VERSION ""

NS_ :

BS_:

BU_: Sound_A Ladegeraet_PAG_PF Motor_EDC17_Pirol PSM_Ant_Derivate GW_Routing_Derivate GW_Applikation_Derivate BMS_Hybrid Getriebe_Derivate LEH_Hybrid Motor_MED17_Hybrid Sound_I Tool Airbag Waehlhebel

BO_ 1446 OBC_Komponentenfehler: 8 Ladegeraet_PAG_PF
 SG_ OBC_KomponentenFehler_01 : 0|2@1+ (1,0) [0|3] ""  BMS_Hybrid
 SG_ OBC_KomponentenFehler_02 : 2|2@1+ (1,0) [0|3] ""  BMS_Hybrid
 SG_ OBC_KomponentenFehler_03 : 4|2@1+ (1,0) [0|3] ""  BMS_Hybrid
 SG_ OBC_KomponentenFehler_04 : 6|2@1+ (1,0) [0|3] ""  BMS_Hybrid
 SG_ OBC_KomponentenFehler_05 : 8|2@1+ (1,0) [0|3] ""  BMS_Hybrid
 SG_ OBC_KomponentenFehler_06 : 10|2@1+ (1,0) [0|3] ""  BMS_Hybrid
 SG_ OBC_KomponentenFehler_07 : 12|2@1+ (1,0) [0|3] ""  BMS_Hybrid
 SG_ OBC_KomponentenFehler_08 : 14|2@1+ (1,0) [0|3] ""  BMS_Hybrid
 SG_ OBC_KomponentenFehler_09 : 16|2@1+ (1,0) [0|3] ""  BMS_Hybrid
 SG_ OBC_KomponentenFehler_10 : 18|2@1+ (1,0) [0|3] ""  BMS_Hybrid
 SG_ OBC_KomponentenFehler_11 : 20|2@1+ (1,0) [0|3] ""  BMS_Hybrid
 SG_ OBC_KomponentenFehler_12 : 22|2@1+ (1,0) [0|3] ""  BMS_Hybrid
 SG_ OBC_KomponentenFehler_13 : 24|2@1+ (1,0) [0|3] ""  BMS_Hybrid
 SG_ OBC_KomponentenFehler_14 : 26|2@1+ (1,0) [0|3] ""  BMS_Hybrid
 SG_ OBC_KomponentenFehler_15 : 28|2@1+ (1,0) [0|3] ""  BMS_Hybrid
 SG_ OBC_KomponentenFehler_16 : 30|2@1+ (1,0) [0|3] ""  BMS_Hybrid
 SG_ OBC_KomponentenFehler_17 : 32|2@1+ (1,0) [0|3] ""  BMS_Hybrid
 SG_ OBC_KomponentenFehler_18 : 34|2@1+ (1,0) [0|3] ""  BMS_Hybrid
 SG_ OBC_KomponentenFehler_19 : 36|2@1+ (1,0) [0|3] ""  BMS_Hybrid
 SG_ OBC_KomponentenFehler_20 : 38|2@1+ (1,0) [0|3] ""  BMS_Hybrid
 SG_ OBC_KomponentenFehler_21 : 40|2@1+ (1,0) [0|3] ""  BMS_Hybrid
 SG_ OBC_KomponentenFehler_22 : 42|2@1+ (1,0) [0|3] ""  BMS_Hybrid
 SG_ OBC_KomponentenFehler_23 : 44|2@1+ (1,0) [0|3] ""  BMS_Hybrid
 SG_ OBC_KomponentenFehler_24 : 46|2@1+ (1,0) [0|3] ""  BMS_Hybrid
 SG_ OBC_KomponentenFehler_25 : 48|2@1+ (1,0) [0|3] ""  BMS_Hybrid
 SG_ OBC_KomponentenFehler_26 : 50|2@1+ (1,0) [0|3] ""  BMS_Hybrid
 SG_ OBC_KomponentenFehler_27 : 52|2@1+ (1,0) [0|3] ""  BMS_Hybrid
 SG_ OBC_KomponentenFehler_28 : 54|2@1+ (1,0) [0|3] ""  BMS_Hybrid
 SG_ OBC_KomponentenFehler_29 : 56|2@1+ (1,0) [0|3] ""  BMS_Hybrid
 SG_ OBC_KomponentenFehler_30 : 58|2@1+ (1,0) [0|3] ""  BMS_Hybrid
 SG_ OBC_KomponentenFehler_31 : 60|2@1+ (1,0) [0|3] ""  BMS_Hybrid
 SG_ OBC_KomponentenFehler_32 : 62|2@1+ (1,0) [0|3] ""  BMS_Hybrid

BO_ 1445 OBC_CALID_CVN: 8 Ladegeraet_PAG_PF
 SG_ OBC_CVN_VLD : 7|1@1+ (1,0) [0|1] ""  BMS_Hybrid
 SG_ OBC_CALID_Index_01 m0 : 8|8@1+ (1,0) [0|255] ""  BMS_Hybrid
 SG_ OBC_CALID_Index_05 m1 : 8|8@1+ (1,0) [0|255] ""  BMS_Hybrid
 SG_ OBC_CALID_Index_09 m2 : 8|8@1+ (1,0) [0|255] ""  BMS_Hybrid
 SG_ OBC_CALID_Index_13 m3 : 8|8@1+ (1,0) [0|255] ""  BMS_Hybrid
 SG_ OBC_CALID_Index_02 m0 : 16|8@1+ (1,0) [0|255] ""  BMS_Hybrid
 SG_ OBC_CALID_Index_06 m1 : 16|8@1+ (1,0) [0|255] ""  BMS_Hybrid
 SG_ OBC_CALID_Index_10 m2 : 16|8@1+ (1,0) [0|255] ""  BMS_Hybrid
 SG_ OBC_CALID_Index_14 m3 : 16|8@1+ (1,0) [0|255] ""  BMS_Hybrid
 SG_ OBC_CALID_Index_03 m0 : 24|8@1+ (1,0) [0|255] ""  BMS_Hybrid
 SG_ OBC_CALID_Index_07 m1 : 24|8@1+ (1,0) [0|255] ""  BMS_Hybrid
 SG_ OBC_CALID_Index_11 m2 : 24|8@1+ (1,0) [0|255] ""  BMS_Hybrid
 SG_ OBC_CALID_Index_15 m3 : 24|8@1+ (1,0) [0|255] ""  BMS_Hybrid
 SG_ OBC_CALID_Index_04 m0 : 32|8@1+ (1,0) [0|255] ""  BMS_Hybrid
 SG_ OBC_CALID_Index_08 m1 : 32|8@1+ (1,0) [0|255] ""  BMS_Hybrid
 SG_ OBC_CALID_Index_12 m2 : 32|8@1+ (1,0) [0|255] ""  BMS_Hybrid
 SG_ OBC_CALID_Index_16 m3 : 32|8@1+ (1,0) [0|255] ""  BMS_Hybrid
 SG_ OBC_CVN_Byte_1 m0 : 40|8@1+ (1,0) [0|255] ""  BMS_Hybrid
 SG_ OBC_CVN_Byte_2 m1 : 40|8@1+ (1,0) [0|255] ""  BMS_Hybrid
 SG_ OBC_CVN_Byte_3 m2 : 40|8@1+ (1,0) [0|255] ""  BMS_Hybrid
 SG_ OBC_CALID_CVN_MUX M : 0|2@1+ (1,0) [0|3] ""  BMS_Hybrid
 SG_ OBC_CVN_Byte_4 m3 : 40|8@1+ (1,0) [0|255] ""  BMS_Hybrid

BO_ 1666 CCP_LE_CRO_01: 8 Tool
 SG_ CCP_LE_CRO_01_Data : 0|64@1+ (1,0) [0|1] ""  LEH_Hybrid

BO_ 2617239041 CCP_EMotor_01_DTO_01: 8 LEH_Hybrid
 SG_ CCP_LE_DTO_01_Data : 0|64@1+ (1,0) [0|1] ""  Tool

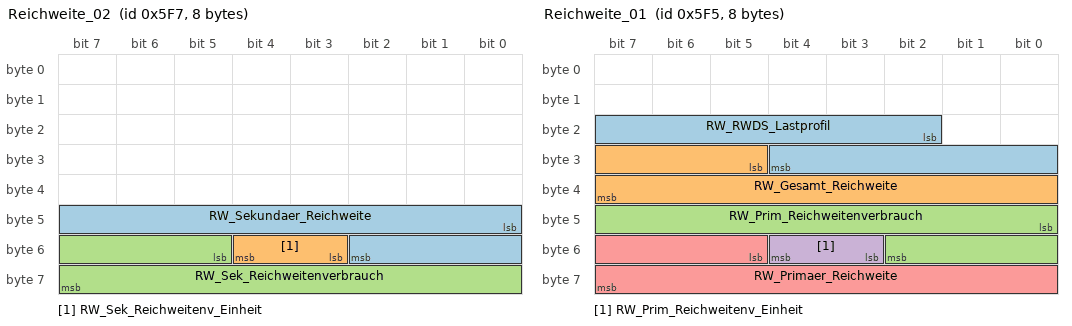
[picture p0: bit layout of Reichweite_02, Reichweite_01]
BO_ 1527 Reichweite_02: 8 BMS_Hybrid
 SG_ RW_Sekundaer_Reichweite : 40|11@1+ (1,0) [0|2044] "Unit_KiloMeter"  GW_Routing_Derivate
 SG_ RW_Sek_Reichweitenv_Einheit : 51|2@1+ (1,0) [0|3] ""  GW_Routing_Derivate
 SG_ RW_Sek_Reichweitenverbrauch : 53|11@1+ (0.1,0) [0|204.4] ""  GW_Routing_Derivate

BO_ 1525 Reichweite_01: 8 BMS_Hybrid
 SG_ RW_RWDS_Lastprofil : 18|11@1+ (1,0) [0|2045] "Unit_Amper"  GW_Routing_Derivate
 SG_ RW_Gesamt_Reichweite : 29|11@1+ (1,0) [0|2044] "Unit_KiloMeter"  GW_Routing_Derivate
 SG_ RW_Prim_Reichweitenverbrauch : 40|11@1+ (0.1,0) [0|204.4] ""  GW_Routing_Derivate
 SG_ RW_Prim_Reichweitenv_Einheit : 51|2@1+ (1,0) [0|3] ""  GW_Routing_Derivate
 SG_ RW_Primaer_Reichweite : 53|11@1+ (1,0) [0|2044] "Unit_KiloMeter"  GW_Routing_Derivate

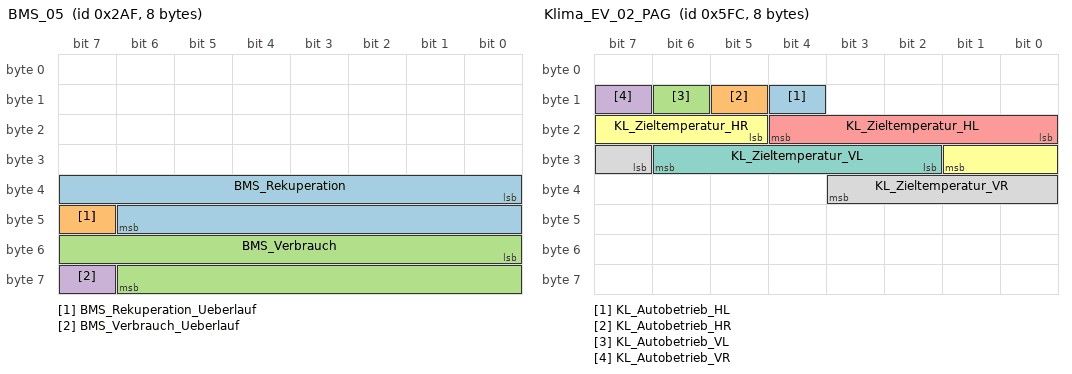
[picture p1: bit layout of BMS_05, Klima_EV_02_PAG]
BO_ 687 BMS_05: 8 BMS_Hybrid
 SG_ BMS_Rekuperation : 32|15@1+ (10,0) [0|327670] "Unit_WattSecond"  GW_Routing_Derivate
 SG_ BMS_Rekuperation_Ueberlauf : 47|1@1+ (1,0) [0|1] ""  GW_Routing_Derivate
 SG_ BMS_Verbrauch : 48|15@1+ (10,0) [0|327670] "Unit_WattSecond"  GW_Routing_Derivate
 SG_ BMS_Verbrauch_Ueberlauf : 63|1@1+ (1,0) [0|1] ""  GW_Routing_Derivate

BO_ 1532 Klima_EV_02_PAG: 8 GW_Routing_Derivate
 SG_ KL_Autobetrieb_HL : 12|1@1+ (1,0) [0|1] ""  BMS_Hybrid
 SG_ KL_Autobetrieb_HR : 13|1@1+ (1,0) [0|1] ""  BMS_Hybrid
 SG_ KL_Autobetrieb_VL : 14|1@1+ (1,0) [0|1] ""  BMS_Hybrid
 SG_ KL_Autobetrieb_VR : 15|1@1+ (1,0) [0|1] ""  BMS_Hybrid
 SG_ KL_Zieltemperatur_HL : 16|5@1+ (0.5,15.5) [16|29.5] "Unit_DegreCelsi"  BMS_Hybrid
 SG_ KL_Zieltemperatur_HR : 21|5@1+ (0.5,15.5) [16|29.5] "Unit_DegreCelsi"  BMS_Hybrid
 SG_ KL_Zieltemperatur_VL : 26|5@1+ (0.5,15.5) [16|29.5] "Unit_DegreCelsi"  BMS_Hybrid
 SG_ KL_Zieltemperatur_VR : 31|5@1+ (0.5,15.5) [16|29.5] "Unit_DegreCelsi"  BMS_Hybrid

BO_ 1788 NMH_Ladegeraet: 7 Ladegeraet_PAG_PF
 SG_ NMH_Ladegeraet_Start_1 : 0|1@1+ (1,0) [0|1] ""  Motor_MED17_Hybrid,GW_Applikation_Derivate,Getriebe_Derivate,LEH_Hybrid,BMS_Hybrid
 SG_ NMH_Ladegeraet_Start_2 : 1|1@1+ (1,0) [0|1] "" Vector__XXX
 SG_ NMH_Ladegeraet_Normal_Mode_1 : 2|1@1+ (1,0) [0|1] "" Vector__XXX
 SG_ NMH_Ladegeraet_Normal_Mode_2 : 3|1@1+ (1,0) [0|1] "" Vector__XXX
 SG_ NMH_Ladegeraet_Car_WakeUp : 6|1@1+ (1,0) [0|1] "" Vector__XXX
 SG_ NMH_Ladegeraet_Per_WakeUp : 8|5@1+ (1,0) [0|31] "" Vector__XXX
 SG_ NMH_Ladegeraet_Fkt_WakeUp : 13|3@1+ (1,0) [0|7] "" Vector__XXX
 SG_ NMH_Ladegeraet_Klemme_15 : 16|1@1+ (1,0) [0|1] "" Vector__XXX
 SG_ NMH_Ladegeraet_Diagnose : 17|1@1+ (1,0) [0|1] "" Vector__XXX
 SG_ NMH_Ladegeraet_MindestAktivZeit : 18|1@1+ (1,0) [0|1] "" Vector__XXX
 SG_ NMH_Ladegeraet_Signalfehler : 32|1@1+ (1,0) [0|1] "" Vector__XXX
 SG_ NMH_Ladegeraet_TimeOut_Fehler : 33|1@1+ (1,0) [0|1] "" Vector__XXX
 SG_ NMH_Ladegeraet_CAN_Diag_deaktiv : 34|1@1+ (1,0) [0|1] "" Vector__XXX
 SG_ NMH_Ladegeraet_KompSchutz : 35|1@1+ (1,0) [0|1] "" Vector__XXX
 SG_ NMH_Ladegeraet_Mute_Mode : 36|1@1+ (1,0) [0|1] "" Vector__XXX
 SG_ NMH_Ladegeraet_Transport_Mode : 37|1@1+ (1,0) [0|1] "" Vector__XXX
 SG_ NMH_Ladegeraet_Abschaltstufe_000 : 38|1@1+ (1,0) [0|1] "" Vector__XXX
 SG_ NMH_Ladegeraet_Eindraht_Fehler : 39|1@1+ (1,0) [0|1] "" Vector__XXX
 SG_ NMH_Ladegeraet_Lokalaktiv : 48|1@1+ (1,0) [0|1] "" Vector__XXX
 SG_ NMH_Ladegeraet_Subsystemaktiv : 49|1@1+ (1,0) [0|1] "" Vector__XXX

BO_ 1966 ISO_Ladegeraet_Resp: 8 Ladegeraet_PAG_PF
 SG_ ISO_Ladegeraet_Resp_Data : 0|64@1+ (1,0) [0|4294967295] ""  GW_Routing_Derivate

BO_ 1860 ISO_Ladegeraet_Req: 8 GW_Routing_Derivate
 SG_ ISO_Ladegeraet_Req_Data : 0|64@1+ (1,0) [0|4294967295] ""  Ladegeraet_PAG_PF

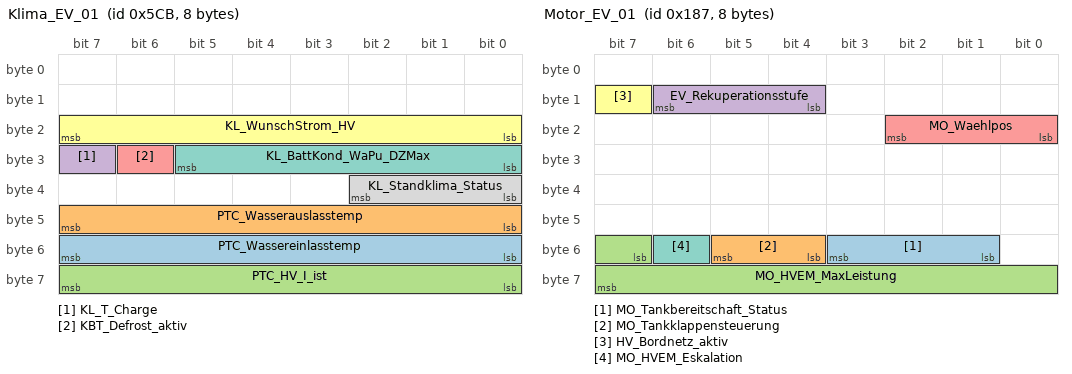
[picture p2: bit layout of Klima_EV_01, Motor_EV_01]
BO_ 1483 Klima_EV_01: 8 GW_Routing_Derivate
 SG_ PTC_Wassereinlasstemp : 48|8@1+ (1,-50) [-50|203] "Unit_DegreCelsi"  BMS_Hybrid
 SG_ PTC_Wasserauslasstemp : 40|8@1+ (1,-50) [-50|203] "Unit_DegreCelsi"  BMS_Hybrid
 SG_ PTC_HV_I_ist : 56|8@1+ (0.25,0) [0|63.25] "Unit_Amper"  Motor_MED17_Hybrid,BMS_Hybrid,Ladegeraet_PAG_PF
 SG_ KL_T_Charge : 31|1@1+ (1,0) [0|1] "" Vector__XXX
 SG_ KBT_Defrost_aktiv : 30|1@1+ (1,0) [0|1] ""  BMS_Hybrid
 SG_ KL_WunschStrom_HV : 16|8@1+ (0.25,0) [0|63.25] "Unit_Amper" Vector__XXX
 SG_ KL_BattKond_WaPu_DZMax : 24|6@1+ (2,0) [0|100] "Unit_PerCent"  BMS_Hybrid
 SG_ KL_Standklima_Status : 32|3@1+ (1,0) [0|7] ""  Ladegeraet_PAG_PF

BO_ 899 Charisma_05: 8 GW_Routing_Derivate
 SG_ CHA_Ziel_FahrPr_BMS : 12|3@1+ (1,0) [0|7] ""  BMS_Hybrid

BO_ 1518 Gateway_31_PAG: 8 GW_Routing_Derivate
 SG_ KL_T_STH : 28|1@1+ (1,0) [0|1] ""  Ladegeraet_PAG_PF
 SG_ Klima_08_PAG_alt : 3|1@1+ (1,0) [0|1] ""  Ladegeraet_PAG_PF

BO_ 391 Motor_EV_01: 8 Motor_MED17_Hybrid
 SG_ MO_Tankbereitschaft_Status : 49|3@1+ (1,0) [0|7] "" Vector__XXX
 SG_ MO_Tankklappensteuerung : 52|2@1+ (1,0) [0|3] "" Vector__XXX
 SG_ MO_HVEM_MaxLeistung : 55|9@1+ (50,0) [0|25450] "Unit_Watt"  GW_Applikation_Derivate
 SG_ EV_Rekuperationsstufe : 12|3@1+ (1,0) [0|7] "" Vector__XXX
 SG_ MO_Waehlpos : 16|3@1+ (1,0) [0|7] "" Vector__XXX
 SG_ HV_Bordnetz_aktiv : 15|1@1+ (1,0) [0|1] ""  Ladegeraet_PAG_PF,GW_Applikation_Derivate
 SG_ MO_HVEM_Eskalation : 54|1@1+ (1,0) [0|1] ""  GW_Applikation_Derivate

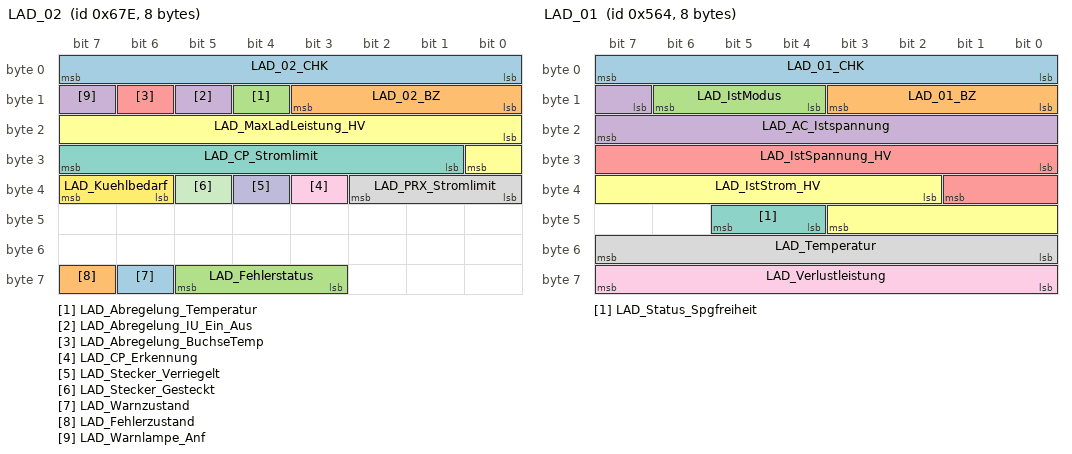
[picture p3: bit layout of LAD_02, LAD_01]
BO_ 1662 LAD_02: 8 Ladegeraet_PAG_PF
 SG_ LAD_02_CHK : 0|8@1+ (1,0) [0|255] ""  GW_Routing_Derivate
 SG_ LAD_02_BZ : 8|4@1+ (1,0) [0|15] ""  GW_Routing_Derivate
 SG_ LAD_Abregelung_Temperatur : 12|1@1+ (1,0) [0|1] ""  GW_Routing_Derivate
 SG_ LAD_Abregelung_IU_Ein_Aus : 13|1@1+ (1,0) [0|1] ""  GW_Routing_Derivate
 SG_ LAD_Abregelung_BuchseTemp : 14|1@1+ (1,0) [0|1] ""  GW_Routing_Derivate
 SG_ LAD_MaxLadLeistung_HV : 16|9@1+ (100,0) [0|50900] "Unit_Watt"  GW_Routing_Derivate,GW_Applikation_Derivate
 SG_ LAD_CP_Stromlimit : 25|7@1+ (0.5,0) [0|62.5] "Unit_Amper"  GW_Routing_Derivate
 SG_ LAD_PRX_Stromlimit : 32|3@1+ (1,0) [0|7] ""  GW_Routing_Derivate
 SG_ LAD_CP_Erkennung : 35|1@1+ (1,0) [0|1] ""  GW_Routing_Derivate
 SG_ LAD_Stecker_Verriegelt : 36|1@1+ (1,0) [0|1] ""  GW_Routing_Derivate
 SG_ LAD_Stecker_Gesteckt : 37|1@1+ (1,0) [0|1] ""  GW_Routing_Derivate
 SG_ LAD_Kuehlbedarf : 38|2@1+ (1,0) [0|3] ""  GW_Routing_Derivate
 SG_ LAD_Warnzustand : 62|1@1+ (1,0) [0|1] ""  GW_Routing_Derivate
 SG_ LAD_Fehlerzustand : 63|1@1+ (1,0) [0|1] ""  GW_Routing_Derivate
 SG_ LAD_Fehlerstatus : 59|3@1+ (1,0) [0|7] ""  GW_Routing_Derivate
 SG_ LAD_Warnlampe_Anf : 15|1@1+ (1,0) [0|1] ""  GW_Routing_Derivate

BO_ 1380 LAD_01: 8 Ladegeraet_PAG_PF
 SG_ LAD_01_CHK : 0|8@1+ (1,0) [0|255] ""  GW_Routing_Derivate
 SG_ LAD_01_BZ : 8|4@1+ (1,0) [0|15] ""  GW_Routing_Derivate
 SG_ LAD_IstModus : 12|3@1+ (1,0) [0|7] ""  GW_Applikation_Derivate,GW_Routing_Derivate
 SG_ LAD_AC_Istspannung : 15|9@1+ (1,0) [0|509] "Unit_Volt"  GW_Routing_Derivate,GW_Applikation_Derivate
 SG_ LAD_IstSpannung_HV : 24|10@1+ (1,0) [0|1021] "Unit_Volt"  GW_Routing_Derivate
 SG_ LAD_IstStrom_HV : 34|10@1+ (0.2,-102) [-102|102.2] "Unit_Amper"  GW_Applikation_Derivate,GW_Routing_Derivate
 SG_ LAD_Status_Spgfreiheit : 44|2@1+ (1,0) [0|3] ""  GW_Routing_Derivate
 SG_ LAD_Temperatur : 48|8@1+ (1,-40) [-40|213] "Unit_DegreCelsi"  GW_Routing_Derivate
 SG_ LAD_Verlustleistung : 56|8@1+ (20,0) [0|5060] "Unit_Watt"  GW_Routing_Derivate

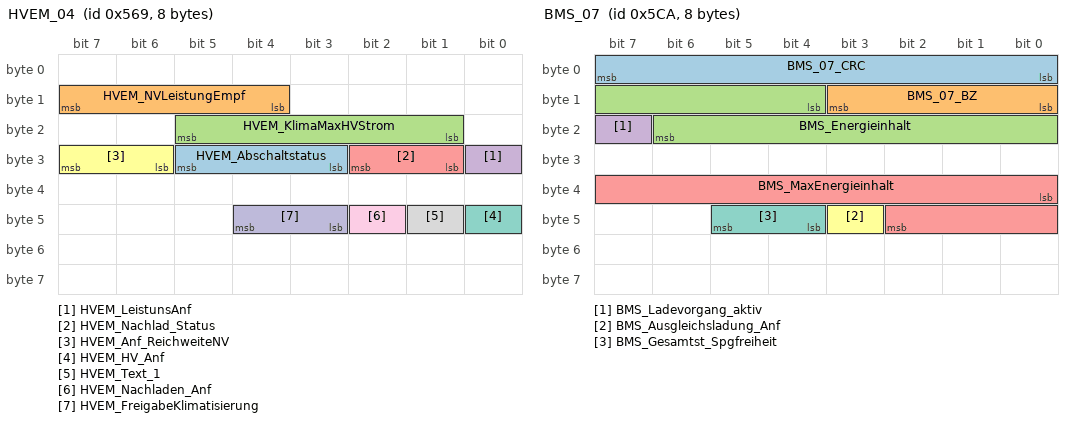
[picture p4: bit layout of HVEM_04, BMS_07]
BO_ 1385 HVEM_04: 8 GW_Applikation_Derivate
 SG_ HVEM_Abschaltstatus : 27|3@1+ (1,0) [0|7] ""  Ladegeraet_PAG_PF
 SG_ HVEM_NVLeistungEmpf : 12|4@1+ (100,0) [0|1500] "Unit_Watt" Vector__XXX
 SG_ HVEM_KlimaMaxHVStrom : 17|5@1+ (1,0) [0|31] "Unit_Amper" Vector__XXX
 SG_ HVEM_LeistunsAnf : 24|1@1+ (1,0) [0|1] "" Vector__XXX
 SG_ HVEM_Nachlad_Status : 25|2@1+ (1,0) [0|3] "" Vector__XXX
 SG_ HVEM_Anf_ReichweiteNV : 30|2@1+ (1,0) [0|3] "" Vector__XXX
 SG_ HVEM_HV_Anf : 40|1@1+ (1,0) [0|1] ""  Motor_MED17_Hybrid
 SG_ HVEM_Text_1 : 41|1@1+ (1,0) [0|1] "" Vector__XXX
 SG_ HVEM_Nachladen_Anf : 42|1@1+ (1,0) [0|1] ""  Ladegeraet_PAG_PF
 SG_ HVEM_FreigabeKlimatisierung : 43|2@1+ (1,0) [0|3] ""  BMS_Hybrid

BO_ 1482 BMS_07: 8 BMS_Hybrid
 SG_ BMS_07_CRC : 0|8@1+ (1,0) [0|255] ""  GW_Routing_Derivate
 SG_ BMS_07_BZ : 8|4@1+ (1,0) [0|15] ""  GW_Routing_Derivate
 SG_ BMS_Energieinhalt : 12|11@1+ (50,0) [0|102250] "Unit_WattHour"  GW_Routing_Derivate
 SG_ BMS_Ladevorgang_aktiv : 23|1@1+ (1,0) [0|1] ""  GW_Routing_Derivate
 SG_ BMS_MaxEnergieinhalt : 32|11@1+ (50,0) [0|102250] ""  GW_Routing_Derivate
 SG_ BMS_Ausgleichsladung_Anf : 43|1@1+ (1,0) [0|1] ""  GW_Routing_Derivate
 SG_ BMS_Gesamtst_Spgfreiheit : 44|2@1+ (1,0) [0|3] ""  GW_Routing_Derivate

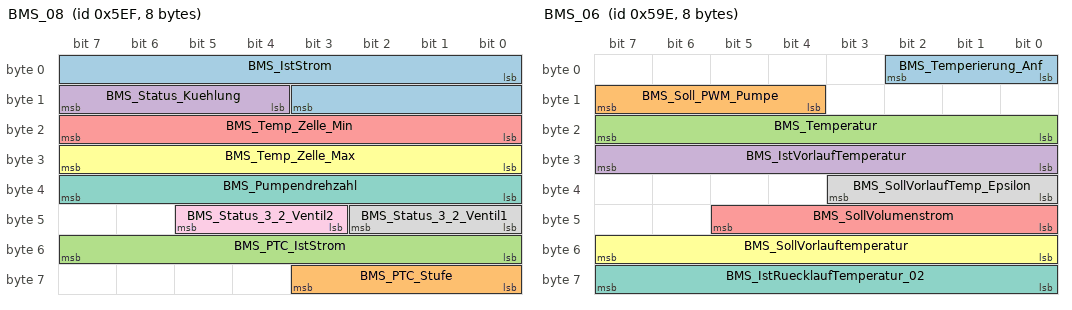
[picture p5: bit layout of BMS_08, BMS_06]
BO_ 1519 BMS_08: 8 BMS_Hybrid
 SG_ BMS_IstStrom : 0|12@1+ (0.25,-511) [-511|512.25] "Unit_Amper"  GW_Applikation_Derivate,GW_Routing_Derivate
 SG_ BMS_PTC_Stufe : 56|4@1+ (10,0) [0|100] "Unit_PerCent"  GW_Routing_Derivate
 SG_ BMS_PTC_IstStrom : 48|8@1+ (0.1,0) [0|25.2] "Unit_Amper"  Motor_MED17_Hybrid,GW_Applikation_Derivate,GW_Routing_Derivate
 SG_ BMS_Status_Kuehlung : 12|4@1+ (1,0) [0|15] ""  GW_Routing_Derivate,GW_Applikation_Derivate
 SG_ BMS_Temp_Zelle_Min : 16|8@1+ (0.5,-40) [-40|86.5] "Unit_DegreCelsi"  GW_Routing_Derivate
 SG_ BMS_Temp_Zelle_Max : 24|8@1+ (0.5,-40) [-40|86.5] "Unit_DegreCelsi"  GW_Routing_Derivate
 SG_ BMS_Pumpendrehzahl : 32|8@1+ (0.5,0) [0|100] "Unit_PerCent"  GW_Routing_Derivate
 SG_ BMS_Status_3_2_Ventil1 : 40|3@1+ (1,0) [0|7] ""  GW_Routing_Derivate
 SG_ BMS_Status_3_2_Ventil2 : 43|3@1+ (1,0) [0|7] ""  GW_Routing_Derivate

BO_ 1438 BMS_06: 8 BMS_Hybrid
 SG_ BMS_Temperierung_Anf : 0|3@1+ (1,0) [0|7] ""  GW_Routing_Derivate
 SG_ BMS_Soll_PWM_Pumpe : 12|4@1+ (10,0) [0|100] "Unit_PerCent"  GW_Routing_Derivate
 SG_ BMS_Temperatur : 16|8@1+ (0.5,-40) [-40|86.5] "Unit_DegreCelsi"  GW_Routing_Derivate
 SG_ BMS_IstVorlaufTemperatur : 24|8@1+ (0.5,-40) [-40|86.5] "Unit_DegreCelsi"  GW_Routing_Derivate
 SG_ BMS_SollVolumenstrom : 40|6@1+ (1,0) [0|61] ""  GW_Routing_Derivate
 SG_ BMS_SollVorlauftemperatur : 48|8@1+ (0.5,-40) [-40|86.5] "Unit_DegreCelsi"  GW_Routing_Derivate
 SG_ BMS_IstRuecklaufTemperatur_02 : 56|8@1+ (0.5,-40) [-40|86.5] "Unit_DegreCelsi"  GW_Routing_Derivate
 SG_ BMS_SollVorlaufTemp_Epsilon : 32|4@1+ (2,0) [0|30] "Unit_DegreCelsi"  GW_Routing_Derivate

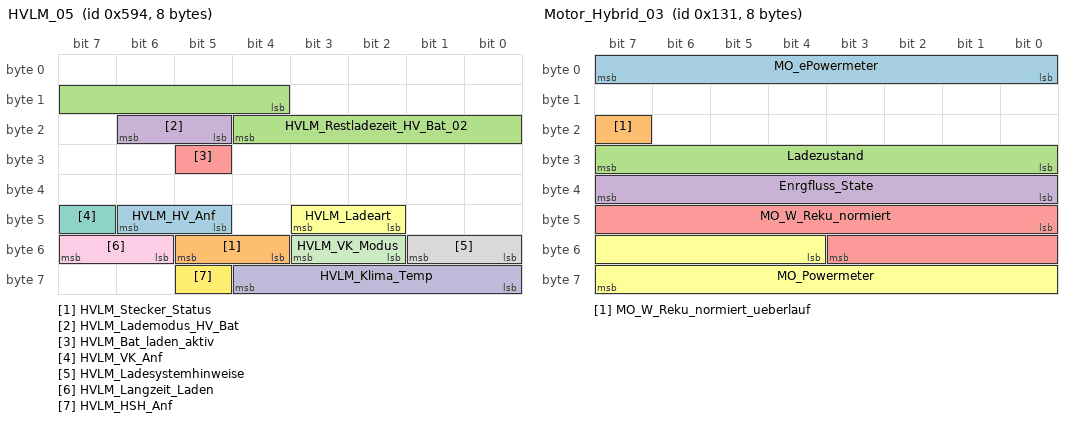
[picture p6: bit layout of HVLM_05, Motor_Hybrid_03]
BO_ 1428 HVLM_05: 8 Ladegeraet_PAG_PF
 SG_ HVLM_HV_Anf : 45|2@1+ (1,0) [0|3] ""  GW_Applikation_Derivate,GW_Routing_Derivate
 SG_ HVLM_Stecker_Status : 52|2@1+ (1,0) [0|3] ""  GW_Applikation_Derivate,BMS_Hybrid,GW_Routing_Derivate
 SG_ HVLM_Restladezeit_HV_Bat_02 : 12|9@1+ (5,0) [0|2545] "Unit_Minut"  GW_Routing_Derivate
 SG_ HVLM_Lademodus_HV_Bat : 21|2@1+ (1,0) [0|3] ""  GW_Routing_Derivate
 SG_ HVLM_Bat_laden_aktiv : 29|1@1+ (1,0) [0|1] ""  GW_Applikation_Derivate,GW_Routing_Derivate
 SG_ HVLM_Ladeart : 42|2@1+ (1,0) [0|3] ""  GW_Routing_Derivate
 SG_ HVLM_VK_Anf : 47|1@1+ (1,0) [0|1] ""  GW_Applikation_Derivate,GW_Routing_Derivate
 SG_ HVLM_Ladesystemhinweise : 48|2@1+ (1,0) [0|3] ""  GW_Routing_Derivate
 SG_ HVLM_Langzeit_Laden : 54|2@1+ (1,0) [0|3] ""  GW_Routing_Derivate,BMS_Hybrid
 SG_ HVLM_Klima_Temp : 56|5@1+ (0.5,15.5) [15.5|29.5] "Unit_DegreCelsi"  GW_Routing_Derivate
 SG_ HVLM_VK_Modus : 50|2@1+ (1,0) [0|3] ""  GW_Routing_Derivate
 SG_ HVLM_HSH_Anf : 61|1@1+ (1,0) [0|1] ""  GW_Routing_Derivate

BO_ 305 Motor_Hybrid_03: 8 Motor_MED17_Hybrid
 SG_ MO_ePowermeter : 0|8@1+ (0.4,-0.4) [0|100.8] "Unit_PerCent"  GW_Routing_Derivate
 SG_ MO_W_Reku_normiert_ueberlauf : 23|1@1+ (1,0) [0|1] ""  GW_Routing_Derivate
 SG_ Ladezustand : 24|8@1+ (1,0) [0|100] "Unit_PerCent"  Ladegeraet_PAG_PF,GW_Routing_Derivate,GW_Applikation_Derivate
 SG_ Enrgfluss_State : 32|8@1+ (1,0) [0|255] ""  GW_Routing_Derivate
 SG_ MO_W_Reku_normiert : 40|12@1+ (10,0) [0|40950] "Unit_WattSecond"  GW_Routing_Derivate
 SG_ MO_Powermeter : 52|12@1+ (1,0) [0|4092] ""  GW_Routing_Derivate

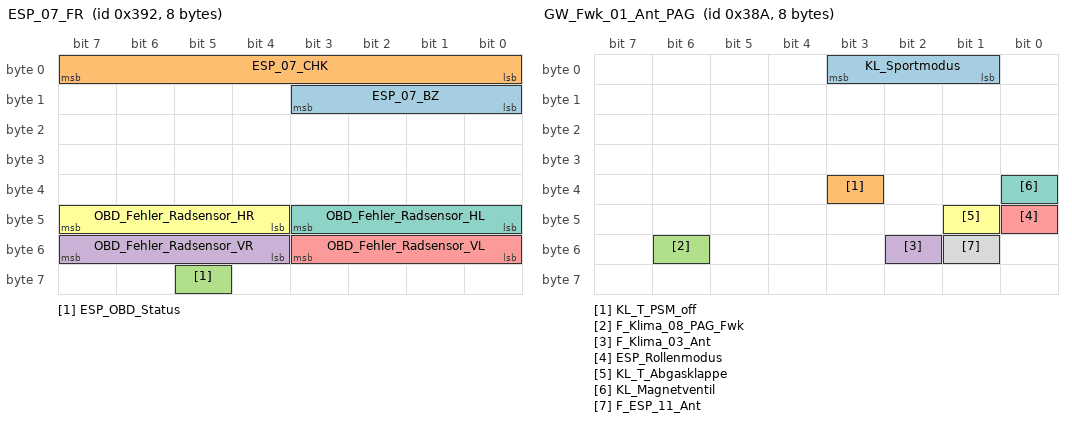
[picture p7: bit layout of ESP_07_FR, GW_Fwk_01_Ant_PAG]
BO_ 914 ESP_07_FR: 8 PSM_Ant_Derivate
 SG_ ESP_07_BZ : 8|4@1+ (1,0) [0|15] ""  Motor_MED17_Hybrid
 SG_ ESP_07_CHK : 0|8@1+ (1,0) [0|255] ""  Motor_MED17_Hybrid
 SG_ ESP_OBD_Status : 61|1@1+ (1,0) [0|1] ""  Motor_MED17_Hybrid
 SG_ OBD_Fehler_Radsensor_VR : 52|4@1+ (1,0) [0|15] ""  Motor_MED17_Hybrid
 SG_ OBD_Fehler_Radsensor_VL : 48|4@1+ (1,0) [0|15] ""  Motor_MED17_Hybrid
 SG_ OBD_Fehler_Radsensor_HR : 44|4@1+ (1,0) [0|15] ""  Motor_MED17_Hybrid
 SG_ OBD_Fehler_Radsensor_HL : 40|4@1+ (1,0) [0|15] ""  Motor_MED17_Hybrid

BO_ 906 GW_Fwk_01_Ant_PAG: 8 GW_Routing_Derivate
 SG_ KL_Sportmodus : 1|3@1+ (1,0) [0|7] "" Vector__XXX
 SG_ KL_T_PSM_off : 35|1@1+ (1,0) [0|1] ""  Getriebe_Derivate
 SG_ F_Klima_08_PAG_Fwk : 54|1@1+ (1,0) [0|1] ""  Motor_EDC17_Pirol,Getriebe_Derivate
 SG_ F_Klima_03_Ant : 50|1@1+ (1,0) [0|1] "" Vector__XXX
 SG_ ESP_Rollenmodus : 40|1@1+ (1,0) [0|1] "" Vector__XXX
 SG_ KL_T_Abgasklappe : 41|1@1+ (1,0) [0|1] ""  Motor_EDC17_Pirol
 SG_ KL_Magnetventil : 32|1@1+ (1,0) [0|1] "" Vector__XXX
 SG_ F_ESP_11_Ant : 49|1@1+ (1,0) [0|1] "" Vector__XXX

BO_ 1731 NMH_ESP: 7 PSM_Ant_Derivate
 SG_ NMH_ESP_Start_1 : 0|1@1+ (1,0) [0|1] ""  GW_Applikation_Derivate,Getriebe_Derivate,Motor_MED17_Hybrid,Motor_EDC17_Pirol,LEH_Hybrid,Ladegeraet_PAG_PF,BMS_Hybrid
 SG_ NMH_ESP_Start_2 : 1|1@1+ (1,0) [0|1] "" Vector__XXX
 SG_ NMH_ESP_Normal_Mode_1 : 2|1@1+ (1,0) [0|1] "" Vector__XXX
 SG_ NMH_ESP_Normal_Mode_2 : 3|1@1+ (1,0) [0|1] "" Vector__XXX
 SG_ NMH_ESP_Car_WakeUp : 6|1@1+ (1,0) [0|1] "" Vector__XXX
 SG_ NMH_ESP_Per_WakeUp : 8|5@1+ (1,0) [0|31] "" Vector__XXX
 SG_ NMH_ESP_Fkt_WakeUp : 13|3@1+ (1,0) [0|7] "" Vector__XXX
 SG_ NMH_ESP_NM_aktiv_Klemme_15 : 16|1@1+ (1,0) [0|1] "" Vector__XXX
 SG_ NMH_ESP_NM_aktiv_Diagnose : 17|1@1+ (1,0) [0|1] "" Vector__XXX
 SG_ NMH_ESP_NM_aktiv_Start : 18|1@1+ (1,0) [0|1] "" Vector__XXX
 SG_ NMH_ESP_NM_aktiv_v_groesser_Null : 19|1@1+ (1,0) [0|1] "" Vector__XXX
 SG_ NMH_ESP_Mindestaktivzeit : 21|1@1+ (1,0) [0|1] "" Vector__XXX
 SG_ NMH_ESP_kein_NL : 24|1@1+ (1,0) [0|1] "" Vector__XXX
 SG_ NMH_ESP_NL_Daten_EEPROM : 25|1@1+ (1,0) [0|1] "" Vector__XXX
 SG_ NMH_ESP_TimeOut_Fehler : 33|1@1+ (1,0) [0|1] "" Vector__XXX
 SG_ NMH_ESP_CAN_Diag_deaktiv : 34|1@1+ (1,0) [0|1] "" Vector__XXX
 SG_ NMH_ESP_KompSchutz : 35|1@1+ (1,0) [0|1] "" Vector__XXX
 SG_ NMH_ESP_Mute_Mode : 36|1@1+ (1,0) [0|1] "" Vector__XXX
 SG_ NMH_ESP_Transport_Mode : 37|1@1+ (1,0) [0|1] "" Vector__XXX
 SG_ NMH_ESP_Abschaltstufe_aktiv : 38|1@1+ (1,0) [0|1] "" Vector__XXX
 SG_ NMH_ESP_Eindraht_Fehler : 39|1@1+ (1,0) [0|1] "" Vector__XXX
 SG_ NMH_ESP_interne_Zust : 40|8@1+ (1,0) [0|255] "" Vector__XXX
 SG_ NMH_ESP_Lokalaktiv : 48|1@1+ (1,0) [0|1] "" Vector__XXX
 SG_ NMH_ESP_Subsystemaktiv : 49|1@1+ (1,0) [0|1] "" Vector__XXX

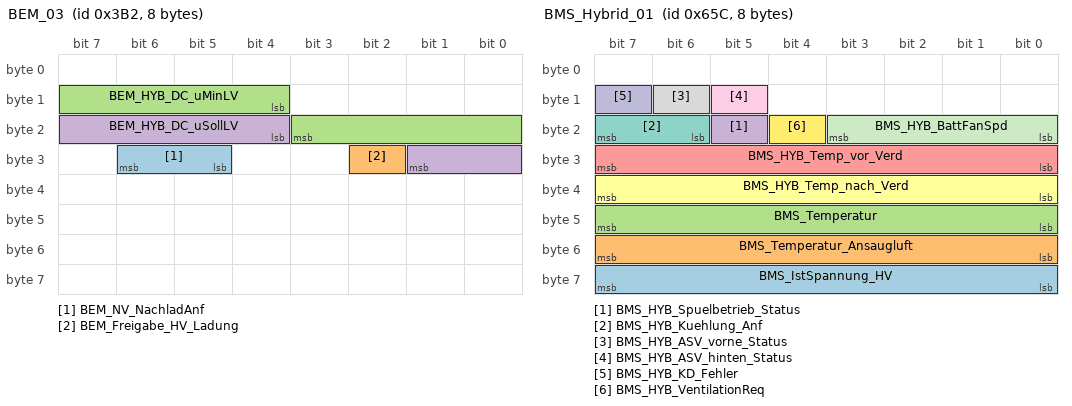
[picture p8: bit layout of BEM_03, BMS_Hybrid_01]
BO_ 946 BEM_03: 8 GW_Applikation_Derivate
 SG_ BEM_NV_NachladAnf : 29|2@1+ (1,0) [0|3] ""  Ladegeraet_PAG_PF
 SG_ BEM_Freigabe_HV_Ladung : 26|1@1+ (1,0) [0|1] "" Vector__XXX
 SG_ BEM_HYB_DC_uMinLV : 12|8@1+ (0.1,0) [0|25.3] "Unit_Volt"  LEH_Hybrid
 SG_ BEM_HYB_DC_uSollLV : 20|6@1+ (0.1,10.6) [10.6|16] "Unit_Volt"  LEH_Hybrid

BO_ 1628 BMS_Hybrid_01: 8 BMS_Hybrid
 SG_ BMS_IstSpannung_HV : 56|8@1+ (1,100) [100|350] "Unit_Volt"  GW_Routing_Derivate
 SG_ BMS_Temperatur_Ansaugluft : 48|8@1+ (0.5,-40) [-40|86.5] "Unit_DegreCelsi"  GW_Routing_Derivate
 SG_ BMS_Temperatur : 40|8@1+ (0.5,-40) [-40|86.5] "Unit_DegreCelsi"  GW_Routing_Derivate
 SG_ BMS_HYB_Spuelbetrieb_Status : 21|1@1+ (1,0) [0|1] ""  GW_Routing_Derivate
 SG_ BMS_HYB_Temp_vor_Verd : 24|8@1+ (0.5,-40) [-40|86.5] "Unit_DegreCelsi"  GW_Routing_Derivate
 SG_ BMS_HYB_Temp_nach_Verd : 32|8@1+ (0.5,-40) [-40|86.5] "Unit_DegreCelsi"  GW_Routing_Derivate
 SG_ BMS_HYB_Kuehlung_Anf : 22|2@1+ (1,0) [0|3] ""  GW_Applikation_Derivate,GW_Routing_Derivate
 SG_ BMS_HYB_ASV_vorne_Status : 14|1@1+ (1,0) [0|1] ""  GW_Routing_Derivate
 SG_ BMS_HYB_ASV_hinten_Status : 13|1@1+ (1,0) [0|1] ""  GW_Routing_Derivate
 SG_ BMS_HYB_KD_Fehler : 15|1@1+ (1,0) [0|1] ""  GW_Applikation_Derivate,GW_Routing_Derivate
 SG_ BMS_HYB_BattFanSpd : 16|4@1+ (10,0) [0|100] "Unit_PerCent"  GW_Routing_Derivate
 SG_ BMS_HYB_VentilationReq : 20|1@1+ (1,0) [0|1] ""  GW_Routing_Derivate

BO_ 490 CCP_GE_DTO_01: 8 Getriebe_Derivate
 SG_ CCP_GE_DTO_01_Data : 0|64@1+ (1,0) [0|1] ""  Tool

BO_ 488 CCP_MO_DTO_01: 8 Motor_MED17_Hybrid
 SG_ CCP_MO_DTO_01_Data : 0|64@1+ (1,0) [0|1] ""  Tool

BO_ 2616986625 CCP_MO_DTO_02: 8 Motor_MED17_Hybrid
 SG_ CCP_MO_DTO_02_Data : 0|64@1+ (1,0) [0|1] ""  Tool

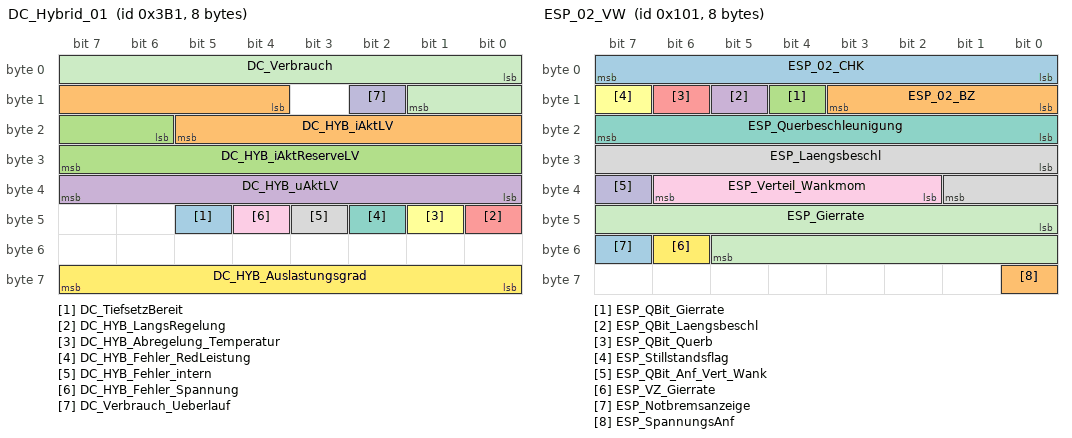
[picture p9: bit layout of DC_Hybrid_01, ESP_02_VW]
BO_ 945 DC_Hybrid_01: 8 LEH_Hybrid
 SG_ DC_TiefsetzBereit : 45|1@1+ (1,0) [0|1] ""  GW_Applikation_Derivate
 SG_ DC_HYB_iAktLV : 12|10@1+ (1,-511) [-511|512] "Unit_Amper"  GW_Applikation_Derivate
 SG_ DC_HYB_iAktReserveLV : 22|10@1+ (1,-511) [-511|512] "Unit_Amper"  GW_Applikation_Derivate
 SG_ DC_HYB_uAktLV : 32|8@1+ (0.1,0) [0|25.3] "Unit_Volt"  GW_Applikation_Derivate
 SG_ DC_HYB_LangsRegelung : 40|1@1+ (1,0) [0|1] "" Vector__XXX
 SG_ DC_HYB_Abregelung_Temperatur : 41|1@1+ (1,0) [0|1] ""  GW_Applikation_Derivate
 SG_ DC_HYB_Fehler_RedLeistung : 42|1@1+ (1,0) [0|1] ""  GW_Applikation_Derivate
 SG_ DC_HYB_Fehler_intern : 43|1@1+ (1,0) [0|1] ""  GW_Applikation_Derivate
 SG_ DC_HYB_Fehler_Spannung : 44|1@1+ (1,0) [0|1] ""  GW_Applikation_Derivate
 SG_ DC_Verbrauch_Ueberlauf : 10|1@1+ (1,0) [0|1] "" Vector__XXX
 SG_ DC_Verbrauch : 0|10@1+ (1,0) [0|1023] "Unit_WattSecond" Vector__XXX
 SG_ DC_HYB_Auslastungsgrad : 56|8@1+ (0.4,0) [0|100] "Unit_PerCent"  GW_Applikation_Derivate

BO_ 1627 EM_Hybrid_01: 8 LEH_Hybrid
 SG_ EM_HYB_KD_Fehler : 15|1@1+ (1,0) [0|1] "" Vector__XXX

BO_ 256 ESP_01_VW: 8 PSM_Ant_Derivate
 SG_ ESP_v_Signal : 32|16@1+ (0.01,0) [0|655.32] "km/h"  Motor_EDC17_Pirol,GW_Routing_Derivate,Getriebe_Derivate,Motor_MED17_Hybrid,LEH_Hybrid,BMS_Hybrid,GW_Applikation_Derivate
 SG_ ESP_01_CHK : 0|8@1+ (1,0) [0|255] ""  Motor_EDC17_Pirol,GW_Routing_Derivate,BMS_Hybrid,LEH_Hybrid,Getriebe_Derivate,Motor_MED17_Hybrid
 SG_ ESP_01_BZ : 8|4@1+ (1,0) [0|15] ""  Motor_EDC17_Pirol,GW_Routing_Derivate,LEH_Hybrid,Getriebe_Derivate,Motor_MED17_Hybrid,BMS_Hybrid
 SG_ ASR_Moment_langsam : 12|10@1+ (1,0) [0|1021] ""  Motor_EDC17_Pirol,GW_Routing_Derivate,Motor_MED17_Hybrid
 SG_ ASR_MSR_Moment_schnell : 22|10@1+ (1,0) [0|1021] ""  Motor_EDC17_Pirol,GW_Routing_Derivate,Motor_MED17_Hybrid
 SG_ ASR_Tastung_passiv : 48|1@1+ (1,0) [0|1] ""  Motor_EDC17_Pirol,GW_Routing_Derivate,Getriebe_Derivate,Motor_MED17_Hybrid
 SG_ ESP_Tastung_passiv : 49|1@1+ (1,0) [0|1] ""  Motor_EDC17_Pirol,GW_Routing_Derivate,Getriebe_Derivate,Motor_MED17_Hybrid
 SG_ ESP_Systemstatus : 50|1@1+ (1,0) [0|1] ""  Motor_EDC17_Pirol,GW_Routing_Derivate,Motor_MED17_Hybrid,Getriebe_Derivate
 SG_ ASR_Schalteingriff : 51|2@1+ (1,0) [0|3] ""  GW_Routing_Derivate,Getriebe_Derivate
 SG_ OBD_Schlechtweg : 53|1@1+ (1,0) [0|1] ""  GW_Routing_Derivate
 SG_ OBD_QBit_Schlechtweg : 54|1@1+ (1,0) [0|1] ""  GW_Routing_Derivate
 SG_ ESP_QBit_v_Signal : 55|1@1+ (1,0) [0|1] ""  BMS_Hybrid,Motor_EDC17_Pirol,GW_Routing_Derivate,LEH_Hybrid,Motor_MED17_Hybrid
 SG_ ABS_Bremsung : 56|1@1+ (1,0) [0|1] ""  Motor_EDC17_Pirol,GW_Routing_Derivate,Getriebe_Derivate,Motor_MED17_Hybrid
 SG_ ASR_Anf : 57|1@1+ (1,0) [0|1] ""  Motor_EDC17_Pirol,GW_Routing_Derivate,Getriebe_Derivate,Motor_MED17_Hybrid
 SG_ MSR_Anf : 58|1@1+ (1,0) [0|1] ""  Motor_EDC17_Pirol,GW_Routing_Derivate,Getriebe_Derivate,Motor_MED17_Hybrid
 SG_ EBV_Eingriff : 59|1@1+ (1,0) [0|1] ""  Motor_EDC17_Pirol,GW_Routing_Derivate,Motor_MED17_Hybrid
 SG_ EDS_Eingriff : 60|1@1+ (1,0) [0|1] ""  Motor_EDC17_Pirol,GW_Routing_Derivate,Getriebe_Derivate,Motor_MED17_Hybrid
 SG_ ESP_Eingriff : 61|1@1+ (1,0) [0|1] ""  Motor_EDC17_Pirol,GW_Routing_Derivate,Getriebe_Derivate,Motor_MED17_Hybrid
 SG_ ESP_ASP : 62|1@1+ (1,0) [0|1] ""  Motor_EDC17_Pirol,GW_Routing_Derivate,Motor_MED17_Hybrid
 SG_ ESP_KD_Fehler : 63|1@1+ (1,0) [0|1] ""  GW_Applikation_Derivate,GW_Routing_Derivate

BO_ 257 ESP_02_VW: 8 PSM_Ant_Derivate
 SG_ ESP_02_CHK : 0|8@1+ (1,0) [0|255] ""  Motor_EDC17_Pirol,GW_Routing_Derivate,Getriebe_Derivate,Motor_MED17_Hybrid
 SG_ ESP_02_BZ : 8|4@1+ (1,0) [0|15] ""  Motor_EDC17_Pirol,GW_Routing_Derivate,Getriebe_Derivate,Motor_MED17_Hybrid
 SG_ ESP_QBit_Gierrate : 12|1@1+ (1,0) [0|1] ""  GW_Routing_Derivate
 SG_ ESP_QBit_Laengsbeschl : 13|1@1+ (1,0) [0|1] ""  Motor_EDC17_Pirol,GW_Routing_Derivate,Motor_MED17_Hybrid
 SG_ ESP_QBit_Querb : 14|1@1+ (1,0) [0|1] ""  Motor_EDC17_Pirol,GW_Routing_Derivate,Motor_MED17_Hybrid
 SG_ ESP_Stillstandsflag : 15|1@1+ (1,0) [0|1] ""  Motor_EDC17_Pirol,GW_Routing_Derivate,Motor_MED17_Hybrid
 SG_ ESP_Querbeschleunigung : 16|8@1+ (0.01,-1.27) [-1.27|1.27] "Unit_ForceOfGravi"  Motor_EDC17_Pirol,GW_Routing_Derivate,Getriebe_Derivate,Motor_MED17_Hybrid
 SG_ ESP_Laengsbeschl : 24|10@1+ (0.03125,-16) [-16|15.90625] ""  Motor_EDC17_Pirol,GW_Routing_Derivate,Getriebe_Derivate,Motor_MED17_Hybrid
 SG_ ESP_Verteil_Wankmom : 34|5@1+ (0.1,-1) [-1|1] ""  GW_Routing_Derivate
 SG_ ESP_QBit_Anf_Vert_Wank : 39|1@1+ (1,0) [0|1] ""  GW_Routing_Derivate
 SG_ ESP_Gierrate : 40|14@1+ (0.01,0) [0|163.82] "Unit_DegreOfArcPerSecon"  GW_Routing_Derivate
 SG_ ESP_VZ_Gierrate : 54|1@1+ (1,0) [0|1] ""  GW_Routing_Derivate
 SG_ ESP_Notbremsanzeige : 55|1@1+ (1,0) [0|1] ""  GW_Routing_Derivate
 SG_ ESP_SpannungsAnf : 56|1@1+ (1,0) [0|1] ""  GW_Routing_Derivate

BO_ 1795 ISO_Funktionaler_Req_Abgas: 8 GW_Routing_Derivate
 SG_ ISO_Functionaler_Req_Abgas : 0|64@1+ (1,0) [0|1] ""  Ladegeraet_PAG_PF,BMS_Hybrid,Motor_EDC17_Pirol,Motor_MED17_Hybrid,Getriebe_Derivate,LEH_Hybrid

BO_ 482 CCP_GE_CR0_01: 8 GW_Routing_Derivate
 SG_ CCP_GE_CRO_01_Data : 0|64@1+ (1,0) [0|1] ""  Getriebe_Derivate

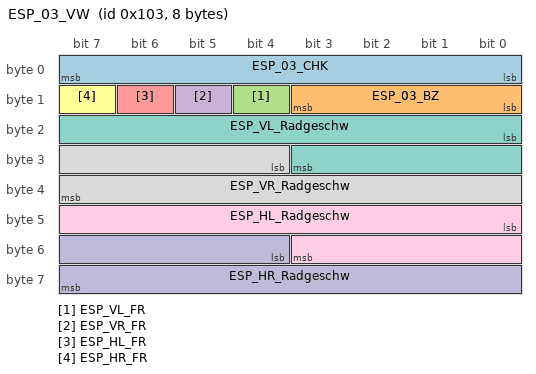
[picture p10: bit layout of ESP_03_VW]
BO_ 259 ESP_03_VW: 8 PSM_Ant_Derivate
 SG_ ESP_03_CHK : 0|8@1+ (1,0) [0|255] ""  Motor_EDC17_Pirol,GW_Routing_Derivate,Getriebe_Derivate,Motor_MED17_Hybrid
 SG_ ESP_03_BZ : 8|4@1+ (1,0) [0|15] ""  Motor_EDC17_Pirol,GW_Routing_Derivate,Getriebe_Derivate,Motor_MED17_Hybrid
 SG_ ESP_VL_FR : 12|1@1+ (1,0) [0|1] ""  Motor_EDC17_Pirol,GW_Routing_Derivate,Getriebe_Derivate,Motor_MED17_Hybrid
 SG_ ESP_VR_FR : 13|1@1+ (1,0) [0|1] ""  Motor_EDC17_Pirol,GW_Routing_Derivate,Getriebe_Derivate,Motor_MED17_Hybrid
 SG_ ESP_HL_FR : 14|1@1+ (1,0) [0|1] ""  Motor_EDC17_Pirol,GW_Routing_Derivate,Getriebe_Derivate,Motor_MED17_Hybrid
 SG_ ESP_HR_FR : 15|1@1+ (1,0) [0|1] ""  Motor_EDC17_Pirol,GW_Routing_Derivate,Getriebe_Derivate,Motor_MED17_Hybrid
 SG_ ESP_VL_Radgeschw : 16|12@1+ (0.1,0) [0|409.2] "Unit_KiloMeterPerHour"  Motor_MED17_Hybrid,GW_Routing_Derivate,Motor_EDC17_Pirol,Getriebe_Derivate
 SG_ ESP_VR_Radgeschw : 28|12@1+ (0.1,0) [0|409.2] "Unit_KiloMeterPerHour"  Motor_MED17_Hybrid,GW_Routing_Derivate,Motor_EDC17_Pirol,Getriebe_Derivate
 SG_ ESP_HL_Radgeschw : 40|12@1+ (0.1,0) [0|409.2] "Unit_KiloMeterPerHour"  Motor_MED17_Hybrid,GW_Routing_Derivate,Motor_EDC17_Pirol,Getriebe_Derivate
 SG_ ESP_HR_Radgeschw : 52|12@1+ (0.1,0) [0|409.2] "Unit_KiloMeterPerHour"  Motor_MED17_Hybrid,Motor_EDC17_Pirol,GW_Routing_Derivate,Getriebe_Derivate

BO_ 776 ESP_04_VW: 8 PSM_Ant_Derivate
 SG_ ESP_HDC_FktLampe : 3|1@1+ (1,0) [0|1] "" Vector__XXX
 SG_ ESP_ASR_Lampe : 31|1@1+ (1,0) [0|1] "" Vector__XXX
 SG_ ESP_Meldungen : 0|3@1+ (1,0) [0|7] "" Vector__XXX
 SG_ ESP_Lampe : 4|1@1+ (1,0) [0|1] "" Vector__XXX
 SG_ ABS_Lampe : 5|1@1+ (1,0) [0|1] "" Vector__XXX
 SG_ BK_Lampe : 6|1@1+ (1,0) [0|1] "" Vector__XXX
 SG_ ESP_Akustik : 7|2@1+ (1,0) [0|3] "" Vector__XXX
 SG_ ESP_Diagnose : 9|1@1+ (1,0) [0|1] ""  GW_Routing_Derivate,GW_Applikation_Derivate
 SG_ ESP_Textanzeigen_02 : 10|5@1+ (1,0) [0|31] "" Vector__XXX
 SG_ ESP_Off_Lampe : 15|1@1+ (1,0) [0|1] "" Vector__XXX
 SG_ ESP_m_Raddrehz : 16|15@1+ (0.002,0) [0|65.278] "Unit_Hertz" Vector__XXX
 SG_ ESP_Wegimp_VA : 32|11@1+ (1,0) [0|2047] ""  Getriebe_Derivate
 SG_ ESP_Fehlerstatus_Wegimp : 43|1@1+ (1,0) [0|1] "" Vector__XXX
 SG_ ESP_Wegimp_Ueberlauf : 44|1@1+ (1,0) [0|1] "" Vector__XXX
 SG_ ESP_QBit_Wegimp_VA : 45|1@1+ (1,0) [0|1] "" Vector__XXX
 SG_ ESP_Displaywarnungen : 46|2@1+ (1,0) [0|3] "" Vector__XXX
 SG_ ESP_HDC_Regelgeschw : 48|7@1+ (0.32,0) [0.32|39.68] "Unit_KiloMeterPerHour" Vector__XXX
 SG_ ESP_BKV_Warnung : 55|1@1+ (1,0) [0|1] "" Vector__XXX
 SG_ ESP_Zaehnezahl : 56|8@1+ (1,0) [0|255] ""  Getriebe_Derivate

BO_TX_BU_ 488 : Motor_EDC17_Pirol,Motor_MED17_Hybrid;
BO_TX_BU_ 2616986625 : Motor_EDC17_Pirol,Motor_MED17_Hybrid;
CM_ SG_ 1446 OBC_KomponentenFehler_01 "Übertragung OBD relevanter Fehlerpfade vom Secondary zum Primary Steuergerät. 
Zuordnung der generischen Komponentenfehler muss zwischen Sender und Empfänger abgestimmt werden.";
CM_ SG_ 1446 OBC_KomponentenFehler_02 "Übertragung OBD relevanter Fehlerpfade vom Secondary zum Primary Steuergerät. 
Zuordnung der generischen Komponentenfehler muss zwischen Sender und Empfänger abgestimmt werden.";
CM_ SG_ 1446 OBC_KomponentenFehler_03 "Übertragung OBD relevanter Fehlerpfade vom Secondary zum Primary Steuergerät. 
Zuordnung der generischen Komponentenfehler muss zwischen Sender und Empfänger abgestimmt werden.";
CM_ SG_ 1446 OBC_KomponentenFehler_04 "Übertragung OBD relevanter Fehlerpfade vom Secondary zum Primary Steuergerät. 
Zuordnung der generischen Komponentenfehler muss zwischen Sender und Empfänger abgestimmt werden.";
CM_ SG_ 1446 OBC_KomponentenFehler_05 "Übertragung OBD relevanter Fehlerpfade vom Secondary zum Primary Steuergerät. 
Zuordnung der generischen Komponentenfehler muss zwischen Sender und Empfänger abgestimmt werden.";
CM_ SG_ 1446 OBC_KomponentenFehler_06 "Übertragung OBD relevanter Fehlerpfade vom Secondary zum Primary Steuergerät. 
Zuordnung der generischen Komponentenfehler muss zwischen Sender und Empfänger abgestimmt werden.";
CM_ SG_ 1446 OBC_KomponentenFehler_07 "Übertragung OBD relevanter Fehlerpfade vom Secondary zum Primary Steuergerät. 
Zuordnung der generischen Komponentenfehler muss zwischen Sender und Empfänger abgestimmt werden.";
CM_ SG_ 1446 OBC_KomponentenFehler_08 "Übertragung OBD relevanter Fehlerpfade vom Secondary zum Primary Steuergerät. 
Zuordnung der generischen Komponentenfehler muss zwischen Sender und Empfänger abgestimmt werden.";
CM_ SG_ 1446 OBC_KomponentenFehler_09 "Übertragung OBD relevanter Fehlerpfade vom Secondary zum Primary Steuergerät. 
Zuordnung der generischen Komponentenfehler muss zwischen Sender und Empfänger abgestimmt werden.";
CM_ SG_ 1446 OBC_KomponentenFehler_10 "Übertragung OBD relevanter Fehlerpfade vom Secondary zum Primary Steuergerät. 
Zuordnung der generischen Komponentenfehler muss zwischen Sender und Empfänger abgestimmt werden.";
CM_ SG_ 1446 OBC_KomponentenFehler_11 "Übertragung OBD relevanter Fehlerpfade vom Secondary zum Primary Steuergerät. 
Zuordnung der generischen Komponentenfehler muss zwischen Sender und Empfänger abgestimmt werden.";
CM_ SG_ 1446 OBC_KomponentenFehler_12 "Übertragung OBD relevanter Fehlerpfade vom Secondary zum Primary Steuergerät. 
Zuordnung der generischen Komponentenfehler muss zwischen Sender und Empfänger abgestimmt werden.";
CM_ SG_ 1446 OBC_KomponentenFehler_13 "Übertragung OBD relevanter Fehlerpfade vom Secondary zum Primary Steuergerät. 
Zuordnung der generischen Komponentenfehler muss zwischen Sender und Empfänger abgestimmt werden.";
CM_ SG_ 1446 OBC_KomponentenFehler_14 "Übertragung OBD relevanter Fehlerpfade vom Secondary zum Primary Steuergerät. 
Zuordnung der generischen Komponentenfehler muss zwischen Sender und Empfänger abgestimmt werden.";
CM_ SG_ 1446 OBC_KomponentenFehler_15 "Übertragung OBD relevanter Fehlerpfade vom Secondary zum Primary Steuergerät. 
Zuordnung der generischen Komponentenfehler muss zwischen Sender und Empfänger abgestimmt werden.";
CM_ SG_ 1446 OBC_KomponentenFehler_16 "Übertragung OBD relevanter Fehlerpfade vom Secondary zum Primary Steuergerät. 
Zuordnung der generischen Komponentenfehler muss zwischen Sender und Empfänger abgestimmt werden.";
CM_ SG_ 1446 OBC_KomponentenFehler_17 "Übertragung OBD relevanter Fehlerpfade vom Secondary zum Primary Steuergerät. 
Zuordnung der generischen Komponentenfehler muss zwischen Sender und Empfänger abgestimmt werden.";
CM_ SG_ 1446 OBC_KomponentenFehler_18 "Übertragung OBD relevanter Fehlerpfade vom Secondary zum Primary Steuergerät. 
Zuordnung der generischen Komponentenfehler muss zwischen Sender und Empfänger abgestimmt werden.";
CM_ SG_ 1446 OBC_KomponentenFehler_19 "Übertragung OBD relevanter Fehlerpfade vom Secondary zum Primary Steuergerät. 
Zuordnung der generischen Komponentenfehler muss zwischen Sender und Empfänger abgestimmt werden.";
CM_ SG_ 1446 OBC_KomponentenFehler_20 "Übertragung OBD relevanter Fehlerpfade vom Secondary zum Primary Steuergerät. 
Zuordnung der generischen Komponentenfehler muss zwischen Sender und Empfänger abgestimmt werden.";
CM_ SG_ 1446 OBC_KomponentenFehler_21 "Übertragung OBD relevanter Fehlerpfade vom Secondary zum Primary Steuergerät. 
Zuordnung der generischen Komponentenfehler muss zwischen Sender und Empfänger abgestimmt werden.";
CM_ SG_ 1446 OBC_KomponentenFehler_22 "Übertragung OBD relevanter Fehlerpfade vom Secondary zum Primary Steuergerät. 
Zuordnung der generischen Komponentenfehler muss zwischen Sender und Empfänger abgestimmt werden.";
CM_ SG_ 1446 OBC_KomponentenFehler_23 "Übertragung OBD relevanter Fehlerpfade vom Secondary zum Primary Steuergerät. 
Zuordnung der generischen Komponentenfehler muss zwischen Sender und Empfänger abgestimmt werden.";
CM_ SG_ 1446 OBC_KomponentenFehler_24 "Übertragung OBD relevanter Fehlerpfade vom Secondary zum Primary Steuergerät. 
Zuordnung der generischen Komponentenfehler muss zwischen Sender und Empfänger abgestimmt werden.";
CM_ SG_ 1446 OBC_KomponentenFehler_25 "Übertragung OBD relevanter Fehlerpfade vom Secondary zum Primary Steuergerät. 
Zuordnung der generischen Komponentenfehler muss zwischen Sender und Empfänger abgestimmt werden.";
CM_ SG_ 1446 OBC_KomponentenFehler_26 "Übertragung OBD relevanter Fehlerpfade vom Secondary zum Primary Steuergerät. 
Zuordnung der generischen Komponentenfehler muss zwischen Sender und Empfänger abgestimmt werden.";
CM_ SG_ 1446 OBC_KomponentenFehler_27 "Übertragung OBD relevanter Fehlerpfade vom Secondary zum Primary Steuergerät. 
Zuordnung der generischen Komponentenfehler muss zwischen Sender und Empfänger abgestimmt werden.";
CM_ SG_ 1446 OBC_KomponentenFehler_28 "Übertragung OBD relevanter Fehlerpfade vom Secondary zum Primary Steuergerät. 
Zuordnung der generischen Komponentenfehler muss zwischen Sender und Empfänger abgestimmt werden.";
CM_ SG_ 1446 OBC_KomponentenFehler_29 "Übertragung OBD relevanter Fehlerpfade vom Secondary zum Primary Steuergerät. 
Zuordnung der generischen Komponentenfehler muss zwischen Sender und Empfänger abgestimmt werden.";
CM_ SG_ 1446 OBC_KomponentenFehler_30 "Übertragung OBD relevanter Fehlerpfade vom Secondary zum Primary Steuergerät. 
Zuordnung der generischen Komponentenfehler muss zwischen Sender und Empfänger abgestimmt werden.";
CM_ SG_ 1446 OBC_KomponentenFehler_31 "Übertragung OBD relevanter Fehlerpfade vom Secondary zum Primary Steuergerät. 
Zuordnung der generischen Komponentenfehler muss zwischen Sender und Empfänger abgestimmt werden.";
CM_ SG_ 1446 OBC_KomponentenFehler_32 "Übertragung OBD relevanter Fehlerpfade vom Secondary zum Primary Steuergerät. 
Zuordnung der generischen Komponentenfehler muss zwischen Sender und Empfänger abgestimmt werden.";
CM_ SG_ 1445 OBC_CVN_VLD "Valid-Bit der Calibration-Verification-Number (CVN bzw. Checksumme)";
CM_ SG_ 1445 OBC_CALID_Index_01 "Software-Calibration-Identification (CALID) im ASCII-Zeichenformat; 
für Ausgabe an das Generic Scan-Tool für OBD in NAR

0x30 entspricht ASCII '0'";
CM_ SG_ 1445 OBC_CALID_Index_05 "Software-Calibration-Identification (CALID) im ASCII-Zeichenformat; 
für Ausgabe an das Generic Scan-Tool für OBD in NAR

0x30 entspricht ASCII '0'";
CM_ SG_ 1445 OBC_CALID_Index_09 "Software-Calibration-Identification (CALID) im ASCII-Zeichenformat; 
für Ausgabe an das Generic Scan-Tool für OBD in NAR

0x30 entspricht ASCII '0'";
CM_ SG_ 1445 OBC_CALID_Index_13 "Software-Calibration-Identification (CALID) im ASCII-Zeichenformat; 
für Ausgabe an das Generic Scan-Tool für OBD in NAR

0x30 entspricht ASCII '0'";
CM_ SG_ 1445 OBC_CALID_Index_02 "Software-Calibration-Identification (CALID) im ASCII-Zeichenformat; 
für Ausgabe an das Generic Scan-Tool für OBD in NAR

0x30 entspricht ASCII '0'";
CM_ SG_ 1445 OBC_CALID_Index_06 "Software-Calibration-Identification (CALID) im ASCII-Zeichenformat; 
für Ausgabe an das Generic Scan-Tool für OBD in NAR

0x30 entspricht ASCII '0'";
CM_ SG_ 1445 OBC_CALID_Index_10 "Software-Calibration-Identification (CALID) im ASCII-Zeichenformat; 
für Ausgabe an das Generic Scan-Tool für OBD in NAR

0x30 entspricht ASCII '0'";
CM_ SG_ 1445 OBC_CALID_Index_14 "Software-Calibration-Identification (CALID) im ASCII-Zeichenformat; 
für Ausgabe an das Generic Scan-Tool für OBD in NAR

0x30 entspricht ASCII '0'";
CM_ SG_ 1445 OBC_CALID_Index_03 "Software-Calibration-Identification (CALID) im ASCII-Zeichenformat; 
für Ausgabe an das Generic Scan-Tool für OBD in NAR

0x30 entspricht ASCII '0'";
CM_ SG_ 1445 OBC_CALID_Index_07 "Software-Calibration-Identification (CALID) im ASCII-Zeichenformat; 
für Ausgabe an das Generic Scan-Tool für OBD in NAR

0x30 entspricht ASCII '0'";
CM_ SG_ 1445 OBC_CALID_Index_11 "Software-Calibration-Identification (CALID) im ASCII-Zeichenformat; 
für Ausgabe an das Generic Scan-Tool für OBD in NAR

0x30 entspricht ASCII '0'";
CM_ SG_ 1445 OBC_CALID_Index_15 "Software-Calibration-Identification (CALID) im ASCII-Zeichenformat; 
für Ausgabe an das Generic Scan-Tool für OBD in NAR

0x30 entspricht ASCII '0'";
CM_ SG_ 1445 OBC_CALID_Index_04 "Software-Calibration-Identification (CALID) im ASCII-Zeichenformat; 
für Ausgabe an das Generic Scan-Tool für OBD in NAR

0x30 entspricht ASCII '0'";
CM_ SG_ 1445 OBC_CALID_Index_08 "Software-Calibration-Identification (CALID) im ASCII-Zeichenformat; 
für Ausgabe an das Generic Scan-Tool für OBD in NAR

0x30 entspricht ASCII '0'";
CM_ SG_ 1445 OBC_CALID_Index_12 "Software-Calibration-Identification (CALID) im ASCII-Zeichenformat; 
für Ausgabe an das Generic Scan-Tool für OBD in NAR

0x30 entspricht ASCII '0'";
CM_ SG_ 1445 OBC_CALID_Index_16 "Software-Calibration-Identification (CALID) im ASCII-Zeichenformat; 
für Ausgabe an das Generic Scan-Tool für OBD in NAR

0x30 entspricht ASCII '0'";
CM_ SG_ 1445 OBC_CVN_Byte_1 "Calibration Verification Number (CVN bzw. Checksumme) des SW- und Datenstandes; 
für Ausgabe an das Generic Scan-Tool für OBD in NAR";
CM_ SG_ 1445 OBC_CVN_Byte_2 "Calibration Verification Number (CVN bzw. Checksumme) des SW- und Datenstandes; 
für Ausgabe an das Generic Scan-Tool für OBD in NAR";
CM_ SG_ 1445 OBC_CVN_Byte_3 "Calibration Verification Number (CVN bzw. Checksumme) des SW- und Datenstandes; 
für Ausgabe an das Generic Scan-Tool für OBD in NAR";
CM_ SG_ 1445 OBC_CALID_CVN_MUX "Node1_CAL_ID_CVN_MUX
Alle CALID-Indizes bilden zusammen die CALID";
CM_ SG_ 1445 OBC_CVN_Byte_4 "Calibration Verification Number (CVN bzw. Checksumme) des SW- und Datenstandes; 
für Ausgabe an das Generic Scan-Tool für OBD in NAR";
CM_ BO_ 1666 "CCP in Serie mit 11Bit - Empfangskanal";
CM_ SG_ 1527 RW_Sekundaer_Reichweite "Reichweite der sekundaeren Antriebsart";
CM_ SG_ 1527 RW_Sek_Reichweitenv_Einheit "Für sekundäre Reichweitenberechnung (KBI_Sek_Reichweitenverbrauch) zugrunde gelegte Einheit";
CM_ SG_ 1527 RW_Sek_Reichweitenverbrauch "Für sekundäre Reichweitenberechnung zugrunde gelegter Verbrauch";
CM_ SG_ 1525 RW_RWDS_Lastprofil "Lastprofil zur Bestimmung der notwendigen Nachladeenergie (Reichweitendurchschnittstrom)";
CM_ SG_ 1525 RW_Gesamt_Reichweite "Reichweite für primär und sekundär Reichweite (eventuell Gewichtet)";
CM_ SG_ 1525 RW_Prim_Reichweitenverbrauch "Für primäre Reichweitenberechnung zugrunde gelegter Verbrauch";
CM_ SG_ 1525 RW_Prim_Reichweitenv_Einheit "Für primäre  Reichweitenberechnung (KBI_Prim_Reichweitenverbrauch) zugrunde gelegte Einheit";
CM_ SG_ 1525 RW_Primaer_Reichweite "Reichweite der primären Antriebsart";
CM_ SG_ 687 BMS_Rekuperation "Zähler: Anzeigesignal: Energiezufuhr in die HV-Batterie (Reku). Darf nicht durch Laden der Batterie bedatet werden";
CM_ SG_ 687 BMS_Rekuperation_Ueberlauf "Rekuperationleistungssignal BMS_Rekuperation mindest 1x übergelaufen";
CM_ SG_ 687 BMS_Verbrauch "Zähler: Energieentnahme aus der HV-Batterie";
CM_ SG_ 687 BMS_Verbrauch_Ueberlauf "Verbrauchssignal mindest 1x übergelaufen";
CM_ SG_ 1532 KL_Autobetrieb_HL "Status, ob Klimatisierung in Autobetrieb in Klimazone hinten links";
CM_ SG_ 1532 KL_Autobetrieb_HR "Status, ob Klimatisierung in Autobetrieb in Klimazone hinten rechts";
CM_ SG_ 1532 KL_Autobetrieb_VL "Status, ob Klimatisierung in Autobetrieb in Klimazone vorne links";
CM_ SG_ 1532 KL_Autobetrieb_VR "Status, ob Klimatisierung in Autobetrieb in Klimazone vorne rechts";
CM_ SG_ 1532 KL_Zieltemperatur_HL "einzuregelnde (d.h. die interne berechnete, nicht die an der BKE eingestellte) Zieltemperatur für die Klimazone hinten links";
CM_ SG_ 1532 KL_Zieltemperatur_HR "einzuregelnde (d.h. die interne berechnete, nicht die an der BKE eingestellte) Zieltemperatur für die Klimazone hinten rechts";
CM_ SG_ 1532 KL_Zieltemperatur_VL "einzuregelnde (d.h. die interne berechnete, nicht die an der BKE eingestellte) Zieltemperatur für die Klimazone vorne links";
CM_ SG_ 1532 KL_Zieltemperatur_VR "einzuregelnde (d.h. die interne berechnete, nicht die an der BKE eingestellte) Zieltemperatur für die Klimazone vorne rechts";
CM_ BO_ 1788 "200ms";
CM_ SG_ 1788 NMH_Ladegeraet_Start_1 "Zustand Start (<--Sleep)";
CM_ SG_ 1788 NMH_Ladegeraet_Start_2 "Zustand Start (<--Prepare to Sleep)";
CM_ SG_ 1788 NMH_Ladegeraet_Normal_Mode_1 "Zustand Normal Mode (<-- Start)";
CM_ SG_ 1788 NMH_Ladegeraet_Normal_Mode_2 "Zustand Normal Mode (<-- Ready to Sleep)";
CM_ SG_ 1788 NMH_Ladegeraet_Car_WakeUp "Car WakeUp optional, wird vom AAG nicht bedient
";
CM_ SG_ 1788 NMH_Ladegeraet_Per_WakeUp "Weckursache Peripherie
";
CM_ SG_ 1788 NMH_Ladegeraet_Fkt_WakeUp "Weckursache Funktion
";
CM_ SG_ 1788 NMH_Ladegeraet_Klemme_15 "Kl.15 EIN (Nachlaufursache, SG nicht im NM-Zustand 'Ready to Sleep')
";
CM_ SG_ 1788 NMH_Ladegeraet_Diagnose "Diagnose bei Kl 15 aus (Nachlaufursache, SG nicht im NM-Zustand 'Ready to Sleep')
";
CM_ SG_ 1788 NMH_Ladegeraet_MindestAktivZeit "Mindestaktivzeit Taktiv_min (Nachlaufursache, SG nicht im NM-Zustand 'Ready to Sleep') / nSTART
";
CM_ SG_ 1788 NMH_Ladegeraet_Signalfehler "Bei der Speicherung eines CAN-Signalfehlers muss dieser mindestens einmal in der NM-Botschaft angezeigt werden.";
CM_ SG_ 1788 NMH_Ladegeraet_TimeOut_Fehler "Aktiver Timeout Fehlerspeichereintrag";
CM_ SG_ 1788 NMH_Ladegeraet_CAN_Diag_deaktiv "CAN-Diagnose deaktiv (Überspannung, Unterspannung, Hochlaufphase, ...) ";
CM_ SG_ 1788 NMH_Ladegeraet_KompSchutz "Funktionseinschränung aufgrund Komponentenschutz aktiv";
CM_ SG_ 1788 NMH_Ladegeraet_Mute_Mode "Funktionseinschränung aufgrund Mute Mode aktiv, nur VW";
CM_ SG_ 1788 NMH_Ladegeraet_Transport_Mode "Funktionseinschränung aufgrund Transport Mode aktiv";
CM_ SG_ 1788 NMH_Ladegeraet_Abschaltstufe_000 "Funktionsabschaltung wegen Abschaltschaltstufe";
CM_ SG_ 1788 NMH_Ladegeraet_Eindraht_Fehler "Erkennung Eindrahtfehler";
CM_ SG_ 1788 NMH_Ladegeraet_Lokalaktiv "Zeigt an ob Steuergerät lokal aktiv war";
CM_ SG_ 1788 NMH_Ladegeraet_Subsystemaktiv "Zeigt an ob ein Subsystem des SGs nach Klemme15 AUS und nach entsprechender MAX Aktivzeit noch aktiv war";
CM_ SG_ 1483 PTC_Wassereinlasstemp "Gemessene Wassereinlasstemperatur";
CM_ SG_ 1483 PTC_Wasserauslasstemp "Gemessene Wasserauslasstemperatur";
CM_ SG_ 1483 PTC_HV_I_ist "PTC Stromverbrauch (max. 120A)";
CM_ SG_ 1483 KL_T_Charge "Signal für Tastenbetätigung Charge-Taste (SOC Increasing)";
CM_ SG_ 1483 KBT_Defrost_aktiv "Defrostmodus im KBT aktiv";
CM_ SG_ 1483 KL_WunschStrom_HV "Von Klima gewünschter HV-Strom, der dann nach Freigabe des HV-eEM auf HV-EKK und HV-PTC aufgeteilt wird";
CM_ SG_ 1483 KL_BattKond_WaPu_DZMax "Maximal-Drehzahl der Wasserpumpe im Batteriekühlkreislauf als Vorgabe für BMS";
CM_ SG_ 1483 KL_Standklima_Status "Info, dass Standklimatisierung nicht gestartet werden konnte oder abgebrochen wurde.";
CM_ SG_ 899 CHA_Ziel_FahrPr_BMS "Anforderung Ziel-Fahrprogramm BMS (nähere Spezifikation siehe Charisma-LH PAG)";
CM_ SG_ 1518 KL_T_STH "Taster Standheizung (Wasserzusatzheizung)";
CM_ SG_ 1518 Klima_08_PAG_alt "Veraltet Bit für die Signale:
KL_Segel_Anf_deaktivieren";
CM_ SG_ 391 MO_Tankbereitschaft_Status "Meldung der Tankbereitschaft";
CM_ SG_ 391 MO_Tankklappensteuerung "Ansteuerungsanforderung der Tankklappe";
CM_ SG_ 391 MO_HVEM_MaxLeistung "Maximal zulässige Leistung, die das HVEM einzustellen hat. 
Ohne Eskalationsbit ist diese Anforderung >= der Minimal benötigten Leistung des HVEM";
CM_ SG_ 391 EV_Rekuperationsstufe "Im Kombi anzuzeigende Rekuperationsstufe";
CM_ SG_ 391 MO_Waehlpos "Wählhebelposition (im VW120/7 und MQB Omega ist der Wählhebel am HCAN mit Master Motor-SG angeschlossen)

(wenn Signal in MSG_HYB_03: Signal nur in der CAN-Welt PQ35/25 zu verwenden, da dort am ACAN die Wählhebelposition nicht abgesichert übertragen wir";
CM_ SG_ 391 HV_Bordnetz_aktiv "Signalisiert ein aktives Hochvoltbordnetz. HV-Schütze geschlossen. Im Fehlerfall wird das Bit nicht gesetzt.(Klemmende Schütze)";
CM_ SG_ 391 MO_HVEM_Eskalation "Eskalationsbit, mit diesem zusammen darf MO_HVEM_MaxLeistung < der minimal angeforderten Leistung sein und ist durch das HVEM durch Ergreifung aller Eskalationsmaßnahmen umzusetzen (Bei neg. Ladebilanz z.B. im Leerlauf nötig, um die HVBatt vor Entladung e";
CM_ SG_ 1662 LAD_02_CHK "Berechnung siehe Konzern-Lastenheft A-CAN V4.2a
Checksummenendwert = 0x00";
CM_ SG_ 1662 LAD_02_BZ "freilaufender Botschaftszähler";
CM_ SG_ 1662 LAD_Abregelung_Temperatur "Abregelung aufgrund interner Übertemperatur im Ladegerät";
CM_ SG_ 1662 LAD_Abregelung_IU_Ein_Aus "Abregelung aufgrund Strom oder Spannung am Eingang oder Ausgang";
CM_ SG_ 1662 LAD_Abregelung_BuchseTemp "Reduzierung aufgrund zu hoher Temperatur der Ladebuchse";
CM_ SG_ 1662 LAD_MaxLadLeistung_HV "Maximale Leistung Ladegerät bezogen auf die maximale Leistung Infrastruktur (Kabel, Ladestation) und Berücksichtigung des Ladegerät-Wirkungsgrades";
CM_ SG_ 1662 LAD_CP_Stromlimit "AC-Stromlimit aufgrund des CP Duty Cycles";
CM_ SG_ 1662 LAD_PRX_Stromlimit "AC-Stromlimit aufgrund der PRX Kabelkodierung";
CM_ SG_ 1662 LAD_CP_Erkennung "Status Control Pilot Überwachung (Erkennung des Control Pilot Duty-Cycles)";
CM_ SG_ 1662 LAD_Stecker_Verriegelt "Status Steckerverriegelung (Rücklesekontakt des Verrieglungsaktors)";
CM_ SG_ 1662 LAD_Stecker_Gesteckt "Status Steckererkennung";
CM_ SG_ 1662 LAD_Kuehlbedarf "Kühlbedarf des Ladegerätes";
CM_ SG_ 1662 LAD_Warnzustand "Sammelwarnung Ladegerät
0 keine Warnbedingung aktiv
1 Warnbedingung aktiv, evtl. eingeschränkte Leistungsfähigkeit";
CM_ SG_ 1662 LAD_Fehlerzustand "Sammelfehler Ladegerät - kein Laden möglich";
CM_ SG_ 1662 LAD_Fehlerstatus "aktueller Fehlerstatus des Ladegerätes
0: Komponente IO (keine HVK relevanter Fehler)
1: Eingeschränkte_Komponentenfunktion AC Laden nicht möglich
2: Eingeschränkte_Komponentenfunktion DC Laden nicht möglich
3: Eingeschr_Komponentenfunktion aufgrund H";
CM_ SG_ 1662 LAD_Warnlampe_Anf "Anforderung der gelben Hybrid-Warnlampe im Kombi (Motorsteuergerät reicht diese Info an Kombi weiter).";
CM_ SG_ 1380 LAD_01_CHK "Berechnung siehe Konzern-Lastenheft A-CAN V4.2a
Checksummenendwert = 0x00";
CM_ SG_ 1380 LAD_01_BZ "freilaufender Botschaftszähler";
CM_ SG_ 1380 LAD_IstModus "Betriebsmodus:
0: Standby: Kommunikaton aktiv
1: NetzLade-Modus (gesteuert durch EV-Lademanagement)
2: externe Steuerung (gesteuert durch Netzbetreiber)
3: vorgehalten
4: vorgehalten
5: interner Fehler Lader, angeforderter Sollmodus kann nicht einge";
CM_ SG_ 1380 LAD_AC_Istspannung "Istwert AC-Netzspannung (RMS) ";
CM_ SG_ 1380 LAD_IstSpannung_HV "Ausgangsspannung Lader";
CM_ SG_ 1380 LAD_IstStrom_HV "Ausgangsstrom Lader";
CM_ SG_ 1380 LAD_Status_Spgfreiheit "0 = Init (ohne Funktion)
1 = Ladegerät HV-Komponenten spannungsfrei (U_Zwkr < 20V)
2 = Ladegerät HV_Komponenten nicht spannungsfrei (U_Zwkr >= 20V)
3 = Fehler (z. B. Fehler in der Sensorik)";
CM_ SG_ 1380 LAD_Temperatur "Momentanwert: Temperatur Ladegerät";
CM_ SG_ 1380 LAD_Verlustleistung "Momentanwert: Verlustleistung Ladegerät";
CM_ SG_ 1385 HVEM_Abschaltstatus "Status der Reduzierungsstufen der Klimakomponenten beim Laden

0 = 100% (keine Reduzierung)
1 = 75%
2 = 50%
3 = 25%
7 = Init";
CM_ SG_ 1385 HVEM_NVLeistungEmpf "Maximaler Sollwert der aktuellen Leistung der NV-Seite des DCDC-Wandlers.";
CM_ SG_ 1385 HVEM_KlimaMaxHVStrom "Kommuniziert dem Klimasteuergerät den max. Aufnahmestrom";
CM_ SG_ 1385 HVEM_LeistunsAnf "Anforderung an NV-EM zur Erhöhung der Performance den Energieverbrauch auf der NV-Seite zu reduzieren.";
CM_ SG_ 1385 HVEM_Nachlad_Status "Status der Umsetzung der Nachladeanforderung der NV-Seite.";
CM_ SG_ 1385 HVEM_Anf_ReichweiteNV "Anforderung an NV-EM zur Erhöhung der Reichweite den Energieverbrauch auf der NV-Seite zu reduzieren.";
CM_ SG_ 1385 HVEM_HV_Anf "HV Anforderung des HV Energiemanagements an das MSG";
CM_ SG_ 1385 HVEM_Text_1 "Meldung bei einem Anzeige SOC<10% ('Achtung Batterie laden. Funktionen eingeschränkt')";
CM_ SG_ 1385 HVEM_Nachladen_Anf "Anforderung für HV Laden bei gestecktem Stecker und deaktivierter Ladeanforderung";
CM_ SG_ 1385 HVEM_FreigabeKlimatisierung "Klimatisierung freigeben";
CM_ SG_ 1482 BMS_07_CRC "Für MLB:
'Berechnung siehe Lastenheft 'Kommunikationsabsicherung für FlexRay und CAN''

Ab MQB und MLBevo:
'Berechnung siehe Lastenheft 'End-to-End Kommunikationsabsicherung''

Endwerte siehe Begleitdokument 'S-PDU Kennungsfolgen'";
CM_ SG_ 1482 BMS_Energieinhalt "aktuell nutzbarer Energieinhalt der HV-Batterie
(bezogen auf ein definiertes mittleres Belastungsprofil)";
CM_ SG_ 1482 BMS_Ladevorgang_aktiv "Signalisiert aktiven Ladevorgang, Ladegerät und DC/DC aktiv.
Signal bleibt nach Kl.15 ein aktiv, bis ESP_Stillstandsflag gelöscht.

Abhängigkeit zu BMS_Energieinhalt";
CM_ SG_ 1482 BMS_MaxEnergieinhalt "maximaler nutzbarer Energieinhalt der HV-Batterie (bezogen auf Last KBI_RWDS_Lastprofil bei SOC=100%)
Abhängig von KBI_RWDS_Lastprofil";
CM_ SG_ 1482 BMS_Ausgleichsladung_Anf "BMS wünscht eine Ausgleichsladung
Flag derzeit ungenutzt, da BalancingModus im Detail noch nicht geklärt.";
CM_ SG_ 1482 BMS_Gesamtst_Spgfreiheit "0 = Funktion nicht aktiviert
1 = HV-System spannungsfrei (U_Zwkr von BMS, LE und Ladegerät < 20V, DCLadestecker nicht gesteckt und Service Disconnect entriegelt)
2 = HV-System nicht spannungsfrei (U_Zwkr von BMS, LE und Ladegerät >= 20V, Ladestecker ges";
CM_ SG_ 1519 BMS_IstStrom "actual current of the battery / Momentanwert: Batteriestrom
Stromrichtung: ein Ladestrom wird mit positiven, ein Entladestrom mit negativen Werten angegeben";
CM_ SG_ 1519 BMS_PTC_Stufe "aktulle Stufe des PTC Zuheizers für den Batteriekühlkreislauf";
CM_ SG_ 1519 BMS_PTC_IstStrom "Ist Strom des PTC Zuheizers für den Batteriekühlkreislauf";
CM_ SG_ 1519 BMS_Status_Kuehlung "Rueckmeldung BMS Kuehlstufe";
CM_ SG_ 1519 BMS_Temp_Zelle_Min "Minimale Temperatur einer Zelle in der HVB";
CM_ SG_ 1519 BMS_Temp_Zelle_Max "Maximale Temperatur einer Zelle in der HVB";
CM_ SG_ 1519 BMS_Pumpendrehzahl "Rueckmeldung der CWA50 ueber aktuelle Pumpendrehzahl in % im Kuehlkreislauf HV-Batterie";
CM_ SG_ 1519 BMS_Status_3_2_Ventil1 "Status 3/2 Wegeventil Kuehlkreislauf HV-Batterie";
CM_ SG_ 1519 BMS_Status_3_2_Ventil2 "Status 3/2 Wegeventil Kuehlkreislauf HV-Batterie";
CM_ SG_ 1438 BMS_Temperierung_Anf "Temperierungsbedarf der HV-Batterie";
CM_ SG_ 1438 BMS_Temperatur "battery temperature / Momentanwert: Temperatur der Traktionsbatterie";
CM_ SG_ 1438 BMS_IstVorlaufTemperatur "Aktuelle Vorlauftemperatur der Batterie";
CM_ SG_ 1438 BMS_SollVolumenstrom "Soll Volumenstrom für Kühlkreislauf Batterie";
CM_ SG_ 1438 BMS_SollVorlauftemperatur "Soll_Vorlauftemperatur_Kühlmedium in °C";
CM_ SG_ 1438 BMS_IstRuecklaufTemperatur_02 "Aktuelle Ruecklauftemperatur der Batterie";
CM_ SG_ 1438 BMS_SollVorlaufTemp_Epsilon "¿Dieses Signal beschreibt die zulässige Abweichung oberhalb und unterhalb von der Sollvorlauftemperatur in Kelvin, die von der HV-Batterie akzeptiert wird. Bei einer SollVorlaufTemperatur von 30°C und einem Wert von SollVorlaufTemperaturEpsilon von 5K wer";
CM_ SG_ 1428 HVLM_HV_Anf "HV-Aktivierung Anforderung und Grund der Anforderung";
CM_ SG_ 1428 HVLM_Stecker_Status "Status der Steckererkennung unabhängig vom Lademodus (AC oder DC)";
CM_ SG_ 1428 HVLM_Restladezeit_HV_Bat_02 "Zeit, bis HV-Batterie vollständig geladen ist. Angabe in 5 Minuten Schritten. Maximum 42h 25Min";
CM_ SG_ 1428 HVLM_Lademodus_HV_Bat "Gibt den aktuell eingestellten Lademodus an.";
CM_ SG_ 1428 HVLM_Ladeart "Anzeige des ausgewählten Lademodus";
CM_ SG_ 1428 HVLM_VK_Anf "Anforderung des Konditionierungsmanagers (im Lademanager) zur Aktivierung der Vorkonditionierung Innenraum";
CM_ SG_ 1428 HVLM_Ladesystemhinweise "Anzeigen von Hinweisen zum Ladesystem.
Anzeigen, dass das Ladesystem defekt ist.";
CM_ SG_ 1428 HVLM_Langzeit_Laden "Anforderung den Ladezustand der HV-Batterie bis langen Standzeiten zu reduzieren";
CM_ SG_ 1428 HVLM_Klima_Temp "MLBevo: Gewünschte Innenraumtemperatur, auf die bei der Standklimatisierung geregelt werden soll.
MQB: Temperatur die vom Nutzer vorgewählt wurde (VW: low=15,5 °C/ high=30,0°C)";
CM_ SG_ 1428 HVLM_VK_Modus "Übermittlung des aktuellen Konditionierungs-Status für HMI, Mobile Online Dienste";
CM_ SG_ 1428 HVLM_HSH_Anf "Heckscheibenheizung anfordern";
CM_ SG_ 305 MO_ePowermeter "Anzeige ePowermeter (Fahrreserve elektrisch bis Start Verbrennungsmotor (Verbrenner startet bei 100%))";
CM_ SG_ 305 MO_W_Reku_normiert_ueberlauf "Motorsteuergeräteinterner Rekuperationszähler, der vom Kombi ausgewertet wird, um die Rekuperierte Arbeit/Leistung zu erfassen.";
CM_ SG_ 305 Ladezustand "Ladezustand der Batterie
";
CM_ SG_ 305 Enrgfluss_State "Energiefluss zwischen den Achsen, Batterie, Elektromotor und Verbrennungsmotor";
CM_ SG_ 305 MO_W_Reku_normiert "Motorsteuergeräteinterner Rekuperationszähler, der vom Kombi ausgewertet wird, um die Rekuperierte Arbeit/Leistung zu erfassen.";
CM_ SG_ 305 MO_Powermeter "Anzeigewerte im Kombi
0       = Unteres Ende Bremsen/grau;
340   = Unteres Ende CHARGE;
1020 = READY;
1870 = Oberes Ende EFFICIENCY;
3400 = 100%;
4080 = MAX;";
CM_ SG_ 914 ESP_07_CHK "Berechnung siehe Lastenheft 'Kommunikationsabsicherung für FlexRay und CAN'
Endwerte siehe 'Kommunikationsabsicherung für FlexRay und CAN / Anhang C: Tabelle S-PDU Kennungen'";
CM_ SG_ 914 ESP_OBD_Status "Dieses Bit steuert die MIL-Lampe an (Motorsteuergerät reicht diese Info an Kombi weiter).";
CM_ SG_ 914 OBD_Fehler_Radsensor_VR "Für Motor-SG (gesetzliche Vorgabe)";
CM_ SG_ 914 OBD_Fehler_Radsensor_VL "Für Motor-SG (gesetzliche Vorgabe)";
CM_ SG_ 914 OBD_Fehler_Radsensor_HR "Für Motor-SG (gesetzliche Vorgabe)";
CM_ SG_ 914 OBD_Fehler_Radsensor_HL "Für Motor-SG (gesetzliche Vorgabe)";
CM_ SG_ 906 KL_Sportmodus "Sportmodus";
CM_ SG_ 906 KL_T_PSM_off "PSM-Off Taster (Anforderung ESP passiv schalten)";
CM_ SG_ 906 F_Klima_08_PAG_Fwk "Ungueltige Signale: KL_Sportmodus,KL_T_Lift,KL_T_PASM_1,KL_T_PASM_2, KL_T_PASM_3, KL_St_FSM, KL_Niv_up, KL_Niv_down, KL_T_Sport, KL_T_PSM_Off, KL_T_Range, KL_T_Sperre, KL_Atemp_ungef, KL_T_HDC,KL_T_Abgasklappe




";
CM_ SG_ 906 F_Klima_03_Ant "Ungueltige Signale: KL_Magnetventil,KL_STH_aktiv,KL_STH_Ansteuerung";
CM_ SG_ 906 ESP_Rollenmodus "Rollenmodus aktiv, Fzg auf Rollenpruefstand
";
CM_ SG_ 906 KL_T_Abgasklappe "Taster Sportabgasklappenanlage";
CM_ SG_ 906 KL_Magnetventil "Wasserventil zum Waermetauscher geoeffnet/geschlossen";
CM_ SG_ 906 F_ESP_11_Ant "Ungueltige Signale: ESP_Rollenmodus";
CM_ BO_ 1731 "200ms";
CM_ SG_ 1731 NMH_ESP_Start_1 "Zustand Start (<--Sleep)";
CM_ SG_ 1731 NMH_ESP_Start_2 "Zustand Start (<--Prepare to Sleep)";
CM_ SG_ 1731 NMH_ESP_Normal_Mode_1 "Zustand Normal Mode (<-- Start)";
CM_ SG_ 1731 NMH_ESP_Normal_Mode_2 "Zustand Normal Mode (<-- Ready to Sleep)";
CM_ SG_ 1731 NMH_ESP_Car_WakeUp "Car WakeUp (optional), wird vom ESP nicht gesendet";
CM_ SG_ 1731 NMH_ESP_Per_WakeUp "Weckurasche Peripherie
";
CM_ SG_ 1731 NMH_ESP_Fkt_WakeUp "Weckursache Funktion
";
CM_ SG_ 1731 NMH_ESP_NM_aktiv_Klemme_15 "Kl.15 EIN (Nachlaufursache, nicht 'Ready To Sleep')";
CM_ SG_ 1731 NMH_ESP_NM_aktiv_Diagnose "Diagnose bei Kl 15 aus (Nachlaufursache, nicht 'Ready To Sleep')";
CM_ SG_ 1731 NMH_ESP_NM_aktiv_Start "Mindestaktivzeit Zustand 'Start' (Nachlaufursache, nicht 'Ready To Sleep')";
CM_ SG_ 1731 NMH_ESP_NM_aktiv_v_groesser_Null "v>0 (wird im Initfall mit 1 gesendet, da die Drehzahlfuehler erst nach ca. 1,1s diagnostizierbar ist --> aus Sicherheitsgruenden wird von v>0 in diesem Fall ausgegangen)
(Nachlaufursache, nicht 'Ready To Sleep')";
CM_ SG_ 1731 NMH_ESP_Mindestaktivzeit "Mindestaktivzeit ESP (ca. 1,1s --> Diagnose Drehzahlfuehler)
(Nachlaufursache, nicht 'Ready To Sleep')";
CM_ SG_ 1731 NMH_ESP_kein_NL "kein lokaler / SG interner Nachlauf vor Wakeup";
CM_ SG_ 1731 NMH_ESP_NL_Daten_EEPROM "EEPROM Datenspeicherung (kein lokaler / SG interner Nachlauf vor Wakeup)";
CM_ SG_ 1731 NMH_ESP_TimeOut_Fehler "Aktiver Timeout Fehlerspeichereintrag";
CM_ SG_ 1731 NMH_ESP_CAN_Diag_deaktiv "CAN Bus bezogene Eigendiagnose deaktiviert (Überspannung, Unterspannung, Hochlaufphase, ...) ";
CM_ SG_ 1731 NMH_ESP_KompSchutz "Funktionseinschränung aufgrund Komponentenschutz aktiv";
CM_ SG_ 1731 NMH_ESP_Mute_Mode "Funktionseinschränung aufgrund Mute Mode aktiv, nur VW";
CM_ SG_ 1731 NMH_ESP_Transport_Mode "Funktionseinschränung aufgrund Transport Mode aktiv";
CM_ SG_ 1731 NMH_ESP_Abschaltstufe_aktiv "Funktionsabschaltung wegen Abschaltschaltstufe";
CM_ SG_ 1731 NMH_ESP_Eindraht_Fehler "Erkennung Eindrahtfehler";
CM_ SG_ 1731 NMH_ESP_interne_Zust "interne ESP-Systemzustände";
CM_ SG_ 1731 NMH_ESP_Lokalaktiv "Zeigt an ob das SG nach Klemme15 AUS und nach entsprechender MAX Aktivzeit noch aktiv war";
CM_ SG_ 1731 NMH_ESP_Subsystemaktiv "Zeigt an ob ein Subsystem des SGs nach Klemme15 AUS und nach entsprechender MAX Aktivzeit noch aktiv war";
CM_ SG_ 946 BEM_NV_NachladAnf "Bei Energiedefizit auf der Niedervoltseite wird der Lademanager aufgefordert, die Niedervoltseite nachzuladen.";
CM_ SG_ 946 BEM_Freigabe_HV_Ladung "Signalisierung, dass ein Aufladen der HV-Batterie aus der 12V-Seite heraus möglich ist.
Prämissen: 
Ladegerät an 12V-Seite oder
guter Ladezustand der 12V-Batterie";
CM_ SG_ 946 BEM_HYB_DC_uMinLV "Abregelgrenze: minimal erlaubte Bordnetzspannung im Hochsetzbetrieb";
CM_ SG_ 946 BEM_HYB_DC_uSollLV "Sollwert für die Bordnetzspannung im Tiefsetzbetrieb vom Traktionsnetz ins Bordnetz";
CM_ SG_ 1628 BMS_IstSpannung_HV "HV Spannungswert";
CM_ SG_ 1628 BMS_Temperatur_Ansaugluft "Temperature of inlet air / Momentanwert: Ansauglufttemperatur der Batteriekühlung";
CM_ SG_ 1628 BMS_Temperatur "battery temperature / Momentanwert: Temperatur der Traktionsbatterie";
CM_ SG_ 1628 BMS_HYB_Spuelbetrieb_Status "Status Betriebsart der Batterielüftung (Umluft-/Spülbetrieb)";
CM_ SG_ 1628 BMS_HYB_Temp_vor_Verd "Lufttemperatur im Klimagerät BMS vor Verdampfer";
CM_ SG_ 1628 BMS_HYB_Temp_nach_Verd "Lufttemperatur im Klimagerät BMS nach Verdampfer";
CM_ SG_ 1628 BMS_HYB_Kuehlung_Anf "Anforderung für aktive Batteriekühlung in vier Stufen:
Stufe 0: keine Kühlanforderung
Stufe 1: 10 °C Verdampfertemperatur Klima
Stufe 2: 3 °C Verdampfertemperatur Klima
Stufe 3: maximale Kühlleistung Klima";
CM_ SG_ 1628 BMS_HYB_ASV_vorne_Status "Status Absperrventil des Kältemittelkreislaufs zur Innenraumklimatisierung";
CM_ SG_ 1628 BMS_HYB_ASV_hinten_Status "Status Absperrventil des Kältemittelkreislaufs zur Batteriekühlung";
CM_ SG_ 1628 BMS_HYB_KD_Fehler "Bei gesetztem Bit ist mindestens ein Kundendienstfehler eingetragen";
CM_ SG_ 1628 BMS_HYB_BattFanSpd "Relativwert der Batterielüfter-Ansteuerung bezogen auf Maximalwert";
CM_ SG_ 1628 BMS_HYB_VentilationReq "BMS fordert bei Climatronic die Öffnung der Umluftklappe an";
CM_ BO_ 490 "CCP in Serie mit 11Bit - Sendekanal";
CM_ BO_ 488 "CCP in Serie mit 11Bit - Sendekanal";
CM_ SG_ 945 DC_TiefsetzBereit "Kennzeichnung, dass der DC/DC-Wandler im Sollmodus Tiefsetzbetrieb ist und auf Spannungsvorgabe wartet. Fehler werden über das Signal DC_HYB_Fehler_intern signalisiert.";
CM_ SG_ 945 DC_HYB_iAktLV "Momentanwert: Strom vom DC/DC-Wandler in das Bordnetz";
CM_ SG_ 945 DC_HYB_iAktReserveLV "Momentanwert: Stromreserve vom DC/DC-Wandler in Richtung 12V-Bordnetz";
CM_ SG_ 945 DC_HYB_uAktLV "Momentanwert: NV-Bordnetzspannung am DC/DC-Wandler";
CM_ SG_ 945 DC_HYB_LangsRegelung "aktueller Regelmode des DC/DC-Wandlers.
1: langsame Regelung
0: normale Regelung";
CM_ SG_ 945 DC_HYB_Abregelung_Temperatur "Abregelung aufgrund Übertemperatur im Leistungsteil (Hochtemperatur-Abregelung)";
CM_ SG_ 945 DC_HYB_Fehler_RedLeistung "Fehler: eingeschränkte Leistungsfähigkeit des DC/DC-Wandlers aufgrund eines internen Fehlers";
CM_ SG_ 945 DC_HYB_Fehler_intern "Fehler: DC/DC-Wandler ist aufgrund eines internen Hardware-Fehlers abgeschaltet";
CM_ SG_ 945 DC_HYB_Fehler_Spannung "Abschaltung aufgrund Unter-/Überspannung auf der Ein-/Ausgangsseite";
CM_ SG_ 945 DC_Verbrauch_Ueberlauf "Überlauf-Bit für das Signal DC_Verbrauch";
CM_ SG_ 945 DC_Verbrauch "Energieverbrauch vom DCDC für Versorgung 12V-Bordnetz inkl. seines eigenen Wirkungsgrads (bspw.: HV_Strom*HV_Spannung*t)";
CM_ SG_ 945 DC_HYB_Auslastungsgrad "Momentanwert: Auslastung DC/DC (DFM Signal), entspricht I_akt / I_max
(Vorhalt für MQB)";
CM_ SG_ 1627 EM_HYB_KD_Fehler "Bei gesetztem Bit ist mindestens ein Kundendienstfehler eingetragen";
CM_ SG_ 256 ESP_v_Signal "Geschwindigkeitssignal vom PSM. Mittelwert der angetriebenen Räder.
";
CM_ SG_ 256 ESP_01_CHK "Berechnung siehe Lastenheft 'Kommunikationsabsicherung für FlexRay und CAN'
Endwerte siehe 'Kommunikationsabsicherung für FlexRay und CAN / Anhang C: Tabelle S-PDU Kennungen'";
CM_ SG_ 256 ASR_Moment_langsam "Achtung:
Einheitenloser CAN-Wert.
Faktor in MO_Faktor_Momente in Motor_Code_01 beachten!

Langsame reduzierende (ASR) Momentenanforderung an der Motor";
CM_ SG_ 256 ASR_MSR_Moment_schnell "Achtung:
Einheitenloser CAN-Wert.
Faktor in MO_Faktor_Momente in Motor_Code_01 beachten!

Schnelle reduzierende (ASR) oder erhöhende (MSR) Momentanforderung an den Motor, Eingriffsart wird über das Signal 'ASR_MSR_Eingriffsart' qualifiziert";
CM_ SG_ 256 ASR_Tastung_passiv "ASR passiv getastet.
AUDI B8 front: Ab 70km/h wird das Bit automatisiert zurückgesetzt.
AUDI B8 quattro: Ab 70km/h wird das Bit automatisiert zurückgesetzt, ab 50km/h wieder zugeschalten.

Im B8 gilt die Funktionsspezifikation: LAH 8K0614D_V1.0.pdf - ";
CM_ SG_ 256 ESP_Tastung_passiv "ESP passiv getastet

Im B8 gilt die Funktionsspezifikation: LAH 8K0614D_V1.0.pdf - Passivtasterkonzept";
CM_ SG_ 256 ESP_Systemstatus "Fehler steht für Stillegung ESP mit Fehlereintrag.
AUDI B8: Flag wird bei Unterspannung im Stand bis einmalig 6km/h überschritten wurden nicht gesetzt (Ausblendung Startvorgang)";
CM_ SG_ 256 ASR_Schalteingriff "Wunsch an das Getriebe während einer ASR Regelung, bei Audi nur 0x0 und 0x1 genutzt

";
CM_ SG_ 256 OBD_Schlechtweg "Für Ausblendung der Zündaussetzererkennung im Motorsteuergerät (Otto). Bit wird gesetzt, wenn Rad-Drehbeschleunigung im ESP > Grenzwert ist. Vorteil gegenüber Radgeschwindigkeiten, dass ESP alle 2 ms dynamisch die Rad-Drehbeschleunigung errechnet und dem ";
CM_ SG_ 256 ESP_QBit_v_Signal "Geschwindigkeit wird vom ESP aus Ersatzwerten errechnet, wenn Bit gesetzt ist. Güte des Signals ist verändert.

Im B8 gilt die Signalspezifikation: LAH 8K0907AG_V1.3.pdf - Geschwindigkeitausgabe BOSCH ESP ";
CM_ SG_ 256 ABS_Bremsung "Antiblockiersystem, Bit zeigt auch Druckabbau an (z.B. ESP hat zuviel Druck aufgebaut oder ungebremste Regelung auf Bahnübergang)";
CM_ SG_ 256 ASR_Anf "Die Momentenanforderung 'ASR_MSR_Moment_schnell' und 'ASR_Moment_langsam' sind auszuführen";
CM_ SG_ 256 MSR_Anf "Die Momentenanforderung 'ASR_MSR_Moment_schnell' ist auszuführen.";
CM_ SG_ 256 EBV_Eingriff "Elektronische Bremskraftverteilung, aktueller Eingriff (Druckhalten, Druckabbau), kein ABS / ESP-Eingriff";
CM_ SG_ 256 EDS_Eingriff "Elektronische Differentialsperre";
CM_ SG_ 256 ESP_Eingriff "Eingriff des Fahrdynamikreglers";
CM_ SG_ 256 ESP_ASP "Gilt nicht für PAG G1 Hybrid.
ASP = Anhaenger-Stabilisierungs-Programm";
CM_ SG_ 257 ESP_02_CHK "Berechnung siehe Lastenheft 'Kommunikationsabsicherung für FlexRay und CAN'
Endwerte siehe 'Kommunikationsabsicherung für FlexRay und CAN / Anhang C: Tabelle S-PDU Kennungen'";
CM_ SG_ 257 ESP_QBit_Gierrate "QBit der Giergeschwindigkeit, keine Filterung; ungültiger Wert kann bspw. aufgrund einer Unterspannung oder in der Initialisierungsphase ausgegeben werden.

Im D4 gilt das Dokument: 'Signaldefinition zwischen SARA und ESP im D4'";
CM_ SG_ 257 ESP_QBit_Laengsbeschl "Vorhalt VW / nicht AUDI:
QBit der Längsbeschleunigung

Im D4 gilt das Dokument: 'Signaldefinition zwischen SARA und ESP im D4'";
CM_ SG_ 257 ESP_QBit_Querb "Querbeschleunigung wird vom ESP aus Ersatzwerten errechnet, wenn Bit gesetzt ist. Güte des Signals ist verändert.

AUDI B8: Es wird kein Ersatzwert berechnet

Im D4 gilt das Dokument: 'Signaldefinition zwischen SARA und ESP im D4'";
CM_ SG_ 257 ESP_Stillstandsflag "Bei RB-Projekten wird das Stillstandsflag gesetzt, wenn der absolute Stillstand der Raddrehzahlsensoren erkannt wurde, d.h. kein Zahn bewegt sich mehr. Dieses Bit wird bspw. im MOST für TV-Tuner-Abschaltung Australien verwendet, d.h. leichte Erschütterung";
CM_ SG_ 257 ESP_Querbeschleunigung "In ESP-Projekten bspw. ContiTEVES und RB wird ein Sensor-Cluster verwendet, welcher den gemessenen Sensorwert ausgibt. 0xFF bedeutet hier die Größe kann nicht errechnet werden.

Im D4 erfolgt die Bereitstellung der Sensorwerte durch SARA-SG!";
CM_ SG_ 257 ESP_Laengsbeschl "Sensorwert Längsbeschleunigung vom Sensorcluster
Im D4 erfolgt die Bereitstellung der Sensorwerte durch SARA-SG!";
CM_ SG_ 257 ESP_Verteil_Wankmom "Gilt nicht für PAG G1 Hybrid.
Anforderung einer Wankmomentenverteilung an CDC (Exklusivnutzung!)";
CM_ SG_ 257 ESP_QBit_Anf_Vert_Wank "Gilt nicht für PAG G1 Hybrid.
QBit der Wankmomentenverteilung";
CM_ SG_ 257 ESP_Gierrate "Winkelgeschwindigkeit um die z-Achse

MLB: gemessener Wert
tatsächliche Auflösung Bosch ESP: 0,27 Grad/s";
CM_ SG_ 257 ESP_VZ_Gierrate "Vorzeichen der Gierrate";
CM_ SG_ 257 ESP_Notbremsanzeige "Im B8 gilt das Lastenheft Adaptives Bremslicht V18.0.doc

Im D4 gilt das Konzern-Funktions-LAH 'Notbremsanzeige Spezifikation V3.0 070620.doc'. In Pata0 setzt das ESP das NBA-Bit generell bei Vorliegen der definierten Eintrittsbedingungen (in Pata1 wird";
CM_ SG_ 257 ESP_SpannungsAnf "Die Rekuperation kann mit der Anforderung einer höheren Spannung eingeschränkt werden.";
CM_ BO_ 482 "CCP in Serie mit 11Bit - Empfangskanal";
CM_ SG_ 259 ESP_03_CHK "Berechnung siehe Lastenheft 'Kommunikationsabsicherung für FlexRay und CAN'
Endwerte siehe 'Kommunikationsabsicherung für FlexRay und CAN / Anhang C: Tabelle S-PDU Kennungen'";
CM_ SG_ 259 ESP_VL_FR "Fahrtrichtungserkennung Rad Vorne Links

Im B8 gilt die Signalspezifikation: LAH 8K0907AG_V1.3.pdf - Geschwindigkeitausgabe BOSCH ESP

Im D4 gilt die Spezifikation v-Signal im D4 v1.1";
CM_ SG_ 259 ESP_VR_FR "Fahrtrichtungserkennung Rad Vorne Rechts

Im B8 gilt die Signalspezifikation: LAH 8K0907AG_V1.3.pdf - Geschwindigkeitausgabe BOSCH ESP

Im D4 gilt die Spezifikation v-Signal im D4 v1.1";
CM_ SG_ 259 ESP_HL_FR "Fahrtrichtungserkennung Rad Hinten Links

Im B8 gilt die Signalspezifikation: LAH 8K0907AG_V1.3.pdf - Geschwindigkeitausgabe BOSCH ESP

Im D4 gilt die Spezifikation v-Signal im D4 v1.1";
CM_ SG_ 259 ESP_HR_FR "Fahrtrichtungserkennung Rad Hinten Rechts

Im B8 gilt die Signalspezifikation: LAH 8K0907AG_V1.3.pdf - Geschwindigkeitausgabe BOSCH ESP

Im D4 gilt die Spezifikation v-Signal im D4 v1.1";
CM_ SG_ 259 ESP_VL_Radgeschw "Im B8 gilt die Signalspezifikation: LAH 8K0907AG_V1.3.pdf - Geschwindigkeitausgabe BOSCH ESP

Im D4 gilt die Spezifikation v-Signal im D4 v1.1";
CM_ SG_ 259 ESP_VR_Radgeschw "Im B8 gilt die Signalspezifikation: LAH 8K0907AG_V1.3.pdf - Geschwindigkeitausgabe BOSCH ESP

Im D4 gilt die Spezifikation v-Signal im D4 v1.1";
CM_ SG_ 259 ESP_HL_Radgeschw "Im B8 gilt die Signalspezifikation: LAH 8K0907AG_V1.3.pdf - Geschwindigkeitausgabe BOSCH ESP

Im D4 gilt die Spezifikation v-Signal im D4 v1.1";
CM_ SG_ 259 ESP_HR_Radgeschw "Im B8 gilt die Signalspezifikation: LAH 8K0907AG_V1.3.pdf - Geschwindigkeitausgabe BOSCH ESP

Im D4 gilt die Spezifikation v-Signal im D4 v1.1";
CM_ SG_ 776 ESP_HDC_FktLampe "Funktionslampe Bergabfahrassistent.
(Sender blinkt mit dem Bit 3,3Hz)";
CM_ SG_ 776 ESP_ASR_Lampe "Signal wir nur im B8/Q5 verwendet um den Fehlerzustand des ESPs darzustellen.
In allen nachfolge Projekten werden für diese Funktion die alten Signale verwendet und dieses Signal ist ungültig. 

ESP_ASR_Lampe == 0
kein Stabilisierungseingriff, kein Fe";
CM_ SG_ 776 ESP_Meldungen "Gilt nicht für PAG G1 Hybrid (Kombischittstelle über CAN Fwk wie G1 Basisfzg.)
ESP sendet im Hinweis- /Störungsfall an das Kombi Informationen zum Anzeigen (Text + Akustik)";
CM_ SG_ 776 ESP_Lampe "Zustand der Fahrdynamikregelungslampe (ASR und/oder ESP)

Im B8 gilt LAH 8T0.907.B.pdf - Warn-Anzeigekonzept Bremssysteme

Im D4 gilt die Spezifikation Warn-Anzeige-LH D4";
CM_ SG_ 776 ABS_Lampe "Sicherheitswarnlampe

Im B8 gilt LAH 8T0.907.B.pdf - Warn-Anzeigekonzept Bremssysteme

Im D4 gilt die Spezifikation Warn-Anzeige-LH D4";
CM_ SG_ 776 BK_Lampe "Rote Lampe wird angesteuert, bspw. bei EBV-Ausfall; Sicherheitswarnlampe im Audi C6/D3/AU716. (Blinktakt wird wie bisher vom Kombi generiert). Separate Bremskontroll-Lampe (Audi ab D3/C6) wird als Sicherheitswarnlampe aufgeprüft (Initwert 1); Kombinierte ";
CM_ SG_ 776 ESP_Akustik "Gilt nicht für PAG G1 Hybrid (Kombischittstelle über CAN Fwk wie G1 Basisfzg.)
Akustik der Fahrdynamikregelung im Kombiinstrument";
CM_ SG_ 776 ESP_Diagnose "Nach Diagnoseende wird ein SW-Reset ausgelöst welcher einen Kommunikatiosausfall für max. 150ms verursacht. Dies ist bei SG mit verschärfter Timeoutüberwachung (nicht nach Konzern-LH) zu beachten.";
CM_ SG_ 776 ESP_Textanzeigen_02 "Gilt nicht für PAG G1 Hybrid (Kombischittstelle über CAN Fwk wie G1 Basisfzg.)
Textanzeigen der Fahrdynamikregelung im Kombiinstrument";
CM_ SG_ 776 ESP_Off_Lampe "Bit zur Ansteuerung der separaten ESP-off-Lampe im Kombi (Gesetzesforderung USA)";
CM_ SG_ 776 ESP_m_Raddrehz "Exklusiver Empfänger ist das Kombiinstrument! Radumdrehungen pro Sekunde sind Eingangsgröße für die Geschwindigkeitsberechnung im Kombi. Aus dieser Raddrehzahl und dem Radumfang wird die Fahrzeuggeschwindigkeit errechnet.

Im B8 gilt die Signalspezifika";
CM_ SG_ 776 ESP_Wegimp_VA "Die Wegimpulse Vorderachse sind die gemittelten Werte (reine mathematische Operation: Addition und Division durch zwei, keine Filterung) der Wegimpulse der Ränder VL und VR.

Im B8 gilt die Signalspezifikation: LAH 8K0907AG_V1.3.pdf - Geschwindigkeitaus";
CM_ SG_ 776 ESP_Fehlerstatus_Wegimp "Fehler wird gesetzt, wenn beide ESP-Drehzahlfühler an der Vorderachse defekt sind.

Im B8 gilt die Signalspezifikation: LAH 8K0907AG_V1.3.pdf - Geschwindigkeitausgabe BOSCH ESP

Im D4 gilt die Spezifikation v-Signal im D4 v1.1";
CM_ SG_ 776 ESP_Wegimp_Ueberlauf "Der Wegimpulszähler ist mindestens einmal übergelaufen

Im B8 gilt die Signalspezifikation: LAH 8K0907AG_V1.3.pdf - Geschwindigkeitausgabe BOSCH ESP

Im D4 gilt die Spezifikation v-Signal im D4 v1.1";
CM_ SG_ 776 ESP_QBit_Wegimp_VA "Im B8 gilt die Signalspezifikation: LAH 8K0907AG_V1.3.pdf - Geschwindigkeitausgabe BOSCH ESP

Im D4 gilt die Spezifikation v-Signal im D4 v1.1";
CM_ SG_ 776 ESP_Displaywarnungen "Prio1-Warnungen
Automatisch gekoppelt an diese Bremsenwarnung ist ein dreimaliger Warnton, der durch das Kombi selbstständig angesteuert wird, sobald eines der belegten Bits gesetzt ist.

0x2 - 0x3 = tbd.

Im B8 gilt LAH 8T0.907.B.pdf - Warn-Anzeigek";
CM_ SG_ 776 ESP_HDC_Regelgeschw "Gilt nicht für PAG G1 Hybrid (Kombischittstelle über CAN Fwk wie G1 Basisfzg.)
HDC-Geschwindigkeit
Dient der Anzeige der HDC-Geschwindigkeit und eines Bergabfahrsymbols im Kombi.";
CM_ SG_ 776 ESP_BKV_Warnung "ESP sendet im Hinweis- /Störungsfall an das Kombi Informationen zum Anzeigen (Text + Akustik)

- der Signalwert 1 wurde aus dem Signal ESP_Textanzeigen_02 (Wert 0xA) extrahiert und soll 
zukünftig über dieses Signal angezeigt werden  (ESP kann dadurch ";
CM_ SG_ 776 ESP_Zaehnezahl "Konstanter Wert der Zähnezahl des verwendeten Impulsrades wird ausgegeben, jeder Empfänger der Wegimpulse muss die Zähnezahl einlesen, um eine volle Umdrehung des Rades zu erkennen. 

Im B8 gilt die Signalspezifikation: LAH 8K0907AG_V1.3.pdf - Geschwind";
BA_DEF_ SG_  "DERIVATE_Pruefung" ENUM  "offen","geprüft";
BA_DEF_ SG_  "HYB_Rx_Baureihe" ENUM  "G1+Derivate","nur G1","nur Derivate";
BA_DEF_ SG_  "HYB_Rx_Verwendung" ENUM  "DERIV_Rout","DERIV_Calc","DERIV_Rout+DERIV_Calc";
BA_DEF_ SG_  "GenSigSwitchedByIgnition" ENUM  "No","Yes";
BA_DEF_ SG_  "GenSigEnvVarType" ENUM  "int","float","undef";
BA_DEF_ SG_  "GenSigAutoGenSnd" ENUM  "No","Yes";
BA_DEF_ SG_  "GenSigAutoGenDsp" ENUM  "No","Yes";
BA_DEF_ SG_  "GenSigActiveRepetitions" INT -2147483648 2147483647;
BA_DEF_ SG_  "GenSigFuncType" ENUM  "NoFunction","MsgCounter","CRC-8","XOR","XOR-2","DatedBit","SW-Kl15","CHK","Constant","Protocol";
BA_DEF_ SG_  "Info_BCM_HutHut_Kommunikation" ENUM  "Nein","Ja";
BA_DEF_ SG_  "NWM-WakeupAllowed" ENUM  "No","Yes";
BA_DEF_ SG_  "GenSigInactiveValue" STRING ;
BA_DEF_ SG_  "GenSigMissingSourceValue" INT 0 2147483647;
BA_DEF_ SG_  "GenSigStartValue" INT 0 0;
BA_DEF_ SG_  "Fehlerwert" HEX 0 2147483647;
BA_DEF_ SG_  "Bemerkung" STRING ;
BA_DEF_ SG_  "GenSigSendType" ENUM  "Cyclic","OnWrite","OnWriteWithRepetition","OnChange","OnChangeWithRepetition","IfActive","IfActiveWithRepetition","NoSigSendType";
BA_DEF_ BO_  "NmMessage" ENUM  "No","Yes";
BA_DEF_ BO_  "GenMsgAutoGenSnd" ENUM  "No","Yes";
BA_DEF_ BO_  "GenMsgAutoGenDsp" ENUM  "No","Yes";
BA_DEF_ BO_  "MsgType" ENUM  "Broadcast","Event","NM ","NMH","TP2.0","ISO-TP ","BAP","EID";
BA_DEF_ BO_  "GenMsgChkConstant" HEX 0 4095;
BA_DEF_ BO_  "sim_GenMsgILSupport" ENUM  "No","Yes";
BA_DEF_ BO_  "NWM-Botschaft" ENUM  "No","Yes";
BA_DEF_ BO_  "VAGTP20_StatConnection" ENUM  "No","Yes";
BA_DEF_ BO_  "VAGTP20_DynSetup" ENUM  "No","Yes";
BA_DEF_ BO_  "VAGTP20_DynConnection" ENUM  "No","Yes";
BA_DEF_ BO_  "VAGTP20_API" HEX 0 255;
BA_DEF_ BO_  "Direkt_1zu1" ENUM  "Nein","Ja";
BA_DEF_ BO_  "GenMsgSendType" ENUM  "Cyclic","NotUsed","NotUsed","NotUsed","NotUsed","NotUsed","NotUsed","IfActive","NoMsgSendType","NotUsed";
BA_DEF_ BO_  "DiagResponse" ENUM  "No","Yes";
BA_DEF_ BO_  "DiagRequest" ENUM  "No","Yes";
BA_DEF_ BO_  "GenMsgDelayTime" INT 0 65535;
BA_DEF_ BO_  "GenMsgStartDelayTime" INT 0 65535;
BA_DEF_ BO_  "GenMsgILSupport" ENUM  "No","Yes";
BA_DEF_ BO_  "NmhMessage" ENUM  "No","Yes";
BA_DEF_ BO_  "GenMsgNrOfRepetition" INT 0 65535;
BA_DEF_ BO_  "GenMsgCycleTimeFast" INT 0 65535;
BA_DEF_ BO_  "DiagState" ENUM  "No","Yes";
BA_DEF_ BO_  "GenMsgCycleTime" INT 0 65535;
BA_DEF_REL_ BU_BO_REL_  "HYB_Tx_Verwendung" ENUM  "Rout","Calc";
BA_DEF_REL_ BU_BO_REL_  "HYB_Tx_Baureihe" ENUM  "G1+Derivate","G1","Derivate","vector_leerstring";
BA_DEF_REL_ BU_SG_REL_  "GenSigTimeoutTime" INT 0 65535;
BA_DEF_DEF_REL_ "HYB_Tx_Verwendung" "Rout";
BA_DEF_DEF_REL_ "HYB_Tx_Baureihe" "G1+Derivate";
BA_DEF_DEF_  "DERIVATE_Pruefung" "offen";
BA_DEF_DEF_  "HYB_Rx_Baureihe" "G1+Derivate";
BA_DEF_DEF_  "HYB_Rx_Verwendung" "DERIV_Rout";
BA_DEF_DEF_  "GenSigSwitchedByIgnition" "No";
BA_DEF_DEF_  "GenSigEnvVarType" "undef";
BA_DEF_DEF_  "GenSigAutoGenSnd" "No";
BA_DEF_DEF_  "GenSigAutoGenDsp" "No";
BA_DEF_DEF_  "GenSigActiveRepetitions" 0;
BA_DEF_DEF_  "GenSigFuncType" "NoFunction";
BA_DEF_DEF_  "Info_BCM_HutHut_Kommunikation" "Nein";
BA_DEF_DEF_  "NWM-WakeupAllowed" "Yes";
BA_DEF_DEF_  "GenSigInactiveValue" "0";
BA_DEF_DEF_  "GenSigMissingSourceValue" 0;
BA_DEF_DEF_  "GenSigStartValue" 0;
BA_DEF_DEF_  "Fehlerwert" 0;
BA_DEF_DEF_  "Bemerkung" "";
BA_DEF_DEF_  "GenSigSendType" "Cyclic";
BA_DEF_DEF_  "NmMessage" "No";
BA_DEF_DEF_  "GenMsgAutoGenSnd" "Yes";
BA_DEF_DEF_  "GenMsgAutoGenDsp" "Yes";
BA_DEF_DEF_  "MsgType" "Broadcast";
BA_DEF_DEF_  "GenMsgChkConstant" 0;
BA_DEF_DEF_  "sim_GenMsgILSupport" "No";
BA_DEF_DEF_  "NWM-Botschaft" "No";
BA_DEF_DEF_  "VAGTP20_StatConnection" "No";
BA_DEF_DEF_  "VAGTP20_DynSetup" "No";
BA_DEF_DEF_  "VAGTP20_DynConnection" "No";
BA_DEF_DEF_  "VAGTP20_API" 1;
BA_DEF_DEF_  "Direkt_1zu1" "Nein";
BA_DEF_DEF_  "GenMsgSendType" "Cyclic";
BA_DEF_DEF_  "DiagResponse" "No";
BA_DEF_DEF_  "DiagRequest" "No";
BA_DEF_DEF_  "GenMsgDelayTime" 0;
BA_DEF_DEF_  "GenMsgStartDelayTime" 0;
BA_DEF_DEF_  "GenMsgILSupport" "No";
BA_DEF_DEF_  "NmhMessage" "No";
BA_DEF_DEF_  "GenMsgNrOfRepetition" 0;
BA_DEF_DEF_  "GenMsgCycleTimeFast" 0;
BA_DEF_DEF_  "DiagState" "No";
BA_DEF_DEF_  "GenMsgCycleTime" 0;
BA_DEF_DEF_REL_ "GenSigTimeoutTime" 0;
BA_ "VAGTP20_API" BO_ 1446 0;
BA_ "GenMsgILSupport" BO_ 1446 1;
BA_ "GenMsgCycleTime" BO_ 1446 500;
BA_ "VAGTP20_API" BO_ 1445 0;
BA_ "GenMsgILSupport" BO_ 1445 1;
BA_ "GenMsgCycleTime" BO_ 1445 2000;
BA_ "VAGTP20_API" BO_ 1666 0;
BA_ "GenMsgSendType" BO_ 1666 8;
BA_ "VAGTP20_API" BO_ 2617239041 0;
BA_ "GenMsgSendType" BO_ 2617239041 8;
BA_ "VAGTP20_API" BO_ 1527 0;
BA_ "GenMsgILSupport" BO_ 1527 1;
BA_ "GenMsgCycleTime" BO_ 1527 1000;
BA_ "VAGTP20_API" BO_ 1525 0;
BA_ "GenMsgILSupport" BO_ 1525 1;
BA_ "GenMsgCycleTime" BO_ 1525 1000;
BA_ "VAGTP20_API" BO_ 687 0;
BA_ "GenMsgILSupport" BO_ 687 1;
BA_ "GenMsgCycleTime" BO_ 687 50;
BA_ "VAGTP20_API" BO_ 1532 0;
BA_ "GenMsgILSupport" BO_ 1532 1;
BA_ "GenMsgCycleTime" BO_ 1532 500;
BA_ "MsgType" BO_ 1788 3;
BA_ "VAGTP20_API" BO_ 1788 0;
BA_ "GenMsgSendType" BO_ 1788 8;
BA_ "NmhMessage" BO_ 1788 1;
BA_ "GenMsgCycleTime" BO_ 1788 200;
BA_ "GenMsgAutoGenSnd" BO_ 1966 0;
BA_ "GenMsgAutoGenDsp" BO_ 1966 0;
BA_ "MsgType" BO_ 1966 5;
BA_ "VAGTP20_API" BO_ 1966 0;
BA_ "GenMsgSendType" BO_ 1966 8;
BA_ "DiagResponse" BO_ 1966 1;
BA_ "GenMsgAutoGenSnd" BO_ 1860 0;
BA_ "GenMsgAutoGenDsp" BO_ 1860 0;
BA_ "MsgType" BO_ 1860 5;
BA_ "VAGTP20_API" BO_ 1860 0;
BA_ "GenMsgSendType" BO_ 1860 8;
BA_ "DiagRequest" BO_ 1860 1;
BA_ "VAGTP20_API" BO_ 1483 0;
BA_ "GenMsgDelayTime" BO_ 1483 100;
BA_ "GenMsgILSupport" BO_ 1483 1;
BA_ "GenMsgCycleTime" BO_ 1483 500;
BA_ "VAGTP20_API" BO_ 899 0;
BA_ "GenMsgILSupport" BO_ 899 1;
BA_ "GenMsgCycleTime" BO_ 899 100;
BA_ "VAGTP20_API" BO_ 1518 0;
BA_ "GenMsgILSupport" BO_ 1518 1;
BA_ "GenMsgCycleTime" BO_ 1518 1000;
BA_ "VAGTP20_API" BO_ 391 0;
BA_ "GenMsgDelayTime" BO_ 391 40;
BA_ "GenMsgILSupport" BO_ 391 1;
BA_ "GenMsgCycleTime" BO_ 391 100;
BA_ "VAGTP20_API" BO_ 1662 0;
BA_ "GenMsgDelayTime" BO_ 1662 50;
BA_ "GenMsgILSupport" BO_ 1662 1;
BA_ "GenMsgCycleTime" BO_ 1662 1000;
BA_ "VAGTP20_API" BO_ 1380 0;
BA_ "GenMsgDelayTime" BO_ 1380 100;
BA_ "GenMsgILSupport" BO_ 1380 1;
BA_ "GenMsgNrOfRepetition" BO_ 1380 5;
BA_ "GenMsgCycleTimeFast" BO_ 1380 100;
BA_ "GenMsgCycleTime" BO_ 1380 1000;
BA_ "VAGTP20_API" BO_ 1385 0;
BA_ "GenMsgDelayTime" BO_ 1385 50;
BA_ "GenMsgILSupport" BO_ 1385 1;
BA_ "GenMsgCycleTime" BO_ 1385 500;
BA_ "GenMsgChkConstant" BO_ 1482 67;
BA_ "VAGTP20_API" BO_ 1482 0;
BA_ "GenMsgDelayTime" BO_ 1482 50;
BA_ "GenMsgILSupport" BO_ 1482 1;
BA_ "GenMsgCycleTime" BO_ 1482 500;
BA_ "VAGTP20_API" BO_ 1519 0;
BA_ "GenMsgILSupport" BO_ 1519 1;
BA_ "GenMsgCycleTime" BO_ 1519 500;
BA_ "VAGTP20_API" BO_ 1438 0;
BA_ "GenMsgILSupport" BO_ 1438 1;
BA_ "GenMsgCycleTime" BO_ 1438 500;
BA_ "VAGTP20_API" BO_ 1428 0;
BA_ "GenMsgDelayTime" BO_ 1428 50;
BA_ "GenMsgILSupport" BO_ 1428 1;
BA_ "GenMsgCycleTime" BO_ 1428 500;
BA_ "VAGTP20_API" BO_ 305 0;
BA_ "GenMsgILSupport" BO_ 305 1;
BA_ "GenMsgCycleTime" BO_ 305 20;
BA_ "GenMsgChkConstant" BO_ 914 145;
BA_ "GenMsgILSupport" BO_ 914 1;
BA_ "GenMsgCycleTime" BO_ 914 80;
BA_ "VAGTP20_API" BO_ 906 0;
BA_ "GenMsgILSupport" BO_ 906 1;
BA_ "GenMsgCycleTimeFast" BO_ 906 100;
BA_ "GenMsgCycleTime" BO_ 906 100;
BA_ "MsgType" BO_ 1731 3;
BA_ "VAGTP20_API" BO_ 1731 0;
BA_ "GenMsgSendType" BO_ 1731 8;
BA_ "NmhMessage" BO_ 1731 1;
BA_ "GenMsgCycleTime" BO_ 1731 200;
BA_ "sim_GenMsgILSupport" BO_ 946 1;
BA_ "VAGTP20_API" BO_ 946 0;
BA_ "GenMsgILSupport" BO_ 946 1;
BA_ "GenMsgCycleTime" BO_ 946 100;
BA_ "sim_GenMsgILSupport" BO_ 1628 1;
BA_ "VAGTP20_API" BO_ 1628 0;
BA_ "GenMsgILSupport" BO_ 1628 1;
BA_ "GenMsgCycleTime" BO_ 1628 500;
BA_ "MsgType" BO_ 490 7;
BA_ "VAGTP20_API" BO_ 490 0;
BA_ "GenMsgSendType" BO_ 490 8;
BA_ "MsgType" BO_ 488 7;
BA_ "VAGTP20_API" BO_ 488 0;
BA_ "GenMsgSendType" BO_ 488 8;
BA_ "MsgType" BO_ 2616986625 7;
BA_ "VAGTP20_API" BO_ 2616986625 0;
BA_ "GenMsgSendType" BO_ 2616986625 8;
BA_ "sim_GenMsgILSupport" BO_ 945 1;
BA_ "VAGTP20_API" BO_ 945 0;
BA_ "GenMsgILSupport" BO_ 945 1;
BA_ "GenMsgCycleTime" BO_ 945 100;
BA_ "sim_GenMsgILSupport" BO_ 1627 1;
BA_ "VAGTP20_API" BO_ 1627 0;
BA_ "GenMsgILSupport" BO_ 1627 1;
BA_ "GenMsgCycleTime" BO_ 1627 500;
BA_ "GenMsgChkConstant" BO_ 256 171;
BA_ "sim_GenMsgILSupport" BO_ 256 1;
BA_ "VAGTP20_API" BO_ 256 0;
BA_ "Direkt_1zu1" BO_ 256 1;
BA_ "GenMsgILSupport" BO_ 256 1;
BA_ "GenMsgCycleTime" BO_ 256 20;
BA_ "GenMsgChkConstant" BO_ 257 170;
BA_ "sim_GenMsgILSupport" BO_ 257 1;
BA_ "VAGTP20_API" BO_ 257 0;
BA_ "Direkt_1zu1" BO_ 257 1;
BA_ "GenMsgILSupport" BO_ 257 1;
BA_ "GenMsgCycleTime" BO_ 257 20;
BA_ "MsgType" BO_ 1795 5;
BA_ "VAGTP20_API" BO_ 1795 0;
BA_ "Direkt_1zu1" BO_ 1795 1;
BA_ "GenMsgSendType" BO_ 1795 8;
BA_ "DiagState" BO_ 1795 1;
BA_ "MsgType" BO_ 482 7;
BA_ "VAGTP20_API" BO_ 482 0;
BA_ "GenMsgSendType" BO_ 482 8;
BA_ "GenMsgChkConstant" BO_ 259 2;
BA_ "sim_GenMsgILSupport" BO_ 259 1;
BA_ "VAGTP20_API" BO_ 259 0;
BA_ "Direkt_1zu1" BO_ 259 1;
BA_ "GenMsgILSupport" BO_ 259 1;
BA_ "GenMsgCycleTime" BO_ 259 20;
BA_ "sim_GenMsgILSupport" BO_ 776 1;
BA_ "VAGTP20_API" BO_ 776 0;
BA_ "GenMsgILSupport" BO_ 776 1;
BA_ "GenMsgCycleTime" BO_ 776 50;
BA_ "NWM-WakeupAllowed" SG_ 1446 OBC_KomponentenFehler_01 0;
BA_ "GenSigStartValue" SG_ 1446 OBC_KomponentenFehler_01 2;
BA_ "NWM-WakeupAllowed" SG_ 1446 OBC_KomponentenFehler_02 0;
BA_ "GenSigStartValue" SG_ 1446 OBC_KomponentenFehler_02 2;
BA_ "NWM-WakeupAllowed" SG_ 1446 OBC_KomponentenFehler_03 0;
BA_ "GenSigStartValue" SG_ 1446 OBC_KomponentenFehler_03 2;
BA_ "NWM-WakeupAllowed" SG_ 1446 OBC_KomponentenFehler_04 0;
BA_ "GenSigStartValue" SG_ 1446 OBC_KomponentenFehler_04 2;
BA_ "NWM-WakeupAllowed" SG_ 1446 OBC_KomponentenFehler_05 0;
BA_ "GenSigStartValue" SG_ 1446 OBC_KomponentenFehler_05 2;
BA_ "NWM-WakeupAllowed" SG_ 1446 OBC_KomponentenFehler_06 0;
BA_ "GenSigStartValue" SG_ 1446 OBC_KomponentenFehler_06 2;
BA_ "NWM-WakeupAllowed" SG_ 1446 OBC_KomponentenFehler_07 0;
BA_ "GenSigStartValue" SG_ 1446 OBC_KomponentenFehler_07 2;
BA_ "NWM-WakeupAllowed" SG_ 1446 OBC_KomponentenFehler_08 0;
BA_ "GenSigStartValue" SG_ 1446 OBC_KomponentenFehler_08 2;
BA_ "NWM-WakeupAllowed" SG_ 1446 OBC_KomponentenFehler_09 0;
BA_ "GenSigStartValue" SG_ 1446 OBC_KomponentenFehler_09 2;
BA_ "NWM-WakeupAllowed" SG_ 1446 OBC_KomponentenFehler_10 0;
BA_ "GenSigStartValue" SG_ 1446 OBC_KomponentenFehler_10 2;
BA_ "NWM-WakeupAllowed" SG_ 1446 OBC_KomponentenFehler_11 0;
BA_ "GenSigStartValue" SG_ 1446 OBC_KomponentenFehler_11 2;
BA_ "NWM-WakeupAllowed" SG_ 1446 OBC_KomponentenFehler_12 0;
BA_ "GenSigStartValue" SG_ 1446 OBC_KomponentenFehler_12 2;
BA_ "NWM-WakeupAllowed" SG_ 1446 OBC_KomponentenFehler_13 0;
BA_ "GenSigStartValue" SG_ 1446 OBC_KomponentenFehler_13 2;
BA_ "NWM-WakeupAllowed" SG_ 1446 OBC_KomponentenFehler_14 0;
BA_ "GenSigStartValue" SG_ 1446 OBC_KomponentenFehler_14 2;
BA_ "NWM-WakeupAllowed" SG_ 1446 OBC_KomponentenFehler_15 0;
BA_ "GenSigStartValue" SG_ 1446 OBC_KomponentenFehler_15 2;
BA_ "NWM-WakeupAllowed" SG_ 1446 OBC_KomponentenFehler_16 0;
BA_ "GenSigStartValue" SG_ 1446 OBC_KomponentenFehler_16 2;
BA_ "NWM-WakeupAllowed" SG_ 1446 OBC_KomponentenFehler_17 0;
BA_ "GenSigStartValue" SG_ 1446 OBC_KomponentenFehler_17 2;
BA_ "NWM-WakeupAllowed" SG_ 1446 OBC_KomponentenFehler_18 0;
BA_ "GenSigStartValue" SG_ 1446 OBC_KomponentenFehler_18 2;
BA_ "NWM-WakeupAllowed" SG_ 1446 OBC_KomponentenFehler_19 0;
BA_ "GenSigStartValue" SG_ 1446 OBC_KomponentenFehler_19 2;
BA_ "NWM-WakeupAllowed" SG_ 1446 OBC_KomponentenFehler_20 0;
BA_ "GenSigStartValue" SG_ 1446 OBC_KomponentenFehler_20 2;
BA_ "NWM-WakeupAllowed" SG_ 1446 OBC_KomponentenFehler_21 0;
BA_ "GenSigStartValue" SG_ 1446 OBC_KomponentenFehler_21 2;
BA_ "NWM-WakeupAllowed" SG_ 1446 OBC_KomponentenFehler_22 0;
BA_ "GenSigStartValue" SG_ 1446 OBC_KomponentenFehler_22 2;
BA_ "NWM-WakeupAllowed" SG_ 1446 OBC_KomponentenFehler_23 0;
BA_ "GenSigStartValue" SG_ 1446 OBC_KomponentenFehler_23 2;
BA_ "NWM-WakeupAllowed" SG_ 1446 OBC_KomponentenFehler_24 0;
BA_ "GenSigStartValue" SG_ 1446 OBC_KomponentenFehler_24 2;
BA_ "NWM-WakeupAllowed" SG_ 1446 OBC_KomponentenFehler_25 0;
BA_ "GenSigStartValue" SG_ 1446 OBC_KomponentenFehler_25 2;
BA_ "NWM-WakeupAllowed" SG_ 1446 OBC_KomponentenFehler_26 0;
BA_ "GenSigStartValue" SG_ 1446 OBC_KomponentenFehler_26 2;
BA_ "NWM-WakeupAllowed" SG_ 1446 OBC_KomponentenFehler_27 0;
BA_ "GenSigStartValue" SG_ 1446 OBC_KomponentenFehler_27 2;
BA_ "NWM-WakeupAllowed" SG_ 1446 OBC_KomponentenFehler_28 0;
BA_ "GenSigStartValue" SG_ 1446 OBC_KomponentenFehler_28 2;
BA_ "NWM-WakeupAllowed" SG_ 1446 OBC_KomponentenFehler_29 0;
BA_ "GenSigStartValue" SG_ 1446 OBC_KomponentenFehler_29 2;
BA_ "NWM-WakeupAllowed" SG_ 1446 OBC_KomponentenFehler_30 0;
BA_ "GenSigStartValue" SG_ 1446 OBC_KomponentenFehler_30 2;
BA_ "NWM-WakeupAllowed" SG_ 1446 OBC_KomponentenFehler_31 0;
BA_ "GenSigStartValue" SG_ 1446 OBC_KomponentenFehler_31 2;
BA_ "NWM-WakeupAllowed" SG_ 1446 OBC_KomponentenFehler_32 0;
BA_ "GenSigStartValue" SG_ 1446 OBC_KomponentenFehler_32 2;
BA_ "GenSigSendType" SG_ 1445 OBC_CVN_VLD 7;
BA_ "GenSigSwitchedByIgnition" SG_ 1445 OBC_CVN_VLD 1;
BA_ "NWM-WakeupAllowed" SG_ 1445 OBC_CVN_VLD 0;
BA_ "GenSigSendType" SG_ 1445 OBC_CALID_Index_01 7;
BA_ "GenSigSwitchedByIgnition" SG_ 1445 OBC_CALID_Index_01 1;
BA_ "NWM-WakeupAllowed" SG_ 1445 OBC_CALID_Index_01 0;
BA_ "GenSigStartValue" SG_ 1445 OBC_CALID_Index_01 48;
BA_ "GenSigSendType" SG_ 1445 OBC_CALID_Index_05 7;
BA_ "GenSigSwitchedByIgnition" SG_ 1445 OBC_CALID_Index_05 1;
BA_ "NWM-WakeupAllowed" SG_ 1445 OBC_CALID_Index_05 0;
BA_ "GenSigStartValue" SG_ 1445 OBC_CALID_Index_05 48;
BA_ "GenSigSendType" SG_ 1445 OBC_CALID_Index_09 7;
BA_ "GenSigSwitchedByIgnition" SG_ 1445 OBC_CALID_Index_09 1;
BA_ "NWM-WakeupAllowed" SG_ 1445 OBC_CALID_Index_09 0;
BA_ "GenSigStartValue" SG_ 1445 OBC_CALID_Index_09 48;
BA_ "GenSigSendType" SG_ 1445 OBC_CALID_Index_13 7;
BA_ "GenSigSwitchedByIgnition" SG_ 1445 OBC_CALID_Index_13 1;
BA_ "NWM-WakeupAllowed" SG_ 1445 OBC_CALID_Index_13 0;
BA_ "GenSigStartValue" SG_ 1445 OBC_CALID_Index_13 48;
BA_ "GenSigSendType" SG_ 1445 OBC_CALID_Index_02 7;
BA_ "GenSigSwitchedByIgnition" SG_ 1445 OBC_CALID_Index_02 1;
BA_ "NWM-WakeupAllowed" SG_ 1445 OBC_CALID_Index_02 0;
BA_ "GenSigStartValue" SG_ 1445 OBC_CALID_Index_02 48;
BA_ "GenSigSendType" SG_ 1445 OBC_CALID_Index_06 7;
BA_ "GenSigSwitchedByIgnition" SG_ 1445 OBC_CALID_Index_06 1;
BA_ "NWM-WakeupAllowed" SG_ 1445 OBC_CALID_Index_06 0;
BA_ "GenSigStartValue" SG_ 1445 OBC_CALID_Index_06 48;
BA_ "GenSigSendType" SG_ 1445 OBC_CALID_Index_10 7;
BA_ "GenSigSwitchedByIgnition" SG_ 1445 OBC_CALID_Index_10 1;
BA_ "NWM-WakeupAllowed" SG_ 1445 OBC_CALID_Index_10 0;
BA_ "GenSigStartValue" SG_ 1445 OBC_CALID_Index_10 48;
BA_ "GenSigSendType" SG_ 1445 OBC_CALID_Index_14 7;
BA_ "GenSigSwitchedByIgnition" SG_ 1445 OBC_CALID_Index_14 1;
BA_ "NWM-WakeupAllowed" SG_ 1445 OBC_CALID_Index_14 0;
BA_ "GenSigStartValue" SG_ 1445 OBC_CALID_Index_14 48;
BA_ "GenSigSendType" SG_ 1445 OBC_CALID_Index_03 7;
BA_ "GenSigSwitchedByIgnition" SG_ 1445 OBC_CALID_Index_03 1;
BA_ "NWM-WakeupAllowed" SG_ 1445 OBC_CALID_Index_03 0;
BA_ "GenSigStartValue" SG_ 1445 OBC_CALID_Index_03 48;
BA_ "GenSigSendType" SG_ 1445 OBC_CALID_Index_07 7;
BA_ "GenSigSwitchedByIgnition" SG_ 1445 OBC_CALID_Index_07 1;
BA_ "NWM-WakeupAllowed" SG_ 1445 OBC_CALID_Index_07 0;
BA_ "GenSigStartValue" SG_ 1445 OBC_CALID_Index_07 48;
BA_ "GenSigSendType" SG_ 1445 OBC_CALID_Index_11 7;
BA_ "GenSigSwitchedByIgnition" SG_ 1445 OBC_CALID_Index_11 1;
BA_ "NWM-WakeupAllowed" SG_ 1445 OBC_CALID_Index_11 0;
BA_ "GenSigStartValue" SG_ 1445 OBC_CALID_Index_11 48;
BA_ "GenSigSendType" SG_ 1445 OBC_CALID_Index_15 7;
BA_ "GenSigSwitchedByIgnition" SG_ 1445 OBC_CALID_Index_15 1;
BA_ "NWM-WakeupAllowed" SG_ 1445 OBC_CALID_Index_15 0;
BA_ "GenSigStartValue" SG_ 1445 OBC_CALID_Index_15 48;
BA_ "GenSigSendType" SG_ 1445 OBC_CALID_Index_04 7;
BA_ "GenSigSwitchedByIgnition" SG_ 1445 OBC_CALID_Index_04 1;
BA_ "NWM-WakeupAllowed" SG_ 1445 OBC_CALID_Index_04 0;
BA_ "GenSigStartValue" SG_ 1445 OBC_CALID_Index_04 48;
BA_ "GenSigSendType" SG_ 1445 OBC_CALID_Index_08 7;
BA_ "GenSigSwitchedByIgnition" SG_ 1445 OBC_CALID_Index_08 1;
BA_ "NWM-WakeupAllowed" SG_ 1445 OBC_CALID_Index_08 0;
BA_ "GenSigStartValue" SG_ 1445 OBC_CALID_Index_08 48;
BA_ "GenSigSendType" SG_ 1445 OBC_CALID_Index_12 7;
BA_ "GenSigSwitchedByIgnition" SG_ 1445 OBC_CALID_Index_12 1;
BA_ "NWM-WakeupAllowed" SG_ 1445 OBC_CALID_Index_12 0;
BA_ "GenSigStartValue" SG_ 1445 OBC_CALID_Index_12 48;
BA_ "GenSigSendType" SG_ 1445 OBC_CALID_Index_16 7;
BA_ "GenSigSwitchedByIgnition" SG_ 1445 OBC_CALID_Index_16 1;
BA_ "NWM-WakeupAllowed" SG_ 1445 OBC_CALID_Index_16 0;
BA_ "GenSigStartValue" SG_ 1445 OBC_CALID_Index_16 48;
BA_ "GenSigSendType" SG_ 1445 OBC_CVN_Byte_1 7;
BA_ "GenSigSwitchedByIgnition" SG_ 1445 OBC_CVN_Byte_1 1;
BA_ "NWM-WakeupAllowed" SG_ 1445 OBC_CVN_Byte_1 0;
BA_ "GenSigSendType" SG_ 1445 OBC_CVN_Byte_2 7;
BA_ "GenSigSwitchedByIgnition" SG_ 1445 OBC_CVN_Byte_2 1;
BA_ "NWM-WakeupAllowed" SG_ 1445 OBC_CVN_Byte_2 0;
BA_ "GenSigSendType" SG_ 1445 OBC_CVN_Byte_3 7;
BA_ "GenSigSwitchedByIgnition" SG_ 1445 OBC_CVN_Byte_3 1;
BA_ "NWM-WakeupAllowed" SG_ 1445 OBC_CVN_Byte_3 0;
BA_ "GenSigSwitchedByIgnition" SG_ 1445 OBC_CALID_CVN_MUX 1;
BA_ "NWM-WakeupAllowed" SG_ 1445 OBC_CALID_CVN_MUX 0;
BA_ "GenSigSendType" SG_ 1445 OBC_CVN_Byte_4 7;
BA_ "GenSigSwitchedByIgnition" SG_ 1445 OBC_CVN_Byte_4 1;
BA_ "NWM-WakeupAllowed" SG_ 1445 OBC_CVN_Byte_4 0;
BA_ "NWM-WakeupAllowed" SG_ 1666 CCP_LE_CRO_01_Data 0;
BA_ "NWM-WakeupAllowed" SG_ 2617239041 CCP_LE_DTO_01_Data 0;
BA_ "NWM-WakeupAllowed" SG_ 1527 RW_Sekundaer_Reichweite 0;
BA_ "GenSigStartValue" SG_ 1527 RW_Sekundaer_Reichweite 2046;
BA_ "Fehlerwert" SG_ 1527 RW_Sekundaer_Reichweite 2047;
BA_ "NWM-WakeupAllowed" SG_ 1527 RW_Sek_Reichweitenv_Einheit 0;
BA_ "GenSigStartValue" SG_ 1527 RW_Sek_Reichweitenv_Einheit 3;
BA_ "NWM-WakeupAllowed" SG_ 1527 RW_Sek_Reichweitenverbrauch 0;
BA_ "GenSigStartValue" SG_ 1527 RW_Sek_Reichweitenverbrauch 2047;
BA_ "GenSigEnvVarType" SG_ 1525 RW_RWDS_Lastprofil 0;
BA_ "GenSigAutoGenSnd" SG_ 1525 RW_RWDS_Lastprofil 1;
BA_ "GenSigAutoGenDsp" SG_ 1525 RW_RWDS_Lastprofil 1;
BA_ "NWM-WakeupAllowed" SG_ 1525 RW_RWDS_Lastprofil 0;
BA_ "Fehlerwert" SG_ 1525 RW_RWDS_Lastprofil 2047;
BA_ "NWM-WakeupAllowed" SG_ 1525 RW_Gesamt_Reichweite 0;
BA_ "GenSigStartValue" SG_ 1525 RW_Gesamt_Reichweite 2046;
BA_ "Fehlerwert" SG_ 1525 RW_Gesamt_Reichweite 2047;
BA_ "NWM-WakeupAllowed" SG_ 1525 RW_Prim_Reichweitenverbrauch 0;
BA_ "GenSigStartValue" SG_ 1525 RW_Prim_Reichweitenverbrauch 2047;
BA_ "NWM-WakeupAllowed" SG_ 1525 RW_Prim_Reichweitenv_Einheit 0;
BA_ "GenSigStartValue" SG_ 1525 RW_Prim_Reichweitenv_Einheit 3;
BA_ "NWM-WakeupAllowed" SG_ 1525 RW_Primaer_Reichweite 0;
BA_ "GenSigStartValue" SG_ 1525 RW_Primaer_Reichweite 2046;
BA_ "Fehlerwert" SG_ 1525 RW_Primaer_Reichweite 2047;
BA_ "GenSigEnvVarType" SG_ 687 BMS_Rekuperation 0;
BA_ "GenSigAutoGenSnd" SG_ 687 BMS_Rekuperation 1;
BA_ "GenSigAutoGenDsp" SG_ 687 BMS_Rekuperation 1;
BA_ "NWM-WakeupAllowed" SG_ 687 BMS_Rekuperation 0;
BA_ "GenSigEnvVarType" SG_ 687 BMS_Rekuperation_Ueberlauf 0;
BA_ "GenSigAutoGenSnd" SG_ 687 BMS_Rekuperation_Ueberlauf 1;
BA_ "GenSigAutoGenDsp" SG_ 687 BMS_Rekuperation_Ueberlauf 1;
BA_ "NWM-WakeupAllowed" SG_ 687 BMS_Rekuperation_Ueberlauf 0;
BA_ "GenSigEnvVarType" SG_ 687 BMS_Verbrauch 0;
BA_ "GenSigAutoGenSnd" SG_ 687 BMS_Verbrauch 1;
BA_ "GenSigAutoGenDsp" SG_ 687 BMS_Verbrauch 1;
BA_ "NWM-WakeupAllowed" SG_ 687 BMS_Verbrauch 0;
BA_ "GenSigEnvVarType" SG_ 687 BMS_Verbrauch_Ueberlauf 0;
BA_ "GenSigAutoGenSnd" SG_ 687 BMS_Verbrauch_Ueberlauf 1;
BA_ "GenSigAutoGenDsp" SG_ 687 BMS_Verbrauch_Ueberlauf 1;
BA_ "NWM-WakeupAllowed" SG_ 687 BMS_Verbrauch_Ueberlauf 0;
BA_ "GenSigAutoGenSnd" SG_ 1532 KL_Autobetrieb_HL 1;
BA_ "GenSigAutoGenDsp" SG_ 1532 KL_Autobetrieb_HL 1;
BA_ "NWM-WakeupAllowed" SG_ 1532 KL_Autobetrieb_HL 0;
BA_ "GenSigAutoGenSnd" SG_ 1532 KL_Autobetrieb_HR 1;
BA_ "GenSigAutoGenDsp" SG_ 1532 KL_Autobetrieb_HR 1;
BA_ "NWM-WakeupAllowed" SG_ 1532 KL_Autobetrieb_HR 0;
BA_ "GenSigAutoGenSnd" SG_ 1532 KL_Autobetrieb_VL 1;
BA_ "GenSigAutoGenDsp" SG_ 1532 KL_Autobetrieb_VL 1;
BA_ "NWM-WakeupAllowed" SG_ 1532 KL_Autobetrieb_VL 0;
BA_ "GenSigAutoGenSnd" SG_ 1532 KL_Autobetrieb_VR 1;
BA_ "GenSigAutoGenDsp" SG_ 1532 KL_Autobetrieb_VR 1;
BA_ "NWM-WakeupAllowed" SG_ 1532 KL_Autobetrieb_VR 0;
BA_ "GenSigAutoGenSnd" SG_ 1532 KL_Zieltemperatur_HL 1;
BA_ "GenSigAutoGenDsp" SG_ 1532 KL_Zieltemperatur_HL 1;
BA_ "NWM-WakeupAllowed" SG_ 1532 KL_Zieltemperatur_HL 0;
BA_ "GenSigStartValue" SG_ 1532 KL_Zieltemperatur_HL 30;
BA_ "Fehlerwert" SG_ 1532 KL_Zieltemperatur_HL 31;
BA_ "GenSigAutoGenSnd" SG_ 1532 KL_Zieltemperatur_HR 1;
BA_ "GenSigAutoGenDsp" SG_ 1532 KL_Zieltemperatur_HR 1;
BA_ "NWM-WakeupAllowed" SG_ 1532 KL_Zieltemperatur_HR 0;
BA_ "GenSigStartValue" SG_ 1532 KL_Zieltemperatur_HR 30;
BA_ "Fehlerwert" SG_ 1532 KL_Zieltemperatur_HR 31;
BA_ "GenSigAutoGenSnd" SG_ 1532 KL_Zieltemperatur_VL 1;
BA_ "GenSigAutoGenDsp" SG_ 1532 KL_Zieltemperatur_VL 1;
BA_ "NWM-WakeupAllowed" SG_ 1532 KL_Zieltemperatur_VL 0;
BA_ "GenSigStartValue" SG_ 1532 KL_Zieltemperatur_VL 30;
BA_ "Fehlerwert" SG_ 1532 KL_Zieltemperatur_VL 31;
BA_ "GenSigAutoGenSnd" SG_ 1532 KL_Zieltemperatur_VR 1;
BA_ "GenSigAutoGenDsp" SG_ 1532 KL_Zieltemperatur_VR 1;
BA_ "NWM-WakeupAllowed" SG_ 1532 KL_Zieltemperatur_VR 0;
BA_ "GenSigStartValue" SG_ 1532 KL_Zieltemperatur_VR 30;
BA_ "Fehlerwert" SG_ 1532 KL_Zieltemperatur_VR 31;
BA_ "GenSigAutoGenSnd" SG_ 1788 NMH_Ladegeraet_Start_1 1;
BA_ "GenSigAutoGenDsp" SG_ 1788 NMH_Ladegeraet_Start_1 1;
BA_ "NWM-WakeupAllowed" SG_ 1788 NMH_Ladegeraet_Start_1 0;
BA_ "GenSigAutoGenSnd" SG_ 1788 NMH_Ladegeraet_Start_2 1;
BA_ "GenSigAutoGenDsp" SG_ 1788 NMH_Ladegeraet_Start_2 1;
BA_ "NWM-WakeupAllowed" SG_ 1788 NMH_Ladegeraet_Start_2 0;
BA_ "GenSigAutoGenSnd" SG_ 1788 NMH_Ladegeraet_Normal_Mode_1 1;
BA_ "GenSigAutoGenDsp" SG_ 1788 NMH_Ladegeraet_Normal_Mode_1 1;
BA_ "NWM-WakeupAllowed" SG_ 1788 NMH_Ladegeraet_Normal_Mode_1 0;
BA_ "GenSigAutoGenSnd" SG_ 1788 NMH_Ladegeraet_Normal_Mode_2 1;
BA_ "GenSigAutoGenDsp" SG_ 1788 NMH_Ladegeraet_Normal_Mode_2 1;
BA_ "NWM-WakeupAllowed" SG_ 1788 NMH_Ladegeraet_Normal_Mode_2 0;
BA_ "GenSigEnvVarType" SG_ 1788 NMH_Ladegeraet_Car_WakeUp 0;
BA_ "NWM-WakeupAllowed" SG_ 1788 NMH_Ladegeraet_Car_WakeUp 0;
BA_ "GenSigEnvVarType" SG_ 1788 NMH_Ladegeraet_Per_WakeUp 0;
BA_ "GenSigEnvVarType" SG_ 1788 NMH_Ladegeraet_Fkt_WakeUp 0;
BA_ "GenSigEnvVarType" SG_ 1788 NMH_Ladegeraet_Klemme_15 0;
BA_ "NWM-WakeupAllowed" SG_ 1788 NMH_Ladegeraet_Klemme_15 0;
BA_ "GenSigEnvVarType" SG_ 1788 NMH_Ladegeraet_Diagnose 0;
BA_ "NWM-WakeupAllowed" SG_ 1788 NMH_Ladegeraet_Diagnose 0;
BA_ "GenSigEnvVarType" SG_ 1788 NMH_Ladegeraet_MindestAktivZeit 0;
BA_ "NWM-WakeupAllowed" SG_ 1788 NMH_Ladegeraet_MindestAktivZeit 0;
BA_ "GenSigAutoGenSnd" SG_ 1788 NMH_Ladegeraet_Signalfehler 1;
BA_ "GenSigAutoGenDsp" SG_ 1788 NMH_Ladegeraet_Signalfehler 1;
BA_ "NWM-WakeupAllowed" SG_ 1788 NMH_Ladegeraet_Signalfehler 0;
BA_ "GenSigEnvVarType" SG_ 1788 NMH_Ladegeraet_TimeOut_Fehler 0;
BA_ "NWM-WakeupAllowed" SG_ 1788 NMH_Ladegeraet_TimeOut_Fehler 0;
BA_ "GenSigEnvVarType" SG_ 1788 NMH_Ladegeraet_CAN_Diag_deaktiv 0;
BA_ "NWM-WakeupAllowed" SG_ 1788 NMH_Ladegeraet_CAN_Diag_deaktiv 0;
BA_ "GenSigEnvVarType" SG_ 1788 NMH_Ladegeraet_KompSchutz 0;
BA_ "NWM-WakeupAllowed" SG_ 1788 NMH_Ladegeraet_KompSchutz 0;
BA_ "GenSigEnvVarType" SG_ 1788 NMH_Ladegeraet_Mute_Mode 0;
BA_ "NWM-WakeupAllowed" SG_ 1788 NMH_Ladegeraet_Mute_Mode 0;
BA_ "GenSigEnvVarType" SG_ 1788 NMH_Ladegeraet_Transport_Mode 0;
BA_ "NWM-WakeupAllowed" SG_ 1788 NMH_Ladegeraet_Transport_Mode 0;
BA_ "GenSigEnvVarType" SG_ 1788 NMH_Ladegeraet_Abschaltstufe_000 0;
BA_ "NWM-WakeupAllowed" SG_ 1788 NMH_Ladegeraet_Abschaltstufe_000 0;
BA_ "GenSigEnvVarType" SG_ 1788 NMH_Ladegeraet_Eindraht_Fehler 0;
BA_ "NWM-WakeupAllowed" SG_ 1788 NMH_Ladegeraet_Eindraht_Fehler 0;
BA_ "GenSigAutoGenSnd" SG_ 1788 NMH_Ladegeraet_Lokalaktiv 1;
BA_ "GenSigAutoGenDsp" SG_ 1788 NMH_Ladegeraet_Lokalaktiv 1;
BA_ "NWM-WakeupAllowed" SG_ 1788 NMH_Ladegeraet_Lokalaktiv 0;
BA_ "GenSigEnvVarType" SG_ 1788 NMH_Ladegeraet_Subsystemaktiv 0;
BA_ "NWM-WakeupAllowed" SG_ 1788 NMH_Ladegeraet_Subsystemaktiv 0;
BA_ "GenSigAutoGenSnd" SG_ 1966 ISO_Ladegeraet_Resp_Data 1;
BA_ "GenSigAutoGenDsp" SG_ 1966 ISO_Ladegeraet_Resp_Data 1;
BA_ "NWM-WakeupAllowed" SG_ 1966 ISO_Ladegeraet_Resp_Data 0;
BA_ "GenSigAutoGenSnd" SG_ 1860 ISO_Ladegeraet_Req_Data 1;
BA_ "GenSigAutoGenDsp" SG_ 1860 ISO_Ladegeraet_Req_Data 1;
BA_ "NWM-WakeupAllowed" SG_ 1860 ISO_Ladegeraet_Req_Data 0;
BA_ "NWM-WakeupAllowed" SG_ 1483 PTC_Wassereinlasstemp 0;
BA_ "GenSigStartValue" SG_ 1483 PTC_Wassereinlasstemp 254;
BA_ "NWM-WakeupAllowed" SG_ 1483 PTC_Wasserauslasstemp 0;
BA_ "GenSigStartValue" SG_ 1483 PTC_Wasserauslasstemp 254;
BA_ "GenSigAutoGenSnd" SG_ 1483 PTC_HV_I_ist 1;
BA_ "GenSigAutoGenDsp" SG_ 1483 PTC_HV_I_ist 1;
BA_ "NWM-WakeupAllowed" SG_ 1483 PTC_HV_I_ist 0;
BA_ "GenSigStartValue" SG_ 1483 PTC_HV_I_ist 254;
BA_ "GenSigSendType" SG_ 1483 KL_T_Charge 3;
BA_ "GenSigAutoGenSnd" SG_ 1483 KL_T_Charge 1;
BA_ "GenSigAutoGenDsp" SG_ 1483 KL_T_Charge 1;
BA_ "NWM-WakeupAllowed" SG_ 1483 KL_T_Charge 0;
BA_ "GenSigAutoGenSnd" SG_ 1483 KBT_Defrost_aktiv 1;
BA_ "GenSigAutoGenDsp" SG_ 1483 KBT_Defrost_aktiv 1;
BA_ "NWM-WakeupAllowed" SG_ 1483 KBT_Defrost_aktiv 0;
BA_ "GenSigAutoGenSnd" SG_ 1483 KL_WunschStrom_HV 1;
BA_ "GenSigAutoGenDsp" SG_ 1483 KL_WunschStrom_HV 1;
BA_ "NWM-WakeupAllowed" SG_ 1483 KL_WunschStrom_HV 0;
BA_ "GenSigStartValue" SG_ 1483 KL_WunschStrom_HV 254;
BA_ "Fehlerwert" SG_ 1483 KL_WunschStrom_HV 255;
BA_ "GenSigAutoGenSnd" SG_ 1483 KL_BattKond_WaPu_DZMax 1;
BA_ "GenSigAutoGenDsp" SG_ 1483 KL_BattKond_WaPu_DZMax 1;
BA_ "NWM-WakeupAllowed" SG_ 1483 KL_BattKond_WaPu_DZMax 0;
BA_ "GenSigStartValue" SG_ 1483 KL_BattKond_WaPu_DZMax 62;
BA_ "Fehlerwert" SG_ 1483 KL_BattKond_WaPu_DZMax 63;
BA_ "GenSigAutoGenSnd" SG_ 1483 KL_Standklima_Status 1;
BA_ "GenSigAutoGenDsp" SG_ 1483 KL_Standklima_Status 1;
BA_ "NWM-WakeupAllowed" SG_ 1483 KL_Standklima_Status 0;
BA_ "GenSigEnvVarType" SG_ 899 CHA_Ziel_FahrPr_BMS 0;
BA_ "GenSigAutoGenSnd" SG_ 899 CHA_Ziel_FahrPr_BMS 1;
BA_ "GenSigAutoGenDsp" SG_ 899 CHA_Ziel_FahrPr_BMS 1;
BA_ "GenSigActiveRepetitions" SG_ 899 CHA_Ziel_FahrPr_BMS 5;
BA_ "NWM-WakeupAllowed" SG_ 899 CHA_Ziel_FahrPr_BMS 0;
BA_ "GenSigSendType" SG_ 1518 KL_T_STH 3;
BA_ "GenSigEnvVarType" SG_ 1518 Klima_08_PAG_alt 0;
BA_ "GenSigAutoGenSnd" SG_ 1518 Klima_08_PAG_alt 1;
BA_ "GenSigAutoGenDsp" SG_ 1518 Klima_08_PAG_alt 1;
BA_ "NWM-WakeupAllowed" SG_ 1518 Klima_08_PAG_alt 0;
BA_ "GenSigStartValue" SG_ 1518 Klima_08_PAG_alt 1;
BA_ "NWM-WakeupAllowed" SG_ 391 MO_Tankbereitschaft_Status 0;
BA_ "NWM-WakeupAllowed" SG_ 391 MO_Tankklappensteuerung 0;
BA_ "GenSigAutoGenSnd" SG_ 391 MO_HVEM_MaxLeistung 1;
BA_ "GenSigAutoGenDsp" SG_ 391 MO_HVEM_MaxLeistung 1;
BA_ "NWM-WakeupAllowed" SG_ 391 MO_HVEM_MaxLeistung 0;
BA_ "GenSigStartValue" SG_ 391 MO_HVEM_MaxLeistung 510;
BA_ "Fehlerwert" SG_ 391 MO_HVEM_MaxLeistung 511;
BA_ "NWM-WakeupAllowed" SG_ 391 EV_Rekuperationsstufe 0;
BA_ "NWM-WakeupAllowed" SG_ 391 MO_Waehlpos 0;
BA_ "Fehlerwert" SG_ 391 MO_Waehlpos 7;
BA_ "NWM-WakeupAllowed" SG_ 391 HV_Bordnetz_aktiv 0;
BA_ "GenSigSendType" SG_ 391 MO_HVEM_Eskalation 3;
BA_ "NWM-WakeupAllowed" SG_ 391 MO_HVEM_Eskalation 0;
BA_ "GenSigFuncType" SG_ 1662 LAD_02_CHK 4;
BA_ "NWM-WakeupAllowed" SG_ 1662 LAD_02_CHK 0;
BA_ "GenSigFuncType" SG_ 1662 LAD_02_BZ 1;
BA_ "NWM-WakeupAllowed" SG_ 1662 LAD_02_BZ 0;
BA_ "NWM-WakeupAllowed" SG_ 1662 LAD_Abregelung_Temperatur 0;
BA_ "NWM-WakeupAllowed" SG_ 1662 LAD_Abregelung_IU_Ein_Aus 0;
BA_ "NWM-WakeupAllowed" SG_ 1662 LAD_Abregelung_BuchseTemp 0;
BA_ "NWM-WakeupAllowed" SG_ 1662 LAD_MaxLadLeistung_HV 0;
BA_ "GenSigStartValue" SG_ 1662 LAD_MaxLadLeistung_HV 510;
BA_ "Fehlerwert" SG_ 1662 LAD_MaxLadLeistung_HV 511;
BA_ "NWM-WakeupAllowed" SG_ 1662 LAD_CP_Stromlimit 0;
BA_ "GenSigStartValue" SG_ 1662 LAD_CP_Stromlimit 126;
BA_ "Fehlerwert" SG_ 1662 LAD_CP_Stromlimit 127;
BA_ "NWM-WakeupAllowed" SG_ 1662 LAD_PRX_Stromlimit 0;
BA_ "GenSigStartValue" SG_ 1662 LAD_PRX_Stromlimit 6;
BA_ "Fehlerwert" SG_ 1662 LAD_PRX_Stromlimit 7;
BA_ "GenSigSendType" SG_ 1662 LAD_CP_Erkennung 3;
BA_ "NWM-WakeupAllowed" SG_ 1662 LAD_CP_Erkennung 0;
BA_ "NWM-WakeupAllowed" SG_ 1662 LAD_Stecker_Verriegelt 0;
BA_ "GenSigSendType" SG_ 1662 LAD_Stecker_Gesteckt 3;
BA_ "NWM-WakeupAllowed" SG_ 1662 LAD_Stecker_Gesteckt 0;
BA_ "NWM-WakeupAllowed" SG_ 1662 LAD_Kuehlbedarf 0;
BA_ "NWM-WakeupAllowed" SG_ 1662 LAD_Warnzustand 0;
BA_ "NWM-WakeupAllowed" SG_ 1662 LAD_Fehlerzustand 0;
BA_ "NWM-WakeupAllowed" SG_ 1662 LAD_Fehlerstatus 0;
BA_ "GenSigStartValue" SG_ 1662 LAD_Fehlerstatus 7;
BA_ "NWM-WakeupAllowed" SG_ 1662 LAD_Warnlampe_Anf 0;
BA_ "GenSigFuncType" SG_ 1380 LAD_01_CHK 4;
BA_ "NWM-WakeupAllowed" SG_ 1380 LAD_01_CHK 0;
BA_ "GenSigFuncType" SG_ 1380 LAD_01_BZ 1;
BA_ "NWM-WakeupAllowed" SG_ 1380 LAD_01_BZ 0;
BA_ "GenSigSendType" SG_ 1380 LAD_IstModus 5;
BA_ "NWM-WakeupAllowed" SG_ 1380 LAD_IstModus 0;
BA_ "GenSigStartValue" SG_ 1380 LAD_IstModus 7;
BA_ "NWM-WakeupAllowed" SG_ 1380 LAD_AC_Istspannung 0;
BA_ "GenSigStartValue" SG_ 1380 LAD_AC_Istspannung 510;
BA_ "Fehlerwert" SG_ 1380 LAD_AC_Istspannung 511;
BA_ "NWM-WakeupAllowed" SG_ 1380 LAD_IstSpannung_HV 0;
BA_ "GenSigStartValue" SG_ 1380 LAD_IstSpannung_HV 1022;
BA_ "Fehlerwert" SG_ 1380 LAD_IstSpannung_HV 1023;
BA_ "NWM-WakeupAllowed" SG_ 1380 LAD_IstStrom_HV 0;
BA_ "GenSigStartValue" SG_ 1380 LAD_IstStrom_HV 1022;
BA_ "Fehlerwert" SG_ 1380 LAD_IstStrom_HV 1023;
BA_ "GenSigSendType" SG_ 1380 LAD_Status_Spgfreiheit 4;
BA_ "NWM-WakeupAllowed" SG_ 1380 LAD_Status_Spgfreiheit 0;
BA_ "NWM-WakeupAllowed" SG_ 1380 LAD_Temperatur 0;
BA_ "GenSigStartValue" SG_ 1380 LAD_Temperatur 254;
BA_ "Fehlerwert" SG_ 1380 LAD_Temperatur 255;
BA_ "NWM-WakeupAllowed" SG_ 1380 LAD_Verlustleistung 0;
BA_ "GenSigStartValue" SG_ 1380 LAD_Verlustleistung 254;
BA_ "Fehlerwert" SG_ 1380 LAD_Verlustleistung 255;
BA_ "GenSigSendType" SG_ 1385 HVEM_Abschaltstatus 3;
BA_ "GenSigAutoGenSnd" SG_ 1385 HVEM_Abschaltstatus 1;
BA_ "GenSigAutoGenDsp" SG_ 1385 HVEM_Abschaltstatus 1;
BA_ "NWM-WakeupAllowed" SG_ 1385 HVEM_Abschaltstatus 0;
BA_ "GenSigStartValue" SG_ 1385 HVEM_Abschaltstatus 7;
BA_ "GenSigSendType" SG_ 1385 HVEM_NVLeistungEmpf 3;
BA_ "NWM-WakeupAllowed" SG_ 1385 HVEM_NVLeistungEmpf 0;
BA_ "GenSigSendType" SG_ 1385 HVEM_KlimaMaxHVStrom 3;
BA_ "NWM-WakeupAllowed" SG_ 1385 HVEM_KlimaMaxHVStrom 0;
BA_ "GenSigSendType" SG_ 1385 HVEM_LeistunsAnf 3;
BA_ "NWM-WakeupAllowed" SG_ 1385 HVEM_LeistunsAnf 0;
BA_ "Fehlerwert" SG_ 1385 HVEM_LeistunsAnf 3;
BA_ "GenSigSendType" SG_ 1385 HVEM_Nachlad_Status 3;
BA_ "NWM-WakeupAllowed" SG_ 1385 HVEM_Nachlad_Status 0;
BA_ "GenSigStartValue" SG_ 1385 HVEM_Nachlad_Status 3;
BA_ "GenSigSendType" SG_ 1385 HVEM_Anf_ReichweiteNV 3;
BA_ "NWM-WakeupAllowed" SG_ 1385 HVEM_Anf_ReichweiteNV 0;
BA_ "Fehlerwert" SG_ 1385 HVEM_Anf_ReichweiteNV 3;
BA_ "GenSigSendType" SG_ 1385 HVEM_HV_Anf 3;
BA_ "NWM-WakeupAllowed" SG_ 1385 HVEM_HV_Anf 0;
BA_ "GenSigSendType" SG_ 1385 HVEM_Text_1 3;
BA_ "NWM-WakeupAllowed" SG_ 1385 HVEM_Text_1 0;
BA_ "GenSigSendType" SG_ 1385 HVEM_Nachladen_Anf 3;
BA_ "NWM-WakeupAllowed" SG_ 1385 HVEM_Nachladen_Anf 0;
BA_ "GenSigSendType" SG_ 1385 HVEM_FreigabeKlimatisierung 3;
BA_ "NWM-WakeupAllowed" SG_ 1385 HVEM_FreigabeKlimatisierung 0;
BA_ "GenSigStartValue" SG_ 1385 HVEM_FreigabeKlimatisierung 2;
BA_ "Fehlerwert" SG_ 1385 HVEM_FreigabeKlimatisierung 3;
BA_ "GenSigFuncType" SG_ 1482 BMS_07_CRC 2;
BA_ "NWM-WakeupAllowed" SG_ 1482 BMS_07_CRC 0;
BA_ "GenSigFuncType" SG_ 1482 BMS_07_BZ 1;
BA_ "NWM-WakeupAllowed" SG_ 1482 BMS_07_BZ 0;
BA_ "NWM-WakeupAllowed" SG_ 1482 BMS_Energieinhalt 0;
BA_ "GenSigStartValue" SG_ 1482 BMS_Energieinhalt 2046;
BA_ "Fehlerwert" SG_ 1482 BMS_Energieinhalt 2047;
BA_ "NWM-WakeupAllowed" SG_ 1482 BMS_Ladevorgang_aktiv 0;
BA_ "NWM-WakeupAllowed" SG_ 1482 BMS_MaxEnergieinhalt 0;
BA_ "GenSigStartValue" SG_ 1482 BMS_MaxEnergieinhalt 2046;
BA_ "Fehlerwert" SG_ 1482 BMS_MaxEnergieinhalt 2047;
BA_ "NWM-WakeupAllowed" SG_ 1482 BMS_Ausgleichsladung_Anf 0;
BA_ "GenSigSendType" SG_ 1482 BMS_Gesamtst_Spgfreiheit 3;
BA_ "NWM-WakeupAllowed" SG_ 1482 BMS_Gesamtst_Spgfreiheit 0;
BA_ "GenSigAutoGenSnd" SG_ 1519 BMS_IstStrom 1;
BA_ "GenSigAutoGenDsp" SG_ 1519 BMS_IstStrom 1;
BA_ "NWM-WakeupAllowed" SG_ 1519 BMS_IstStrom 0;
BA_ "GenSigStartValue" SG_ 1519 BMS_IstStrom 4094;
BA_ "Fehlerwert" SG_ 1519 BMS_IstStrom 4095;
BA_ "GenSigAutoGenSnd" SG_ 1519 BMS_PTC_Stufe 1;
BA_ "GenSigAutoGenDsp" SG_ 1519 BMS_PTC_Stufe 1;
BA_ "NWM-WakeupAllowed" SG_ 1519 BMS_PTC_Stufe 0;
BA_ "GenSigStartValue" SG_ 1519 BMS_PTC_Stufe 14;
BA_ "Fehlerwert" SG_ 1519 BMS_PTC_Stufe 15;
BA_ "GenSigAutoGenSnd" SG_ 1519 BMS_PTC_IstStrom 1;
BA_ "GenSigAutoGenDsp" SG_ 1519 BMS_PTC_IstStrom 1;
BA_ "NWM-WakeupAllowed" SG_ 1519 BMS_PTC_IstStrom 0;
BA_ "GenSigStartValue" SG_ 1519 BMS_PTC_IstStrom 254;
BA_ "Fehlerwert" SG_ 1519 BMS_PTC_IstStrom 255;
BA_ "NWM-WakeupAllowed" SG_ 1519 BMS_Status_Kuehlung 0;
BA_ "GenSigStartValue" SG_ 1519 BMS_Status_Kuehlung 14;
BA_ "Fehlerwert" SG_ 1519 BMS_Status_Kuehlung 15;
BA_ "NWM-WakeupAllowed" SG_ 1519 BMS_Temp_Zelle_Min 0;
BA_ "GenSigStartValue" SG_ 1519 BMS_Temp_Zelle_Min 254;
BA_ "Fehlerwert" SG_ 1519 BMS_Temp_Zelle_Min 255;
BA_ "NWM-WakeupAllowed" SG_ 1519 BMS_Temp_Zelle_Max 0;
BA_ "GenSigStartValue" SG_ 1519 BMS_Temp_Zelle_Max 254;
BA_ "Fehlerwert" SG_ 1519 BMS_Temp_Zelle_Max 255;
BA_ "NWM-WakeupAllowed" SG_ 1519 BMS_Pumpendrehzahl 0;
BA_ "GenSigStartValue" SG_ 1519 BMS_Pumpendrehzahl 254;
BA_ "Fehlerwert" SG_ 1519 BMS_Pumpendrehzahl 255;
BA_ "NWM-WakeupAllowed" SG_ 1519 BMS_Status_3_2_Ventil1 0;
BA_ "GenSigStartValue" SG_ 1519 BMS_Status_3_2_Ventil1 6;
BA_ "Fehlerwert" SG_ 1519 BMS_Status_3_2_Ventil1 7;
BA_ "NWM-WakeupAllowed" SG_ 1519 BMS_Status_3_2_Ventil2 0;
BA_ "GenSigStartValue" SG_ 1519 BMS_Status_3_2_Ventil2 6;
BA_ "Fehlerwert" SG_ 1519 BMS_Status_3_2_Ventil2 7;
BA_ "NWM-WakeupAllowed" SG_ 1438 BMS_Temperierung_Anf 0;
BA_ "GenSigStartValue" SG_ 1438 BMS_Temperierung_Anf 3;
BA_ "NWM-WakeupAllowed" SG_ 1438 BMS_Soll_PWM_Pumpe 0;
BA_ "GenSigStartValue" SG_ 1438 BMS_Soll_PWM_Pumpe 15;
BA_ "NWM-WakeupAllowed" SG_ 1438 BMS_Temperatur 0;
BA_ "GenSigStartValue" SG_ 1438 BMS_Temperatur 254;
BA_ "Fehlerwert" SG_ 1438 BMS_Temperatur 255;
BA_ "NWM-WakeupAllowed" SG_ 1438 BMS_IstVorlaufTemperatur 0;
BA_ "GenSigStartValue" SG_ 1438 BMS_IstVorlaufTemperatur 254;
BA_ "Fehlerwert" SG_ 1438 BMS_IstVorlaufTemperatur 255;
BA_ "NWM-WakeupAllowed" SG_ 1438 BMS_SollVolumenstrom 0;
BA_ "GenSigStartValue" SG_ 1438 BMS_SollVolumenstrom 62;
BA_ "Fehlerwert" SG_ 1438 BMS_SollVolumenstrom 63;
BA_ "NWM-WakeupAllowed" SG_ 1438 BMS_SollVorlauftemperatur 0;
BA_ "GenSigStartValue" SG_ 1438 BMS_SollVorlauftemperatur 254;
BA_ "Fehlerwert" SG_ 1438 BMS_SollVorlauftemperatur 255;
BA_ "NWM-WakeupAllowed" SG_ 1438 BMS_IstRuecklaufTemperatur_02 0;
BA_ "GenSigStartValue" SG_ 1438 BMS_IstRuecklaufTemperatur_02 254;
BA_ "Fehlerwert" SG_ 1438 BMS_IstRuecklaufTemperatur_02 255;
BA_ "NWM-WakeupAllowed" SG_ 1438 BMS_SollVorlaufTemp_Epsilon 0;
BA_ "GenSigStartValue" SG_ 1438 BMS_SollVorlaufTemp_Epsilon 15;
BA_ "GenSigSendType" SG_ 1428 HVLM_HV_Anf 3;
BA_ "NWM-WakeupAllowed" SG_ 1428 HVLM_HV_Anf 0;
BA_ "NWM-WakeupAllowed" SG_ 1428 HVLM_Stecker_Status 0;
BA_ "NWM-WakeupAllowed" SG_ 1428 HVLM_Restladezeit_HV_Bat_02 0;
BA_ "GenSigStartValue" SG_ 1428 HVLM_Restladezeit_HV_Bat_02 510;
BA_ "Fehlerwert" SG_ 1428 HVLM_Restladezeit_HV_Bat_02 511;
BA_ "NWM-WakeupAllowed" SG_ 1428 HVLM_Lademodus_HV_Bat 0;
BA_ "NWM-WakeupAllowed" SG_ 1428 HVLM_Bat_laden_aktiv 0;
BA_ "NWM-WakeupAllowed" SG_ 1428 HVLM_Ladeart 0;
BA_ "NWM-WakeupAllowed" SG_ 1428 HVLM_VK_Anf 0;
BA_ "GenSigSendType" SG_ 1428 HVLM_Ladesystemhinweise 3;
BA_ "NWM-WakeupAllowed" SG_ 1428 HVLM_Ladesystemhinweise 0;
BA_ "NWM-WakeupAllowed" SG_ 1428 HVLM_Langzeit_Laden 0;
BA_ "Fehlerwert" SG_ 1428 HVLM_Langzeit_Laden 3;
BA_ "GenSigSendType" SG_ 1428 HVLM_Klima_Temp 3;
BA_ "NWM-WakeupAllowed" SG_ 1428 HVLM_Klima_Temp 0;
BA_ "GenSigStartValue" SG_ 1428 HVLM_Klima_Temp 30;
BA_ "Fehlerwert" SG_ 1428 HVLM_Klima_Temp 31;
BA_ "NWM-WakeupAllowed" SG_ 1428 HVLM_VK_Modus 0;
BA_ "Fehlerwert" SG_ 1428 HVLM_VK_Modus 3;
BA_ "NWM-WakeupAllowed" SG_ 1428 HVLM_HSH_Anf 0;
BA_ "NWM-WakeupAllowed" SG_ 305 MO_ePowermeter 0;
BA_ "NWM-WakeupAllowed" SG_ 305 MO_W_Reku_normiert_ueberlauf 0;
BA_ "NWM-WakeupAllowed" SG_ 305 Ladezustand 0;
BA_ "Fehlerwert" SG_ 305 Ladezustand 255;
BA_ "NWM-WakeupAllowed" SG_ 305 Enrgfluss_State 0;
BA_ "Fehlerwert" SG_ 305 Enrgfluss_State 255;
BA_ "NWM-WakeupAllowed" SG_ 305 MO_W_Reku_normiert 0;
BA_ "NWM-WakeupAllowed" SG_ 305 MO_Powermeter 0;
BA_ "GenSigStartValue" SG_ 305 MO_Powermeter 4093;
BA_ "GenSigFuncType" SG_ 914 ESP_07_BZ 1;
BA_ "NWM-WakeupAllowed" SG_ 914 ESP_07_BZ 0;
BA_ "GenSigFuncType" SG_ 914 ESP_07_CHK 3;
BA_ "NWM-WakeupAllowed" SG_ 914 ESP_07_CHK 0;
BA_ "NWM-WakeupAllowed" SG_ 914 ESP_OBD_Status 0;
BA_ "NWM-WakeupAllowed" SG_ 914 OBD_Fehler_Radsensor_VR 0;
BA_ "NWM-WakeupAllowed" SG_ 914 OBD_Fehler_Radsensor_VL 0;
BA_ "NWM-WakeupAllowed" SG_ 914 OBD_Fehler_Radsensor_HR 0;
BA_ "NWM-WakeupAllowed" SG_ 914 OBD_Fehler_Radsensor_HL 0;
BA_ "GenSigSendType" SG_ 906 KL_Sportmodus 3;
BA_ "GenSigSendType" SG_ 906 KL_T_PSM_off 3;
BA_ "GenSigStartValue" SG_ 906 F_Klima_08_PAG_Fwk 1;
BA_ "GenSigStartValue" SG_ 906 F_Klima_03_Ant 1;
BA_ "GenSigStartValue" SG_ 906 F_ESP_11_Ant 1;
BA_ "GenSigStartValue" SG_ 1731 NMH_ESP_Start_1 1;
BA_ "GenSigStartValue" SG_ 1731 NMH_ESP_NM_aktiv_v_groesser_Null 1;
BA_ "NWM-WakeupAllowed" SG_ 946 BEM_NV_NachladAnf 0;
BA_ "GenSigStartValue" SG_ 946 BEM_NV_NachladAnf 2;
BA_ "Fehlerwert" SG_ 946 BEM_NV_NachladAnf 3;
BA_ "NWM-WakeupAllowed" SG_ 946 BEM_Freigabe_HV_Ladung 0;
BA_ "GenSigStartValue" SG_ 946 BEM_HYB_DC_uMinLV 254;
BA_ "GenSigStartValue" SG_ 946 BEM_HYB_DC_uSollLV 37;
BA_ "NWM-WakeupAllowed" SG_ 1628 BMS_IstSpannung_HV 0;
BA_ "GenSigStartValue" SG_ 1628 BMS_IstSpannung_HV 254;
BA_ "Fehlerwert" SG_ 1628 BMS_IstSpannung_HV 255;
BA_ "NWM-WakeupAllowed" SG_ 1628 BMS_Temperatur_Ansaugluft 0;
BA_ "GenSigStartValue" SG_ 1628 BMS_Temperatur_Ansaugluft 254;
BA_ "Fehlerwert" SG_ 1628 BMS_Temperatur_Ansaugluft 255;
BA_ "NWM-WakeupAllowed" SG_ 1628 BMS_Temperatur 0;
BA_ "GenSigStartValue" SG_ 1628 BMS_Temperatur 254;
BA_ "Fehlerwert" SG_ 1628 BMS_Temperatur 255;
BA_ "NWM-WakeupAllowed" SG_ 1628 BMS_HYB_Spuelbetrieb_Status 0;
BA_ "NWM-WakeupAllowed" SG_ 1628 BMS_HYB_Temp_vor_Verd 0;
BA_ "GenSigStartValue" SG_ 1628 BMS_HYB_Temp_vor_Verd 254;
BA_ "Fehlerwert" SG_ 1628 BMS_HYB_Temp_vor_Verd 255;
BA_ "NWM-WakeupAllowed" SG_ 1628 BMS_HYB_Temp_nach_Verd 0;
BA_ "GenSigStartValue" SG_ 1628 BMS_HYB_Temp_nach_Verd 254;
BA_ "Fehlerwert" SG_ 1628 BMS_HYB_Temp_nach_Verd 255;
BA_ "NWM-WakeupAllowed" SG_ 1628 BMS_HYB_Kuehlung_Anf 0;
BA_ "NWM-WakeupAllowed" SG_ 1628 BMS_HYB_ASV_vorne_Status 0;
BA_ "NWM-WakeupAllowed" SG_ 1628 BMS_HYB_ASV_hinten_Status 0;
BA_ "GenSigStartValue" SG_ 1628 BMS_HYB_BattFanSpd 14;
BA_ "Fehlerwert" SG_ 1628 BMS_HYB_BattFanSpd 15;
BA_ "NWM-WakeupAllowed" SG_ 945 DC_TiefsetzBereit 0;
BA_ "GenSigStartValue" SG_ 945 DC_HYB_iAktLV 1022;
BA_ "Fehlerwert" SG_ 945 DC_HYB_iAktLV 1023;
BA_ "GenSigStartValue" SG_ 945 DC_HYB_iAktReserveLV 1022;
BA_ "Fehlerwert" SG_ 945 DC_HYB_iAktReserveLV 1023;
BA_ "GenSigStartValue" SG_ 945 DC_HYB_uAktLV 254;
BA_ "Fehlerwert" SG_ 945 DC_HYB_uAktLV 255;
BA_ "NWM-WakeupAllowed" SG_ 945 DC_Verbrauch_Ueberlauf 0;
BA_ "NWM-WakeupAllowed" SG_ 945 DC_Verbrauch 0;
BA_ "GenSigStartValue" SG_ 945 DC_HYB_Auslastungsgrad 254;
BA_ "Fehlerwert" SG_ 945 DC_HYB_Auslastungsgrad 255;
BA_ "GenSigMissingSourceValue" SG_ 256 ESP_v_Signal 65535;
BA_ "GenSigStartValue" SG_ 256 ESP_v_Signal 65534;
BA_ "Fehlerwert" SG_ 256 ESP_v_Signal 65535;
BA_ "Bemerkung" SG_ 256 ESP_v_Signal "Signal ist eine aus den Radgeschwindigkeiten gebildete Geschwindigkeit";
BA_ "GenSigFuncType" SG_ 256 ESP_01_CHK 4;
BA_ "GenSigFuncType" SG_ 256 ESP_01_BZ 1;
BA_ "GenSigStartValue" SG_ 256 ASR_Moment_langsam 1022;
BA_ "Fehlerwert" SG_ 256 ASR_Moment_langsam 1023;
BA_ "GenSigStartValue" SG_ 256 ASR_MSR_Moment_schnell 1022;
BA_ "Fehlerwert" SG_ 256 ASR_MSR_Moment_schnell 1023;
BA_ "GenSigStartValue" SG_ 256 OBD_QBit_Schlechtweg 1;
BA_ "GenSigStartValue" SG_ 256 ESP_QBit_v_Signal 1;
BA_ "GenSigFuncType" SG_ 257 ESP_02_CHK 4;
BA_ "GenSigFuncType" SG_ 257 ESP_02_BZ 1;
BA_ "GenSigStartValue" SG_ 257 ESP_QBit_Gierrate 1;
BA_ "GenSigStartValue" SG_ 257 ESP_QBit_Laengsbeschl 1;
BA_ "GenSigStartValue" SG_ 257 ESP_QBit_Querb 1;
BA_ "GenSigStartValue" SG_ 257 ESP_Querbeschleunigung 127;
BA_ "Fehlerwert" SG_ 257 ESP_Querbeschleunigung 255;
BA_ "GenSigStartValue" SG_ 257 ESP_Laengsbeschl 512;
BA_ "Fehlerwert" SG_ 257 ESP_Laengsbeschl 1023;
BA_ "GenSigStartValue" SG_ 257 ESP_Verteil_Wankmom 30;
BA_ "Fehlerwert" SG_ 257 ESP_Verteil_Wankmom 31;
BA_ "GenSigStartValue" SG_ 257 ESP_QBit_Anf_Vert_Wank 1;
BA_ "Fehlerwert" SG_ 257 ESP_Gierrate 1023;
BA_ "GenSigSendType" SG_ 1795 ISO_Functionaler_Req_Abgas 7;
BA_ "GenSigFuncType" SG_ 259 ESP_03_CHK 4;
BA_ "GenSigFuncType" SG_ 259 ESP_03_BZ 1;
BA_ "GenSigStartValue" SG_ 259 ESP_VL_Radgeschw 4094;
BA_ "Fehlerwert" SG_ 259 ESP_VL_Radgeschw 4095;
BA_ "GenSigStartValue" SG_ 259 ESP_VR_Radgeschw 4094;
BA_ "Fehlerwert" SG_ 259 ESP_VR_Radgeschw 4095;
BA_ "GenSigStartValue" SG_ 259 ESP_HL_Radgeschw 4094;
BA_ "Fehlerwert" SG_ 259 ESP_HL_Radgeschw 4095;
BA_ "GenSigStartValue" SG_ 259 ESP_HR_Radgeschw 4094;
BA_ "Fehlerwert" SG_ 259 ESP_HR_Radgeschw 4095;
BA_ "NWM-WakeupAllowed" SG_ 776 ESP_HDC_FktLampe 0;
BA_ "NWM-WakeupAllowed" SG_ 776 ESP_ASR_Lampe 0;
BA_ "GenSigStartValue" SG_ 776 ESP_Lampe 1;
BA_ "GenSigStartValue" SG_ 776 ABS_Lampe 1;
BA_ "GenSigStartValue" SG_ 776 BK_Lampe 1;
BA_ "GenSigStartValue" SG_ 776 ESP_m_Raddrehz 32766;
BA_ "Fehlerwert" SG_ 776 ESP_m_Raddrehz 32767;
BA_ "GenSigStartValue" SG_ 776 ESP_QBit_Wegimp_VA 1;
BA_ "GenSigStartValue" SG_ 776 ESP_HDC_Regelgeschw 126;
BA_ "Fehlerwert" SG_ 776 ESP_HDC_Regelgeschw 127;
BA_REL_ "GenSigTimeoutTime" BU_SG_REL_ BMS_Hybrid SG_ 1446 OBC_KomponentenFehler_01 5000;
BA_REL_ "GenSigTimeoutTime" BU_SG_REL_ BMS_Hybrid SG_ 1446 OBC_KomponentenFehler_02 5000;
BA_REL_ "GenSigTimeoutTime" BU_SG_REL_ BMS_Hybrid SG_ 1446 OBC_KomponentenFehler_03 5000;
BA_REL_ "GenSigTimeoutTime" BU_SG_REL_ BMS_Hybrid SG_ 1446 OBC_KomponentenFehler_04 5000;
BA_REL_ "GenSigTimeoutTime" BU_SG_REL_ BMS_Hybrid SG_ 1446 OBC_KomponentenFehler_05 5000;
BA_REL_ "GenSigTimeoutTime" BU_SG_REL_ BMS_Hybrid SG_ 1446 OBC_KomponentenFehler_06 5000;
BA_REL_ "GenSigTimeoutTime" BU_SG_REL_ BMS_Hybrid SG_ 1446 OBC_KomponentenFehler_07 5000;
BA_REL_ "GenSigTimeoutTime" BU_SG_REL_ BMS_Hybrid SG_ 1446 OBC_KomponentenFehler_08 5000;
BA_REL_ "GenSigTimeoutTime" BU_SG_REL_ BMS_Hybrid SG_ 1446 OBC_KomponentenFehler_09 5000;
BA_REL_ "GenSigTimeoutTime" BU_SG_REL_ BMS_Hybrid SG_ 1446 OBC_KomponentenFehler_10 5000;
BA_REL_ "GenSigTimeoutTime" BU_SG_REL_ BMS_Hybrid SG_ 1446 OBC_KomponentenFehler_11 5000;
BA_REL_ "GenSigTimeoutTime" BU_SG_REL_ BMS_Hybrid SG_ 1446 OBC_KomponentenFehler_12 5000;
BA_REL_ "GenSigTimeoutTime" BU_SG_REL_ BMS_Hybrid SG_ 1446 OBC_KomponentenFehler_13 5000;
BA_REL_ "GenSigTimeoutTime" BU_SG_REL_ BMS_Hybrid SG_ 1446 OBC_KomponentenFehler_14 5000;
BA_REL_ "GenSigTimeoutTime" BU_SG_REL_ BMS_Hybrid SG_ 1446 OBC_KomponentenFehler_15 5000;
BA_REL_ "GenSigTimeoutTime" BU_SG_REL_ BMS_Hybrid SG_ 1446 OBC_KomponentenFehler_16 5000;
BA_REL_ "GenSigTimeoutTime" BU_SG_REL_ BMS_Hybrid SG_ 1446 OBC_KomponentenFehler_17 5000;
BA_REL_ "GenSigTimeoutTime" BU_SG_REL_ BMS_Hybrid SG_ 1446 OBC_KomponentenFehler_18 5000;
BA_REL_ "GenSigTimeoutTime" BU_SG_REL_ BMS_Hybrid SG_ 1446 OBC_KomponentenFehler_19 5000;
BA_REL_ "GenSigTimeoutTime" BU_SG_REL_ BMS_Hybrid SG_ 1446 OBC_KomponentenFehler_20 5000;
BA_REL_ "GenSigTimeoutTime" BU_SG_REL_ BMS_Hybrid SG_ 1446 OBC_KomponentenFehler_21 5000;
BA_REL_ "GenSigTimeoutTime" BU_SG_REL_ BMS_Hybrid SG_ 1446 OBC_KomponentenFehler_22 5000;
BA_REL_ "GenSigTimeoutTime" BU_SG_REL_ BMS_Hybrid SG_ 1446 OBC_KomponentenFehler_23 5000;
BA_REL_ "GenSigTimeoutTime" BU_SG_REL_ BMS_Hybrid SG_ 1446 OBC_KomponentenFehler_24 5000;
BA_REL_ "GenSigTimeoutTime" BU_SG_REL_ BMS_Hybrid SG_ 1446 OBC_KomponentenFehler_25 5000;
BA_REL_ "GenSigTimeoutTime" BU_SG_REL_ BMS_Hybrid SG_ 1446 OBC_KomponentenFehler_26 5000;
BA_REL_ "GenSigTimeoutTime" BU_SG_REL_ BMS_Hybrid SG_ 1446 OBC_KomponentenFehler_27 5000;
BA_REL_ "GenSigTimeoutTime" BU_SG_REL_ BMS_Hybrid SG_ 1446 OBC_KomponentenFehler_28 5000;
BA_REL_ "GenSigTimeoutTime" BU_SG_REL_ BMS_Hybrid SG_ 1446 OBC_KomponentenFehler_29 5000;
BA_REL_ "GenSigTimeoutTime" BU_SG_REL_ BMS_Hybrid SG_ 1446 OBC_KomponentenFehler_30 5000;
BA_REL_ "GenSigTimeoutTime" BU_SG_REL_ BMS_Hybrid SG_ 1446 OBC_KomponentenFehler_31 5000;
BA_REL_ "GenSigTimeoutTime" BU_SG_REL_ BMS_Hybrid SG_ 1446 OBC_KomponentenFehler_32 5000;
BA_REL_ "GenSigTimeoutTime" BU_SG_REL_ BMS_Hybrid SG_ 1445 OBC_CVN_VLD 5000;
BA_REL_ "GenSigTimeoutTime" BU_SG_REL_ BMS_Hybrid SG_ 1445 OBC_CALID_Index_01 5000;
BA_REL_ "GenSigTimeoutTime" BU_SG_REL_ BMS_Hybrid SG_ 1445 OBC_CALID_Index_05 5000;
BA_REL_ "GenSigTimeoutTime" BU_SG_REL_ BMS_Hybrid SG_ 1445 OBC_CALID_Index_09 5000;
BA_REL_ "GenSigTimeoutTime" BU_SG_REL_ BMS_Hybrid SG_ 1445 OBC_CALID_Index_13 5000;
BA_REL_ "GenSigTimeoutTime" BU_SG_REL_ BMS_Hybrid SG_ 1445 OBC_CALID_Index_02 5000;
BA_REL_ "GenSigTimeoutTime" BU_SG_REL_ BMS_Hybrid SG_ 1445 OBC_CALID_Index_06 5000;
BA_REL_ "GenSigTimeoutTime" BU_SG_REL_ BMS_Hybrid SG_ 1445 OBC_CALID_Index_10 5000;
BA_REL_ "GenSigTimeoutTime" BU_SG_REL_ BMS_Hybrid SG_ 1445 OBC_CALID_Index_14 5000;
BA_REL_ "GenSigTimeoutTime" BU_SG_REL_ BMS_Hybrid SG_ 1445 OBC_CALID_Index_03 5000;
BA_REL_ "GenSigTimeoutTime" BU_SG_REL_ BMS_Hybrid SG_ 1445 OBC_CALID_Index_07 5000;
BA_REL_ "GenSigTimeoutTime" BU_SG_REL_ BMS_Hybrid SG_ 1445 OBC_CALID_Index_11 5000;
BA_REL_ "GenSigTimeoutTime" BU_SG_REL_ BMS_Hybrid SG_ 1445 OBC_CALID_Index_15 5000;
BA_REL_ "GenSigTimeoutTime" BU_SG_REL_ BMS_Hybrid SG_ 1445 OBC_CALID_Index_04 5000;
BA_REL_ "GenSigTimeoutTime" BU_SG_REL_ BMS_Hybrid SG_ 1445 OBC_CALID_Index_08 5000;
BA_REL_ "GenSigTimeoutTime" BU_SG_REL_ BMS_Hybrid SG_ 1445 OBC_CALID_Index_12 5000;
BA_REL_ "GenSigTimeoutTime" BU_SG_REL_ BMS_Hybrid SG_ 1445 OBC_CALID_Index_16 5000;
BA_REL_ "GenSigTimeoutTime" BU_SG_REL_ BMS_Hybrid SG_ 1445 OBC_CVN_Byte_1 5000;
BA_REL_ "GenSigTimeoutTime" BU_SG_REL_ BMS_Hybrid SG_ 1445 OBC_CVN_Byte_2 5000;
BA_REL_ "GenSigTimeoutTime" BU_SG_REL_ BMS_Hybrid SG_ 1445 OBC_CVN_Byte_3 5000;
BA_REL_ "GenSigTimeoutTime" BU_SG_REL_ BMS_Hybrid SG_ 1445 OBC_CALID_CVN_MUX 5000;
BA_REL_ "GenSigTimeoutTime" BU_SG_REL_ BMS_Hybrid SG_ 1445 OBC_CVN_Byte_4 5000;
BA_REL_ "GenSigTimeoutTime" BU_SG_REL_ Tool SG_ 2617239041 CCP_LE_DTO_01_Data 500;
BA_REL_ "GenSigTimeoutTime" BU_SG_REL_ GW_Routing_Derivate SG_ 1527 RW_Sekundaer_Reichweite 5000;
BA_REL_ "GenSigTimeoutTime" BU_SG_REL_ GW_Routing_Derivate SG_ 1527 RW_Sek_Reichweitenv_Einheit 5000;
BA_REL_ "GenSigTimeoutTime" BU_SG_REL_ GW_Routing_Derivate SG_ 1527 RW_Sek_Reichweitenverbrauch 5000;
BA_REL_ "GenSigTimeoutTime" BU_SG_REL_ GW_Routing_Derivate SG_ 1525 RW_RWDS_Lastprofil 5000;
BA_REL_ "GenSigTimeoutTime" BU_SG_REL_ GW_Routing_Derivate SG_ 1525 RW_Gesamt_Reichweite 5000;
BA_REL_ "GenSigTimeoutTime" BU_SG_REL_ GW_Routing_Derivate SG_ 1525 RW_Prim_Reichweitenverbrauch 5000;
BA_REL_ "GenSigTimeoutTime" BU_SG_REL_ GW_Routing_Derivate SG_ 1525 RW_Prim_Reichweitenv_Einheit 5000;
BA_REL_ "GenSigTimeoutTime" BU_SG_REL_ GW_Routing_Derivate SG_ 1525 RW_Primaer_Reichweite 5000;
BA_REL_ "GenSigTimeoutTime" BU_SG_REL_ GW_Routing_Derivate SG_ 687 BMS_Rekuperation 500;
BA_REL_ "GenSigTimeoutTime" BU_SG_REL_ GW_Routing_Derivate SG_ 687 BMS_Rekuperation_Ueberlauf 500;
BA_REL_ "GenSigTimeoutTime" BU_SG_REL_ GW_Routing_Derivate SG_ 687 BMS_Verbrauch 500;
BA_REL_ "GenSigTimeoutTime" BU_SG_REL_ GW_Routing_Derivate SG_ 687 BMS_Verbrauch_Ueberlauf 500;
BA_REL_ "GenSigTimeoutTime" BU_SG_REL_ BMS_Hybrid SG_ 1532 KL_Autobetrieb_HL 5000;
BA_REL_ "GenSigTimeoutTime" BU_SG_REL_ BMS_Hybrid SG_ 1532 KL_Autobetrieb_HR 5000;
BA_REL_ "GenSigTimeoutTime" BU_SG_REL_ BMS_Hybrid SG_ 1532 KL_Autobetrieb_VL 5000;
BA_REL_ "GenSigTimeoutTime" BU_SG_REL_ BMS_Hybrid SG_ 1532 KL_Autobetrieb_VR 5000;
BA_REL_ "GenSigTimeoutTime" BU_SG_REL_ BMS_Hybrid SG_ 1532 KL_Zieltemperatur_HL 5000;
BA_REL_ "GenSigTimeoutTime" BU_SG_REL_ BMS_Hybrid SG_ 1532 KL_Zieltemperatur_HR 5000;
BA_REL_ "GenSigTimeoutTime" BU_SG_REL_ BMS_Hybrid SG_ 1532 KL_Zieltemperatur_VL 5000;
BA_REL_ "GenSigTimeoutTime" BU_SG_REL_ BMS_Hybrid SG_ 1532 KL_Zieltemperatur_VR 5000;
BA_REL_ "GenSigTimeoutTime" BU_SG_REL_ Motor_MED17_Hybrid SG_ 1788 NMH_Ladegeraet_Start_1 2000;
BA_REL_ "GenSigTimeoutTime" BU_SG_REL_ GW_Applikation_Derivate SG_ 1788 NMH_Ladegeraet_Start_1 2000;
BA_REL_ "GenSigTimeoutTime" BU_SG_REL_ Getriebe_Derivate SG_ 1788 NMH_Ladegeraet_Start_1 2000;
BA_REL_ "GenSigTimeoutTime" BU_SG_REL_ LEH_Hybrid SG_ 1788 NMH_Ladegeraet_Start_1 2000;
BA_REL_ "GenSigTimeoutTime" BU_SG_REL_ BMS_Hybrid SG_ 1788 NMH_Ladegeraet_Start_1 2000;
BA_REL_ "GenSigTimeoutTime" BU_SG_REL_ Ladegeraet_PAG_PF SG_ 1860 ISO_Ladegeraet_Req_Data 500;
BA_REL_ "GenSigTimeoutTime" BU_SG_REL_ BMS_Hybrid SG_ 1483 PTC_Wassereinlasstemp 5000;
BA_REL_ "GenSigTimeoutTime" BU_SG_REL_ BMS_Hybrid SG_ 1483 PTC_Wasserauslasstemp 5000;
BA_REL_ "GenSigTimeoutTime" BU_SG_REL_ BMS_Hybrid SG_ 1483 PTC_HV_I_ist 5000;
BA_REL_ "GenSigTimeoutTime" BU_SG_REL_ Ladegeraet_PAG_PF SG_ 1483 PTC_HV_I_ist 5000;
BA_REL_ "GenSigTimeoutTime" BU_SG_REL_ BMS_Hybrid SG_ 1483 KBT_Defrost_aktiv 5000;
BA_REL_ "GenSigTimeoutTime" BU_SG_REL_ BMS_Hybrid SG_ 1483 KL_BattKond_WaPu_DZMax 5000;
BA_REL_ "GenSigTimeoutTime" BU_SG_REL_ Ladegeraet_PAG_PF SG_ 1483 KL_Standklima_Status 5000;
BA_REL_ "GenSigTimeoutTime" BU_SG_REL_ Ladegeraet_PAG_PF SG_ 1518 KL_T_STH 5000;
BA_REL_ "GenSigTimeoutTime" BU_SG_REL_ Ladegeraet_PAG_PF SG_ 1518 Klima_08_PAG_alt 5000;
BA_REL_ "GenSigTimeoutTime" BU_SG_REL_ GW_Applikation_Derivate SG_ 391 MO_HVEM_MaxLeistung 500;
BA_REL_ "GenSigTimeoutTime" BU_SG_REL_ Ladegeraet_PAG_PF SG_ 391 HV_Bordnetz_aktiv 1000;
BA_REL_ "GenSigTimeoutTime" BU_SG_REL_ GW_Applikation_Derivate SG_ 391 HV_Bordnetz_aktiv 500;
BA_REL_ "GenSigTimeoutTime" BU_SG_REL_ GW_Applikation_Derivate SG_ 391 MO_HVEM_Eskalation 500;
BA_REL_ "GenSigTimeoutTime" BU_SG_REL_ GW_Routing_Derivate SG_ 1662 LAD_02_CHK 5000;
BA_REL_ "GenSigTimeoutTime" BU_SG_REL_ GW_Routing_Derivate SG_ 1662 LAD_02_BZ 5000;
BA_REL_ "GenSigTimeoutTime" BU_SG_REL_ GW_Routing_Derivate SG_ 1662 LAD_Abregelung_Temperatur 5000;
BA_REL_ "GenSigTimeoutTime" BU_SG_REL_ GW_Routing_Derivate SG_ 1662 LAD_Abregelung_IU_Ein_Aus 5000;
BA_REL_ "GenSigTimeoutTime" BU_SG_REL_ GW_Routing_Derivate SG_ 1662 LAD_Abregelung_BuchseTemp 5000;
BA_REL_ "GenSigTimeoutTime" BU_SG_REL_ GW_Routing_Derivate SG_ 1662 LAD_MaxLadLeistung_HV 5000;
BA_REL_ "GenSigTimeoutTime" BU_SG_REL_ GW_Applikation_Derivate SG_ 1662 LAD_MaxLadLeistung_HV 5000;
BA_REL_ "GenSigTimeoutTime" BU_SG_REL_ GW_Routing_Derivate SG_ 1662 LAD_CP_Stromlimit 5000;
BA_REL_ "GenSigTimeoutTime" BU_SG_REL_ GW_Routing_Derivate SG_ 1662 LAD_PRX_Stromlimit 5000;
BA_REL_ "GenSigTimeoutTime" BU_SG_REL_ GW_Routing_Derivate SG_ 1662 LAD_CP_Erkennung 5000;
BA_REL_ "GenSigTimeoutTime" BU_SG_REL_ GW_Routing_Derivate SG_ 1662 LAD_Stecker_Verriegelt 5000;
BA_REL_ "GenSigTimeoutTime" BU_SG_REL_ GW_Routing_Derivate SG_ 1662 LAD_Stecker_Gesteckt 5000;
BA_REL_ "GenSigTimeoutTime" BU_SG_REL_ GW_Routing_Derivate SG_ 1662 LAD_Kuehlbedarf 5000;
BA_REL_ "GenSigTimeoutTime" BU_SG_REL_ GW_Routing_Derivate SG_ 1662 LAD_Warnzustand 5000;
BA_REL_ "GenSigTimeoutTime" BU_SG_REL_ GW_Routing_Derivate SG_ 1662 LAD_Fehlerzustand 5000;
BA_REL_ "GenSigTimeoutTime" BU_SG_REL_ GW_Routing_Derivate SG_ 1662 LAD_Fehlerstatus 5000;
BA_REL_ "GenSigTimeoutTime" BU_SG_REL_ GW_Routing_Derivate SG_ 1662 LAD_Warnlampe_Anf 5000;
BA_REL_ "GenSigTimeoutTime" BU_SG_REL_ GW_Routing_Derivate SG_ 1380 LAD_01_CHK 5000;
BA_REL_ "GenSigTimeoutTime" BU_SG_REL_ GW_Routing_Derivate SG_ 1380 LAD_01_BZ 5000;
BA_REL_ "GenSigTimeoutTime" BU_SG_REL_ GW_Applikation_Derivate SG_ 1380 LAD_IstModus 5000;
BA_REL_ "GenSigTimeoutTime" BU_SG_REL_ GW_Routing_Derivate SG_ 1380 LAD_IstModus 5000;
BA_REL_ "GenSigTimeoutTime" BU_SG_REL_ GW_Routing_Derivate SG_ 1380 LAD_AC_Istspannung 5000;
BA_REL_ "GenSigTimeoutTime" BU_SG_REL_ GW_Applikation_Derivate SG_ 1380 LAD_AC_Istspannung 5000;
BA_REL_ "GenSigTimeoutTime" BU_SG_REL_ GW_Routing_Derivate SG_ 1380 LAD_IstSpannung_HV 5000;
BA_REL_ "GenSigTimeoutTime" BU_SG_REL_ GW_Applikation_Derivate SG_ 1380 LAD_IstStrom_HV 5000;
BA_REL_ "GenSigTimeoutTime" BU_SG_REL_ GW_Routing_Derivate SG_ 1380 LAD_IstStrom_HV 5000;
BA_REL_ "GenSigTimeoutTime" BU_SG_REL_ GW_Routing_Derivate SG_ 1380 LAD_Status_Spgfreiheit 5000;
BA_REL_ "GenSigTimeoutTime" BU_SG_REL_ GW_Routing_Derivate SG_ 1380 LAD_Temperatur 5000;
BA_REL_ "GenSigTimeoutTime" BU_SG_REL_ GW_Routing_Derivate SG_ 1380 LAD_Verlustleistung 5000;
BA_REL_ "GenSigTimeoutTime" BU_SG_REL_ Ladegeraet_PAG_PF SG_ 1385 HVEM_Abschaltstatus 5000;
BA_REL_ "GenSigTimeoutTime" BU_SG_REL_ Motor_MED17_Hybrid SG_ 1385 HVEM_HV_Anf 5000;
BA_REL_ "GenSigTimeoutTime" BU_SG_REL_ Ladegeraet_PAG_PF SG_ 1385 HVEM_Nachladen_Anf 5000;
BA_REL_ "GenSigTimeoutTime" BU_SG_REL_ BMS_Hybrid SG_ 1385 HVEM_FreigabeKlimatisierung 5000;
BA_REL_ "GenSigTimeoutTime" BU_SG_REL_ GW_Routing_Derivate SG_ 1482 BMS_07_CRC 5000;
BA_REL_ "GenSigTimeoutTime" BU_SG_REL_ GW_Routing_Derivate SG_ 1482 BMS_07_BZ 5000;
BA_REL_ "GenSigTimeoutTime" BU_SG_REL_ GW_Routing_Derivate SG_ 1482 BMS_Energieinhalt 5000;
BA_REL_ "GenSigTimeoutTime" BU_SG_REL_ GW_Routing_Derivate SG_ 1482 BMS_Ladevorgang_aktiv 5000;
BA_REL_ "GenSigTimeoutTime" BU_SG_REL_ GW_Routing_Derivate SG_ 1482 BMS_MaxEnergieinhalt 5000;
BA_REL_ "GenSigTimeoutTime" BU_SG_REL_ GW_Routing_Derivate SG_ 1482 BMS_Ausgleichsladung_Anf 5000;
BA_REL_ "GenSigTimeoutTime" BU_SG_REL_ GW_Routing_Derivate SG_ 1482 BMS_Gesamtst_Spgfreiheit 5000;
BA_REL_ "GenSigTimeoutTime" BU_SG_REL_ GW_Applikation_Derivate SG_ 1519 BMS_IstStrom 5000;
BA_REL_ "GenSigTimeoutTime" BU_SG_REL_ GW_Routing_Derivate SG_ 1519 BMS_IstStrom 5000;
BA_REL_ "GenSigTimeoutTime" BU_SG_REL_ GW_Routing_Derivate SG_ 1519 BMS_PTC_Stufe 5000;
BA_REL_ "GenSigTimeoutTime" BU_SG_REL_ GW_Applikation_Derivate SG_ 1519 BMS_PTC_IstStrom 5000;
BA_REL_ "GenSigTimeoutTime" BU_SG_REL_ GW_Routing_Derivate SG_ 1519 BMS_PTC_IstStrom 5000;
BA_REL_ "GenSigTimeoutTime" BU_SG_REL_ GW_Routing_Derivate SG_ 1519 BMS_Status_Kuehlung 5000;
BA_REL_ "GenSigTimeoutTime" BU_SG_REL_ GW_Applikation_Derivate SG_ 1519 BMS_Status_Kuehlung 5000;
BA_REL_ "GenSigTimeoutTime" BU_SG_REL_ GW_Routing_Derivate SG_ 1519 BMS_Temp_Zelle_Min 5000;
BA_REL_ "GenSigTimeoutTime" BU_SG_REL_ GW_Routing_Derivate SG_ 1519 BMS_Temp_Zelle_Max 5000;
BA_REL_ "GenSigTimeoutTime" BU_SG_REL_ GW_Routing_Derivate SG_ 1519 BMS_Pumpendrehzahl 5000;
BA_REL_ "GenSigTimeoutTime" BU_SG_REL_ GW_Routing_Derivate SG_ 1519 BMS_Status_3_2_Ventil1 5000;
BA_REL_ "GenSigTimeoutTime" BU_SG_REL_ GW_Routing_Derivate SG_ 1519 BMS_Status_3_2_Ventil2 5000;
BA_REL_ "GenSigTimeoutTime" BU_SG_REL_ GW_Routing_Derivate SG_ 1438 BMS_Temperierung_Anf 5000;
BA_REL_ "GenSigTimeoutTime" BU_SG_REL_ GW_Routing_Derivate SG_ 1438 BMS_Soll_PWM_Pumpe 5000;
BA_REL_ "GenSigTimeoutTime" BU_SG_REL_ GW_Routing_Derivate SG_ 1438 BMS_Temperatur 5000;
BA_REL_ "GenSigTimeoutTime" BU_SG_REL_ GW_Routing_Derivate SG_ 1438 BMS_IstVorlaufTemperatur 5000;
BA_REL_ "GenSigTimeoutTime" BU_SG_REL_ GW_Routing_Derivate SG_ 1438 BMS_SollVolumenstrom 5000;
BA_REL_ "GenSigTimeoutTime" BU_SG_REL_ GW_Routing_Derivate SG_ 1438 BMS_SollVorlauftemperatur 5000;
BA_REL_ "GenSigTimeoutTime" BU_SG_REL_ GW_Routing_Derivate SG_ 1438 BMS_IstRuecklaufTemperatur_02 5000;
BA_REL_ "GenSigTimeoutTime" BU_SG_REL_ GW_Routing_Derivate SG_ 1438 BMS_SollVorlaufTemp_Epsilon 5000;
BA_REL_ "GenSigTimeoutTime" BU_SG_REL_ GW_Applikation_Derivate SG_ 1428 HVLM_HV_Anf 5000;
BA_REL_ "GenSigTimeoutTime" BU_SG_REL_ GW_Routing_Derivate SG_ 1428 HVLM_HV_Anf 5000;
BA_REL_ "GenSigTimeoutTime" BU_SG_REL_ GW_Applikation_Derivate SG_ 1428 HVLM_Stecker_Status 5000;
BA_REL_ "GenSigTimeoutTime" BU_SG_REL_ BMS_Hybrid SG_ 1428 HVLM_Stecker_Status 500;
BA_REL_ "GenSigTimeoutTime" BU_SG_REL_ GW_Routing_Derivate SG_ 1428 HVLM_Stecker_Status 5000;
BA_REL_ "GenSigTimeoutTime" BU_SG_REL_ GW_Routing_Derivate SG_ 1428 HVLM_Restladezeit_HV_Bat_02 5000;
BA_REL_ "GenSigTimeoutTime" BU_SG_REL_ GW_Routing_Derivate SG_ 1428 HVLM_Lademodus_HV_Bat 5000;
BA_REL_ "GenSigTimeoutTime" BU_SG_REL_ GW_Applikation_Derivate SG_ 1428 HVLM_Bat_laden_aktiv 5000;
BA_REL_ "GenSigTimeoutTime" BU_SG_REL_ GW_Routing_Derivate SG_ 1428 HVLM_Bat_laden_aktiv 5000;
BA_REL_ "GenSigTimeoutTime" BU_SG_REL_ GW_Routing_Derivate SG_ 1428 HVLM_Ladeart 5000;
BA_REL_ "GenSigTimeoutTime" BU_SG_REL_ GW_Applikation_Derivate SG_ 1428 HVLM_VK_Anf 5000;
BA_REL_ "GenSigTimeoutTime" BU_SG_REL_ GW_Routing_Derivate SG_ 1428 HVLM_VK_Anf 5000;
BA_REL_ "GenSigTimeoutTime" BU_SG_REL_ GW_Routing_Derivate SG_ 1428 HVLM_Ladesystemhinweise 5000;
BA_REL_ "GenSigTimeoutTime" BU_SG_REL_ GW_Routing_Derivate SG_ 1428 HVLM_Langzeit_Laden 5000;
BA_REL_ "GenSigTimeoutTime" BU_SG_REL_ BMS_Hybrid SG_ 1428 HVLM_Langzeit_Laden 500;
BA_REL_ "GenSigTimeoutTime" BU_SG_REL_ GW_Routing_Derivate SG_ 1428 HVLM_Klima_Temp 5000;
BA_REL_ "GenSigTimeoutTime" BU_SG_REL_ GW_Routing_Derivate SG_ 1428 HVLM_VK_Modus 5000;
BA_REL_ "GenSigTimeoutTime" BU_SG_REL_ GW_Routing_Derivate SG_ 1428 HVLM_HSH_Anf 5000;
BA_REL_ "GenSigTimeoutTime" BU_SG_REL_ GW_Routing_Derivate SG_ 305 MO_ePowermeter 500;
BA_REL_ "GenSigTimeoutTime" BU_SG_REL_ GW_Routing_Derivate SG_ 305 MO_W_Reku_normiert_ueberlauf 500;
BA_REL_ "GenSigTimeoutTime" BU_SG_REL_ Ladegeraet_PAG_PF SG_ 305 Ladezustand 500;
BA_REL_ "GenSigTimeoutTime" BU_SG_REL_ GW_Routing_Derivate SG_ 305 Ladezustand 500;
BA_REL_ "GenSigTimeoutTime" BU_SG_REL_ GW_Applikation_Derivate SG_ 305 Ladezustand 500;
BA_REL_ "GenSigTimeoutTime" BU_SG_REL_ GW_Routing_Derivate SG_ 305 Enrgfluss_State 500;
BA_REL_ "GenSigTimeoutTime" BU_SG_REL_ GW_Routing_Derivate SG_ 305 MO_W_Reku_normiert 500;
BA_REL_ "GenSigTimeoutTime" BU_SG_REL_ GW_Routing_Derivate SG_ 305 MO_Powermeter 500;
BA_REL_ "GenSigTimeoutTime" BU_SG_REL_ Motor_MED17_Hybrid SG_ 914 ESP_07_BZ 800;
BA_REL_ "GenSigTimeoutTime" BU_SG_REL_ Motor_MED17_Hybrid SG_ 914 ESP_07_CHK 800;
BA_REL_ "GenSigTimeoutTime" BU_SG_REL_ Motor_MED17_Hybrid SG_ 914 ESP_OBD_Status 800;
BA_REL_ "GenSigTimeoutTime" BU_SG_REL_ Motor_MED17_Hybrid SG_ 914 OBD_Fehler_Radsensor_VR 800;
BA_REL_ "GenSigTimeoutTime" BU_SG_REL_ Motor_MED17_Hybrid SG_ 914 OBD_Fehler_Radsensor_VL 800;
BA_REL_ "GenSigTimeoutTime" BU_SG_REL_ Motor_MED17_Hybrid SG_ 914 OBD_Fehler_Radsensor_HR 800;
BA_REL_ "GenSigTimeoutTime" BU_SG_REL_ Motor_MED17_Hybrid SG_ 914 OBD_Fehler_Radsensor_HL 800;
BA_REL_ "GenSigTimeoutTime" BU_SG_REL_ Getriebe_Derivate SG_ 906 KL_T_PSM_off 1000;
BA_REL_ "GenSigTimeoutTime" BU_SG_REL_ Motor_EDC17_Pirol SG_ 906 F_Klima_08_PAG_Fwk 1000;
BA_REL_ "GenSigTimeoutTime" BU_SG_REL_ Getriebe_Derivate SG_ 906 F_Klima_08_PAG_Fwk 1000;
BA_REL_ "GenSigTimeoutTime" BU_SG_REL_ Motor_EDC17_Pirol SG_ 906 KL_T_Abgasklappe 1000;
BA_REL_ "GenSigTimeoutTime" BU_SG_REL_ GW_Applikation_Derivate SG_ 1731 NMH_ESP_Start_1 2000;
BA_REL_ "GenSigTimeoutTime" BU_SG_REL_ Getriebe_Derivate SG_ 1731 NMH_ESP_Start_1 2000;
BA_REL_ "GenSigTimeoutTime" BU_SG_REL_ Motor_MED17_Hybrid SG_ 1731 NMH_ESP_Start_1 2000;
BA_REL_ "GenSigTimeoutTime" BU_SG_REL_ Motor_EDC17_Pirol SG_ 1731 NMH_ESP_Start_1 2000;
BA_REL_ "GenSigTimeoutTime" BU_SG_REL_ LEH_Hybrid SG_ 1731 NMH_ESP_Start_1 2000;
BA_REL_ "GenSigTimeoutTime" BU_SG_REL_ Ladegeraet_PAG_PF SG_ 1731 NMH_ESP_Start_1 2000;
BA_REL_ "GenSigTimeoutTime" BU_SG_REL_ BMS_Hybrid SG_ 1731 NMH_ESP_Start_1 2000;
BA_REL_ "GenSigTimeoutTime" BU_SG_REL_ Ladegeraet_PAG_PF SG_ 946 BEM_NV_NachladAnf 1000;
BA_REL_ "GenSigTimeoutTime" BU_SG_REL_ LEH_Hybrid SG_ 946 BEM_HYB_DC_uMinLV 1000;
BA_REL_ "GenSigTimeoutTime" BU_SG_REL_ LEH_Hybrid SG_ 946 BEM_HYB_DC_uSollLV 1000;
BA_REL_ "GenSigTimeoutTime" BU_SG_REL_ GW_Routing_Derivate SG_ 1628 BMS_IstSpannung_HV 5000;
BA_REL_ "GenSigTimeoutTime" BU_SG_REL_ GW_Routing_Derivate SG_ 1628 BMS_Temperatur_Ansaugluft 5000;
BA_REL_ "GenSigTimeoutTime" BU_SG_REL_ GW_Routing_Derivate SG_ 1628 BMS_Temperatur 5000;
BA_REL_ "GenSigTimeoutTime" BU_SG_REL_ GW_Routing_Derivate SG_ 1628 BMS_HYB_Spuelbetrieb_Status 5000;
BA_REL_ "GenSigTimeoutTime" BU_SG_REL_ GW_Routing_Derivate SG_ 1628 BMS_HYB_Temp_vor_Verd 5000;
BA_REL_ "GenSigTimeoutTime" BU_SG_REL_ GW_Routing_Derivate SG_ 1628 BMS_HYB_Temp_nach_Verd 5000;
BA_REL_ "GenSigTimeoutTime" BU_SG_REL_ GW_Applikation_Derivate SG_ 1628 BMS_HYB_Kuehlung_Anf 5000;
BA_REL_ "GenSigTimeoutTime" BU_SG_REL_ GW_Routing_Derivate SG_ 1628 BMS_HYB_Kuehlung_Anf 5000;
BA_REL_ "GenSigTimeoutTime" BU_SG_REL_ GW_Routing_Derivate SG_ 1628 BMS_HYB_ASV_vorne_Status 5000;
BA_REL_ "GenSigTimeoutTime" BU_SG_REL_ GW_Routing_Derivate SG_ 1628 BMS_HYB_ASV_hinten_Status 5000;
BA_REL_ "GenSigTimeoutTime" BU_SG_REL_ GW_Applikation_Derivate SG_ 1628 BMS_HYB_KD_Fehler 5000;
BA_REL_ "GenSigTimeoutTime" BU_SG_REL_ GW_Routing_Derivate SG_ 1628 BMS_HYB_KD_Fehler 5000;
BA_REL_ "GenSigTimeoutTime" BU_SG_REL_ GW_Routing_Derivate SG_ 1628 BMS_HYB_BattFanSpd 5000;
BA_REL_ "GenSigTimeoutTime" BU_SG_REL_ GW_Routing_Derivate SG_ 1628 BMS_HYB_VentilationReq 5000;
BA_REL_ "GenSigTimeoutTime" BU_SG_REL_ Tool SG_ 490 CCP_GE_DTO_01_Data 500;
BA_REL_ "GenSigTimeoutTime" BU_SG_REL_ Tool SG_ 488 CCP_MO_DTO_01_Data 500;
BA_REL_ "GenSigTimeoutTime" BU_SG_REL_ Tool SG_ 2616986625 CCP_MO_DTO_02_Data 500;
BA_REL_ "GenSigTimeoutTime" BU_SG_REL_ GW_Applikation_Derivate SG_ 945 DC_TiefsetzBereit 1000;
BA_REL_ "GenSigTimeoutTime" BU_SG_REL_ GW_Applikation_Derivate SG_ 945 DC_HYB_iAktLV 1000;
BA_REL_ "GenSigTimeoutTime" BU_SG_REL_ GW_Applikation_Derivate SG_ 945 DC_HYB_iAktReserveLV 1000;
BA_REL_ "GenSigTimeoutTime" BU_SG_REL_ GW_Applikation_Derivate SG_ 945 DC_HYB_uAktLV 1000;
BA_REL_ "GenSigTimeoutTime" BU_SG_REL_ GW_Applikation_Derivate SG_ 945 DC_HYB_Abregelung_Temperatur 1000;
BA_REL_ "GenSigTimeoutTime" BU_SG_REL_ GW_Applikation_Derivate SG_ 945 DC_HYB_Fehler_RedLeistung 1000;
BA_REL_ "GenSigTimeoutTime" BU_SG_REL_ GW_Applikation_Derivate SG_ 945 DC_HYB_Fehler_intern 1000;
BA_REL_ "GenSigTimeoutTime" BU_SG_REL_ GW_Applikation_Derivate SG_ 945 DC_HYB_Fehler_Spannung 1000;
BA_REL_ "GenSigTimeoutTime" BU_SG_REL_ GW_Applikation_Derivate SG_ 945 DC_HYB_Auslastungsgrad 1000;
BA_REL_ "GenSigTimeoutTime" BU_SG_REL_ Motor_EDC17_Pirol SG_ 256 ESP_v_Signal 500;
BA_REL_ "GenSigTimeoutTime" BU_SG_REL_ GW_Routing_Derivate SG_ 256 ESP_v_Signal 500;
BA_REL_ "GenSigTimeoutTime" BU_SG_REL_ Getriebe_Derivate SG_ 256 ESP_v_Signal 500;
BA_REL_ "GenSigTimeoutTime" BU_SG_REL_ Motor_MED17_Hybrid SG_ 256 ESP_v_Signal 500;
BA_REL_ "GenSigTimeoutTime" BU_SG_REL_ LEH_Hybrid SG_ 256 ESP_v_Signal 500;
BA_REL_ "GenSigTimeoutTime" BU_SG_REL_ BMS_Hybrid SG_ 256 ESP_v_Signal 500;
BA_REL_ "GenSigTimeoutTime" BU_SG_REL_ GW_Applikation_Derivate SG_ 256 ESP_v_Signal 500;
BA_REL_ "GenSigTimeoutTime" BU_SG_REL_ Motor_EDC17_Pirol SG_ 256 ESP_01_CHK 500;
BA_REL_ "GenSigTimeoutTime" BU_SG_REL_ GW_Routing_Derivate SG_ 256 ESP_01_CHK 500;
BA_REL_ "GenSigTimeoutTime" BU_SG_REL_ BMS_Hybrid SG_ 256 ESP_01_CHK 500;
BA_REL_ "GenSigTimeoutTime" BU_SG_REL_ LEH_Hybrid SG_ 256 ESP_01_CHK 500;
BA_REL_ "GenSigTimeoutTime" BU_SG_REL_ Getriebe_Derivate SG_ 256 ESP_01_CHK 500;
BA_REL_ "GenSigTimeoutTime" BU_SG_REL_ Motor_MED17_Hybrid SG_ 256 ESP_01_CHK 500;
BA_REL_ "GenSigTimeoutTime" BU_SG_REL_ Motor_EDC17_Pirol SG_ 256 ESP_01_BZ 500;
BA_REL_ "GenSigTimeoutTime" BU_SG_REL_ GW_Routing_Derivate SG_ 256 ESP_01_BZ 500;
BA_REL_ "GenSigTimeoutTime" BU_SG_REL_ LEH_Hybrid SG_ 256 ESP_01_BZ 500;
BA_REL_ "GenSigTimeoutTime" BU_SG_REL_ Getriebe_Derivate SG_ 256 ESP_01_BZ 500;
BA_REL_ "GenSigTimeoutTime" BU_SG_REL_ Motor_MED17_Hybrid SG_ 256 ESP_01_BZ 500;
BA_REL_ "GenSigTimeoutTime" BU_SG_REL_ BMS_Hybrid SG_ 256 ESP_01_BZ 500;
BA_REL_ "GenSigTimeoutTime" BU_SG_REL_ Motor_EDC17_Pirol SG_ 256 ASR_Moment_langsam 500;
BA_REL_ "GenSigTimeoutTime" BU_SG_REL_ GW_Routing_Derivate SG_ 256 ASR_Moment_langsam 500;
BA_REL_ "GenSigTimeoutTime" BU_SG_REL_ Motor_MED17_Hybrid SG_ 256 ASR_Moment_langsam 500;
BA_REL_ "GenSigTimeoutTime" BU_SG_REL_ Motor_EDC17_Pirol SG_ 256 ASR_MSR_Moment_schnell 500;
BA_REL_ "GenSigTimeoutTime" BU_SG_REL_ GW_Routing_Derivate SG_ 256 ASR_MSR_Moment_schnell 500;
BA_REL_ "GenSigTimeoutTime" BU_SG_REL_ Motor_MED17_Hybrid SG_ 256 ASR_MSR_Moment_schnell 500;
BA_REL_ "GenSigTimeoutTime" BU_SG_REL_ Motor_EDC17_Pirol SG_ 256 ASR_Tastung_passiv 500;
BA_REL_ "GenSigTimeoutTime" BU_SG_REL_ GW_Routing_Derivate SG_ 256 ASR_Tastung_passiv 500;
BA_REL_ "GenSigTimeoutTime" BU_SG_REL_ Getriebe_Derivate SG_ 256 ASR_Tastung_passiv 500;
BA_REL_ "GenSigTimeoutTime" BU_SG_REL_ Motor_MED17_Hybrid SG_ 256 ASR_Tastung_passiv 500;
BA_REL_ "GenSigTimeoutTime" BU_SG_REL_ Motor_EDC17_Pirol SG_ 256 ESP_Tastung_passiv 500;
BA_REL_ "GenSigTimeoutTime" BU_SG_REL_ GW_Routing_Derivate SG_ 256 ESP_Tastung_passiv 500;
BA_REL_ "GenSigTimeoutTime" BU_SG_REL_ Getriebe_Derivate SG_ 256 ESP_Tastung_passiv 500;
BA_REL_ "GenSigTimeoutTime" BU_SG_REL_ Motor_MED17_Hybrid SG_ 256 ESP_Tastung_passiv 500;
BA_REL_ "GenSigTimeoutTime" BU_SG_REL_ Motor_EDC17_Pirol SG_ 256 ESP_Systemstatus 500;
BA_REL_ "GenSigTimeoutTime" BU_SG_REL_ GW_Routing_Derivate SG_ 256 ESP_Systemstatus 500;
BA_REL_ "GenSigTimeoutTime" BU_SG_REL_ Motor_MED17_Hybrid SG_ 256 ESP_Systemstatus 500;
BA_REL_ "GenSigTimeoutTime" BU_SG_REL_ Getriebe_Derivate SG_ 256 ESP_Systemstatus 500;
BA_REL_ "GenSigTimeoutTime" BU_SG_REL_ GW_Routing_Derivate SG_ 256 ASR_Schalteingriff 500;
BA_REL_ "GenSigTimeoutTime" BU_SG_REL_ Getriebe_Derivate SG_ 256 ASR_Schalteingriff 500;
BA_REL_ "GenSigTimeoutTime" BU_SG_REL_ GW_Routing_Derivate SG_ 256 OBD_Schlechtweg 500;
BA_REL_ "GenSigTimeoutTime" BU_SG_REL_ GW_Routing_Derivate SG_ 256 OBD_QBit_Schlechtweg 500;
BA_REL_ "GenSigTimeoutTime" BU_SG_REL_ BMS_Hybrid SG_ 256 ESP_QBit_v_Signal 500;
BA_REL_ "GenSigTimeoutTime" BU_SG_REL_ Motor_EDC17_Pirol SG_ 256 ESP_QBit_v_Signal 500;
BA_REL_ "GenSigTimeoutTime" BU_SG_REL_ GW_Routing_Derivate SG_ 256 ESP_QBit_v_Signal 500;
BA_REL_ "GenSigTimeoutTime" BU_SG_REL_ LEH_Hybrid SG_ 256 ESP_QBit_v_Signal 500;
BA_REL_ "GenSigTimeoutTime" BU_SG_REL_ Motor_MED17_Hybrid SG_ 256 ESP_QBit_v_Signal 500;
BA_REL_ "GenSigTimeoutTime" BU_SG_REL_ Motor_EDC17_Pirol SG_ 256 ABS_Bremsung 500;
BA_REL_ "GenSigTimeoutTime" BU_SG_REL_ GW_Routing_Derivate SG_ 256 ABS_Bremsung 500;
BA_REL_ "GenSigTimeoutTime" BU_SG_REL_ Getriebe_Derivate SG_ 256 ABS_Bremsung 500;
BA_REL_ "GenSigTimeoutTime" BU_SG_REL_ Motor_MED17_Hybrid SG_ 256 ABS_Bremsung 500;
BA_REL_ "GenSigTimeoutTime" BU_SG_REL_ Motor_EDC17_Pirol SG_ 256 ASR_Anf 500;
BA_REL_ "GenSigTimeoutTime" BU_SG_REL_ GW_Routing_Derivate SG_ 256 ASR_Anf 500;
BA_REL_ "GenSigTimeoutTime" BU_SG_REL_ Getriebe_Derivate SG_ 256 ASR_Anf 500;
BA_REL_ "GenSigTimeoutTime" BU_SG_REL_ Motor_MED17_Hybrid SG_ 256 ASR_Anf 500;
BA_REL_ "GenSigTimeoutTime" BU_SG_REL_ Motor_EDC17_Pirol SG_ 256 MSR_Anf 500;
BA_REL_ "GenSigTimeoutTime" BU_SG_REL_ GW_Routing_Derivate SG_ 256 MSR_Anf 500;
BA_REL_ "GenSigTimeoutTime" BU_SG_REL_ Getriebe_Derivate SG_ 256 MSR_Anf 500;
BA_REL_ "GenSigTimeoutTime" BU_SG_REL_ Motor_MED17_Hybrid SG_ 256 MSR_Anf 500;
BA_REL_ "GenSigTimeoutTime" BU_SG_REL_ Motor_EDC17_Pirol SG_ 256 EBV_Eingriff 500;
BA_REL_ "GenSigTimeoutTime" BU_SG_REL_ GW_Routing_Derivate SG_ 256 EBV_Eingriff 500;
BA_REL_ "GenSigTimeoutTime" BU_SG_REL_ Motor_MED17_Hybrid SG_ 256 EBV_Eingriff 500;
BA_REL_ "GenSigTimeoutTime" BU_SG_REL_ Motor_EDC17_Pirol SG_ 256 EDS_Eingriff 500;
BA_REL_ "GenSigTimeoutTime" BU_SG_REL_ GW_Routing_Derivate SG_ 256 EDS_Eingriff 500;
BA_REL_ "GenSigTimeoutTime" BU_SG_REL_ Getriebe_Derivate SG_ 256 EDS_Eingriff 500;
BA_REL_ "GenSigTimeoutTime" BU_SG_REL_ Motor_MED17_Hybrid SG_ 256 EDS_Eingriff 500;
BA_REL_ "GenSigTimeoutTime" BU_SG_REL_ Motor_EDC17_Pirol SG_ 256 ESP_Eingriff 500;
BA_REL_ "GenSigTimeoutTime" BU_SG_REL_ GW_Routing_Derivate SG_ 256 ESP_Eingriff 500;
BA_REL_ "GenSigTimeoutTime" BU_SG_REL_ Getriebe_Derivate SG_ 256 ESP_Eingriff 500;
BA_REL_ "GenSigTimeoutTime" BU_SG_REL_ Motor_MED17_Hybrid SG_ 256 ESP_Eingriff 500;
BA_REL_ "GenSigTimeoutTime" BU_SG_REL_ Motor_EDC17_Pirol SG_ 256 ESP_ASP 500;
BA_REL_ "GenSigTimeoutTime" BU_SG_REL_ GW_Routing_Derivate SG_ 256 ESP_ASP 500;
BA_REL_ "GenSigTimeoutTime" BU_SG_REL_ Motor_MED17_Hybrid SG_ 256 ESP_ASP 500;
BA_REL_ "GenSigTimeoutTime" BU_SG_REL_ GW_Applikation_Derivate SG_ 256 ESP_KD_Fehler 500;
BA_REL_ "GenSigTimeoutTime" BU_SG_REL_ GW_Routing_Derivate SG_ 256 ESP_KD_Fehler 500;
BA_REL_ "GenSigTimeoutTime" BU_SG_REL_ Motor_EDC17_Pirol SG_ 257 ESP_02_CHK 500;
BA_REL_ "GenSigTimeoutTime" BU_SG_REL_ GW_Routing_Derivate SG_ 257 ESP_02_CHK 500;
BA_REL_ "GenSigTimeoutTime" BU_SG_REL_ Getriebe_Derivate SG_ 257 ESP_02_CHK 500;
BA_REL_ "GenSigTimeoutTime" BU_SG_REL_ Motor_MED17_Hybrid SG_ 257 ESP_02_CHK 500;
BA_REL_ "GenSigTimeoutTime" BU_SG_REL_ Motor_EDC17_Pirol SG_ 257 ESP_02_BZ 500;
BA_REL_ "GenSigTimeoutTime" BU_SG_REL_ GW_Routing_Derivate SG_ 257 ESP_02_BZ 500;
BA_REL_ "GenSigTimeoutTime" BU_SG_REL_ Getriebe_Derivate SG_ 257 ESP_02_BZ 500;
BA_REL_ "GenSigTimeoutTime" BU_SG_REL_ Motor_MED17_Hybrid SG_ 257 ESP_02_BZ 500;
BA_REL_ "GenSigTimeoutTime" BU_SG_REL_ GW_Routing_Derivate SG_ 257 ESP_QBit_Gierrate 500;
BA_REL_ "GenSigTimeoutTime" BU_SG_REL_ Motor_EDC17_Pirol SG_ 257 ESP_QBit_Laengsbeschl 500;
BA_REL_ "GenSigTimeoutTime" BU_SG_REL_ GW_Routing_Derivate SG_ 257 ESP_QBit_Laengsbeschl 500;
BA_REL_ "GenSigTimeoutTime" BU_SG_REL_ Motor_MED17_Hybrid SG_ 257 ESP_QBit_Laengsbeschl 500;
BA_REL_ "GenSigTimeoutTime" BU_SG_REL_ Motor_EDC17_Pirol SG_ 257 ESP_QBit_Querb 500;
BA_REL_ "GenSigTimeoutTime" BU_SG_REL_ GW_Routing_Derivate SG_ 257 ESP_QBit_Querb 500;
BA_REL_ "GenSigTimeoutTime" BU_SG_REL_ Motor_MED17_Hybrid SG_ 257 ESP_QBit_Querb 500;
BA_REL_ "GenSigTimeoutTime" BU_SG_REL_ Motor_EDC17_Pirol SG_ 257 ESP_Stillstandsflag 500;
BA_REL_ "GenSigTimeoutTime" BU_SG_REL_ GW_Routing_Derivate SG_ 257 ESP_Stillstandsflag 500;
BA_REL_ "GenSigTimeoutTime" BU_SG_REL_ Motor_MED17_Hybrid SG_ 257 ESP_Stillstandsflag 500;
BA_REL_ "GenSigTimeoutTime" BU_SG_REL_ Motor_EDC17_Pirol SG_ 257 ESP_Querbeschleunigung 500;
BA_REL_ "GenSigTimeoutTime" BU_SG_REL_ GW_Routing_Derivate SG_ 257 ESP_Querbeschleunigung 500;
BA_REL_ "GenSigTimeoutTime" BU_SG_REL_ Getriebe_Derivate SG_ 257 ESP_Querbeschleunigung 500;
BA_REL_ "GenSigTimeoutTime" BU_SG_REL_ Motor_MED17_Hybrid SG_ 257 ESP_Querbeschleunigung 500;
BA_REL_ "GenSigTimeoutTime" BU_SG_REL_ Motor_EDC17_Pirol SG_ 257 ESP_Laengsbeschl 500;
BA_REL_ "GenSigTimeoutTime" BU_SG_REL_ GW_Routing_Derivate SG_ 257 ESP_Laengsbeschl 500;
BA_REL_ "GenSigTimeoutTime" BU_SG_REL_ Getriebe_Derivate SG_ 257 ESP_Laengsbeschl 500;
BA_REL_ "GenSigTimeoutTime" BU_SG_REL_ Motor_MED17_Hybrid SG_ 257 ESP_Laengsbeschl 500;
BA_REL_ "GenSigTimeoutTime" BU_SG_REL_ GW_Routing_Derivate SG_ 257 ESP_Verteil_Wankmom 500;
BA_REL_ "GenSigTimeoutTime" BU_SG_REL_ GW_Routing_Derivate SG_ 257 ESP_QBit_Anf_Vert_Wank 500;
BA_REL_ "GenSigTimeoutTime" BU_SG_REL_ GW_Routing_Derivate SG_ 257 ESP_Gierrate 500;
BA_REL_ "GenSigTimeoutTime" BU_SG_REL_ GW_Routing_Derivate SG_ 257 ESP_VZ_Gierrate 500;
BA_REL_ "GenSigTimeoutTime" BU_SG_REL_ GW_Routing_Derivate SG_ 257 ESP_Notbremsanzeige 500;
BA_REL_ "GenSigTimeoutTime" BU_SG_REL_ GW_Routing_Derivate SG_ 257 ESP_SpannungsAnf 500;
BA_REL_ "GenSigTimeoutTime" BU_SG_REL_ Ladegeraet_PAG_PF SG_ 1795 ISO_Functionaler_Req_Abgas 500;
BA_REL_ "GenSigTimeoutTime" BU_SG_REL_ BMS_Hybrid SG_ 1795 ISO_Functionaler_Req_Abgas 500;
BA_REL_ "GenSigTimeoutTime" BU_SG_REL_ Motor_EDC17_Pirol SG_ 1795 ISO_Functionaler_Req_Abgas 500;
BA_REL_ "GenSigTimeoutTime" BU_SG_REL_ Motor_MED17_Hybrid SG_ 1795 ISO_Functionaler_Req_Abgas 500;
BA_REL_ "GenSigTimeoutTime" BU_SG_REL_ Getriebe_Derivate SG_ 1795 ISO_Functionaler_Req_Abgas 500;
BA_REL_ "GenSigTimeoutTime" BU_SG_REL_ LEH_Hybrid SG_ 1795 ISO_Functionaler_Req_Abgas 500;
BA_REL_ "GenSigTimeoutTime" BU_SG_REL_ Getriebe_Derivate SG_ 482 CCP_GE_CRO_01_Data 500;
BA_REL_ "GenSigTimeoutTime" BU_SG_REL_ Motor_EDC17_Pirol SG_ 259 ESP_03_CHK 500;
BA_REL_ "GenSigTimeoutTime" BU_SG_REL_ GW_Routing_Derivate SG_ 259 ESP_03_CHK 500;
BA_REL_ "GenSigTimeoutTime" BU_SG_REL_ Getriebe_Derivate SG_ 259 ESP_03_CHK 500;
BA_REL_ "GenSigTimeoutTime" BU_SG_REL_ Motor_MED17_Hybrid SG_ 259 ESP_03_CHK 500;
BA_REL_ "GenSigTimeoutTime" BU_SG_REL_ Motor_EDC17_Pirol SG_ 259 ESP_03_BZ 500;
BA_REL_ "GenSigTimeoutTime" BU_SG_REL_ GW_Routing_Derivate SG_ 259 ESP_03_BZ 500;
BA_REL_ "GenSigTimeoutTime" BU_SG_REL_ Getriebe_Derivate SG_ 259 ESP_03_BZ 500;
BA_REL_ "GenSigTimeoutTime" BU_SG_REL_ Motor_MED17_Hybrid SG_ 259 ESP_03_BZ 500;
BA_REL_ "GenSigTimeoutTime" BU_SG_REL_ Motor_EDC17_Pirol SG_ 259 ESP_VL_FR 500;
BA_REL_ "GenSigTimeoutTime" BU_SG_REL_ GW_Routing_Derivate SG_ 259 ESP_VL_FR 500;
BA_REL_ "GenSigTimeoutTime" BU_SG_REL_ Getriebe_Derivate SG_ 259 ESP_VL_FR 500;
BA_REL_ "GenSigTimeoutTime" BU_SG_REL_ Motor_MED17_Hybrid SG_ 259 ESP_VL_FR 500;
BA_REL_ "GenSigTimeoutTime" BU_SG_REL_ Motor_EDC17_Pirol SG_ 259 ESP_VR_FR 500;
BA_REL_ "GenSigTimeoutTime" BU_SG_REL_ GW_Routing_Derivate SG_ 259 ESP_VR_FR 500;
BA_REL_ "GenSigTimeoutTime" BU_SG_REL_ Getriebe_Derivate SG_ 259 ESP_VR_FR 500;
BA_REL_ "GenSigTimeoutTime" BU_SG_REL_ Motor_MED17_Hybrid SG_ 259 ESP_VR_FR 500;
BA_REL_ "GenSigTimeoutTime" BU_SG_REL_ Motor_EDC17_Pirol SG_ 259 ESP_HL_FR 500;
BA_REL_ "GenSigTimeoutTime" BU_SG_REL_ GW_Routing_Derivate SG_ 259 ESP_HL_FR 500;
BA_REL_ "GenSigTimeoutTime" BU_SG_REL_ Getriebe_Derivate SG_ 259 ESP_HL_FR 500;
BA_REL_ "GenSigTimeoutTime" BU_SG_REL_ Motor_MED17_Hybrid SG_ 259 ESP_HL_FR 500;
BA_REL_ "GenSigTimeoutTime" BU_SG_REL_ Motor_EDC17_Pirol SG_ 259 ESP_HR_FR 500;
BA_REL_ "GenSigTimeoutTime" BU_SG_REL_ GW_Routing_Derivate SG_ 259 ESP_HR_FR 500;
BA_REL_ "GenSigTimeoutTime" BU_SG_REL_ Getriebe_Derivate SG_ 259 ESP_HR_FR 500;
BA_REL_ "GenSigTimeoutTime" BU_SG_REL_ Motor_MED17_Hybrid SG_ 259 ESP_HR_FR 500;
BA_REL_ "GenSigTimeoutTime" BU_SG_REL_ Motor_MED17_Hybrid SG_ 259 ESP_VL_Radgeschw 500;
BA_REL_ "GenSigTimeoutTime" BU_SG_REL_ GW_Routing_Derivate SG_ 259 ESP_VL_Radgeschw 500;
BA_REL_ "GenSigTimeoutTime" BU_SG_REL_ Motor_EDC17_Pirol SG_ 259 ESP_VL_Radgeschw 500;
BA_REL_ "GenSigTimeoutTime" BU_SG_REL_ Getriebe_Derivate SG_ 259 ESP_VL_Radgeschw 500;
BA_REL_ "GenSigTimeoutTime" BU_SG_REL_ Motor_MED17_Hybrid SG_ 259 ESP_VR_Radgeschw 500;
BA_REL_ "GenSigTimeoutTime" BU_SG_REL_ GW_Routing_Derivate SG_ 259 ESP_VR_Radgeschw 500;
BA_REL_ "GenSigTimeoutTime" BU_SG_REL_ Motor_EDC17_Pirol SG_ 259 ESP_VR_Radgeschw 500;
BA_REL_ "GenSigTimeoutTime" BU_SG_REL_ Getriebe_Derivate SG_ 259 ESP_VR_Radgeschw 500;
BA_REL_ "GenSigTimeoutTime" BU_SG_REL_ Motor_MED17_Hybrid SG_ 259 ESP_HL_Radgeschw 500;
BA_REL_ "GenSigTimeoutTime" BU_SG_REL_ GW_Routing_Derivate SG_ 259 ESP_HL_Radgeschw 500;
BA_REL_ "GenSigTimeoutTime" BU_SG_REL_ Motor_EDC17_Pirol SG_ 259 ESP_HL_Radgeschw 500;
BA_REL_ "GenSigTimeoutTime" BU_SG_REL_ Getriebe_Derivate SG_ 259 ESP_HL_Radgeschw 500;
BA_REL_ "GenSigTimeoutTime" BU_SG_REL_ Motor_MED17_Hybrid SG_ 259 ESP_HR_Radgeschw 500;
BA_REL_ "GenSigTimeoutTime" BU_SG_REL_ Motor_EDC17_Pirol SG_ 259 ESP_HR_Radgeschw 500;
BA_REL_ "GenSigTimeoutTime" BU_SG_REL_ GW_Routing_Derivate SG_ 259 ESP_HR_Radgeschw 500;
BA_REL_ "GenSigTimeoutTime" BU_SG_REL_ Getriebe_Derivate SG_ 259 ESP_HR_Radgeschw 500;
BA_REL_ "GenSigTimeoutTime" BU_SG_REL_ GW_Routing_Derivate SG_ 776 ESP_Diagnose 500;
BA_REL_ "GenSigTimeoutTime" BU_SG_REL_ GW_Applikation_Derivate SG_ 776 ESP_Diagnose 500;
BA_REL_ "GenSigTimeoutTime" BU_SG_REL_ Getriebe_Derivate SG_ 776 ESP_Wegimp_VA 500;
BA_REL_ "GenSigTimeoutTime" BU_SG_REL_ Getriebe_Derivate SG_ 776 ESP_Zaehnezahl 500;
BA_REL_ "HYB_Tx_Baureihe" BU_BO_REL_ GW_Routing_Derivate 1532 2;
BA_REL_ "HYB_Tx_Baureihe" BU_BO_REL_ GW_Routing_Derivate 1860 2;
BA_REL_ "HYB_Tx_Baureihe" BU_BO_REL_ GW_Routing_Derivate 1483 2;
BA_REL_ "HYB_Tx_Baureihe" BU_BO_REL_ GW_Routing_Derivate 899 2;
BA_REL_ "HYB_Tx_Baureihe" BU_BO_REL_ GW_Routing_Derivate 1518 2;
BA_REL_ "HYB_Tx_Verwendung" BU_BO_REL_ GW_Routing_Derivate 906 1;
BA_REL_ "HYB_Tx_Baureihe" BU_BO_REL_ GW_Routing_Derivate 906 2;
BA_REL_ "HYB_Tx_Baureihe" BU_BO_REL_ GW_Routing_Derivate 1795 2;
BA_REL_ "HYB_Tx_Baureihe" BU_BO_REL_ GW_Routing_Derivate 482 2;
VAL_ 1446 OBC_KomponentenFehler_01 0 "TestComplete_PASS" 1 "TestComplete_FAIL" 2 "TestNotComplete_PASS" ;
VAL_ 1446 OBC_KomponentenFehler_02 0 "TestComplete_PASS" 1 "TestComplete_FAIL" 2 "TestNotComplete_PASS" ;
VAL_ 1446 OBC_KomponentenFehler_03 0 "TestComplete_PASS" 1 "TestComplete_FAIL" 2 "TestNotComplete_PASS" ;
VAL_ 1446 OBC_KomponentenFehler_04 0 "TestComplete_PASS" 1 "TestComplete_FAIL" 2 "TestNotComplete_PASS" ;
VAL_ 1446 OBC_KomponentenFehler_05 0 "TestComplete_PASS" 1 "TestComplete_FAIL" 2 "TestNotComplete_PASS" ;
VAL_ 1446 OBC_KomponentenFehler_06 0 "TestComplete_PASS" 1 "TestComplete_FAIL" 2 "TestNotComplete_PASS" ;
VAL_ 1446 OBC_KomponentenFehler_07 0 "TestComplete_PASS" 1 "TestComplete_FAIL" 2 "TestNotComplete_PASS" ;
VAL_ 1446 OBC_KomponentenFehler_08 0 "TestComplete_PASS" 1 "TestComplete_FAIL" 2 "TestNotComplete_PASS" ;
VAL_ 1446 OBC_KomponentenFehler_09 0 "TestComplete_PASS" 1 "TestComplete_FAIL" 2 "TestNotComplete_PASS" ;
VAL_ 1446 OBC_KomponentenFehler_10 0 "TestComplete_PASS" 1 "TestComplete_FAIL" 2 "TestNotComplete_PASS" ;
VAL_ 1446 OBC_KomponentenFehler_11 0 "TestComplete_PASS" 1 "TestComplete_FAIL" 2 "TestNotComplete_PASS" ;
VAL_ 1446 OBC_KomponentenFehler_12 0 "TestComplete_PASS" 1 "TestComplete_FAIL" 2 "TestNotComplete_PASS" ;
VAL_ 1446 OBC_KomponentenFehler_13 0 "TestComplete_PASS" 1 "TestComplete_FAIL" 2 "TestNotComplete_PASS" ;
VAL_ 1446 OBC_KomponentenFehler_14 0 "TestComplete_PASS" 1 "TestComplete_FAIL" 2 "TestNotComplete_PASS" ;
VAL_ 1446 OBC_KomponentenFehler_15 0 "TestComplete_PASS" 1 "TestComplete_FAIL" 2 "TestNotComplete_PASS" ;
VAL_ 1446 OBC_KomponentenFehler_16 0 "TestComplete_PASS" 1 "TestComplete_FAIL" 2 "TestNotComplete_PASS" ;
VAL_ 1446 OBC_KomponentenFehler_17 0 "TestComplete_PASS" 1 "TestComplete_FAIL" 2 "TestNotComplete_PASS" ;
VAL_ 1446 OBC_KomponentenFehler_18 0 "TestComplete_PASS" 1 "TestComplete_FAIL" 2 "TestNotComplete_PASS" ;
VAL_ 1446 OBC_KomponentenFehler_19 0 "TestComplete_PASS" 1 "TestComplete_FAIL" 2 "TestNotComplete_PASS" ;
VAL_ 1446 OBC_KomponentenFehler_20 0 "TestComplete_PASS" 1 "TestComplete_FAIL" 2 "TestNotComplete_PASS" ;
VAL_ 1446 OBC_KomponentenFehler_21 0 "TestComplete_PASS" 1 "TestComplete_FAIL" 2 "TestNotComplete_PASS" ;
VAL_ 1446 OBC_KomponentenFehler_22 0 "TestComplete_PASS" 1 "TestComplete_FAIL" 2 "TestNotComplete_PASS" ;
VAL_ 1446 OBC_KomponentenFehler_23 0 "TestComplete_PASS" 1 "TestComplete_FAIL" 2 "TestNotComplete_PASS" ;
VAL_ 1446 OBC_KomponentenFehler_24 0 "TestComplete_PASS" 1 "TestComplete_FAIL" 2 "TestNotComplete_PASS" ;
VAL_ 1446 OBC_KomponentenFehler_25 0 "TestComplete_PASS" 1 "TestComplete_FAIL" 2 "TestNotComplete_PASS" ;
VAL_ 1446 OBC_KomponentenFehler_26 0 "TestComplete_PASS" 1 "TestComplete_FAIL" 2 "TestNotComplete_PASS" ;
VAL_ 1446 OBC_KomponentenFehler_27 0 "TestComplete_PASS" 1 "TestComplete_FAIL" 2 "TestNotComplete_PASS" ;
VAL_ 1446 OBC_KomponentenFehler_28 0 "TestComplete_PASS" 1 "TestComplete_FAIL" 2 "TestNotComplete_PASS" ;
VAL_ 1446 OBC_KomponentenFehler_29 0 "TestComplete_PASS" 1 "TestComplete_FAIL" 2 "TestNotComplete_PASS" ;
VAL_ 1446 OBC_KomponentenFehler_30 0 "TestComplete_PASS" 1 "TestComplete_FAIL" 2 "TestNotComplete_PASS" ;
VAL_ 1446 OBC_KomponentenFehler_31 0 "TestComplete_PASS" 1 "TestComplete_FAIL" 2 "TestNotComplete_PASS" ;
VAL_ 1446 OBC_KomponentenFehler_32 0 "TestComplete_PASS" 1 "TestComplete_FAIL" 2 "TestNotComplete_PASS" ;
VAL_ 1445 OBC_CVN_VLD 0 "ungueltig" 1 "gueltig" ;
VAL_ 1527 RW_Sekundaer_Reichweite 2045 "nicht_verbaut" 2046 "Init" 2047 "Fehler" ;
VAL_ 1527 RW_Sek_Reichweitenv_Einheit 0 "Liter_pro_100km" 1 "kWh_pro_100km" 2 "Kg_pro_100km" 3 "nicht_verbaut" ;
VAL_ 1527 RW_Sek_Reichweitenverbrauch 2047 "Init" ;
VAL_ 1525 RW_RWDS_Lastprofil 2046 "Init" 2047 "Fehler" ;
VAL_ 1525 RW_Gesamt_Reichweite 2045 "nicht_verbaut" 2046 "Init" 2047 "Fehler" ;
VAL_ 1525 RW_Prim_Reichweitenverbrauch 2047 "Init" ;
VAL_ 1525 RW_Prim_Reichweitenv_Einheit 0 "Liter_pro_100km" 1 "kWh_pro_100km" 2 "Kg_pro_100km" 3 "nicht_verbaut" ;
VAL_ 1525 RW_Primaer_Reichweite 2045 "nicht_verbaut" 2046 "Init" 2047 "Fehler" ;
VAL_ 687 BMS_Rekuperation_Ueberlauf 0 "kein_Ueberlauf" 1 "Ueberlauf" ;
VAL_ 687 BMS_Verbrauch_Ueberlauf 0 "kein_Ueberlauf" 1 "Ueberlauf" ;
VAL_ 1532 KL_Autobetrieb_HL 0 "kein_Autobetrieb" 1 "Autobetrieb" ;
VAL_ 1532 KL_Autobetrieb_HR 0 "kein_Autobetrieb" 1 "Autobetrieb" ;
VAL_ 1532 KL_Autobetrieb_VL 0 "kein_Autobetrieb" 1 "Autobetrieb" ;
VAL_ 1532 KL_Autobetrieb_VR 0 "kein_Autobetrieb" 1 "Autobetrieb" ;
VAL_ 1532 KL_Zieltemperatur_HL 0 "Lo" 29 "Hi" 30 "Init" 31 "Fehler" ;
VAL_ 1532 KL_Zieltemperatur_HR 0 "Lo" 29 "Hi" 30 "Init" 31 "Fehler" ;
VAL_ 1532 KL_Zieltemperatur_VL 0 "Lo" 29 "Hi" 30 "Init" 31 "Fehler" ;
VAL_ 1532 KL_Zieltemperatur_VR 0 "Lo" 29 "Hi" 30 "Init" 31 "Fehler" ;
VAL_ 1788 NMH_Ladegeraet_Start_1 1 "Zustand Start (<--Sleep)" ;
VAL_ 1788 NMH_Ladegeraet_Start_2 1 "Zustand Start (<--Prepare to Sleep)" ;
VAL_ 1788 NMH_Ladegeraet_Normal_Mode_1 1 "Zustand Normal Mode (<-- Start)" ;
VAL_ 1788 NMH_Ladegeraet_Normal_Mode_2 1 "Zustand Normal Mode (<-- Ready to Sleep)" ;
VAL_ 1788 NMH_Ladegeraet_Per_WakeUp 0 "wenn_Funktionswakeup" 1 "CAN" 2 "P_Wakeup__Ursache_nicht_bekannt" 3 "Kl_15_Hardware_falls_vorhanden" ;
VAL_ 1788 NMH_Ladegeraet_Fkt_WakeUp 0 "wenn Peripheriewakeup" 1 "niedriger_SOC_12V_Bat" 2 "zeitversetztes_Laden" ;
VAL_ 1788 NMH_Ladegeraet_Klemme_15 1 "Klemme 15 ein" ;
VAL_ 1788 NMH_Ladegeraet_Diagnose 1 "Diagnose bei Kl.15 AUS" ;
VAL_ 1788 NMH_Ladegeraet_MindestAktivZeit 1 "aktiv" ;
VAL_ 1788 NMH_Ladegeraet_Signalfehler 1 "Aktiver_Signalfehler_eingetragen" ;
VAL_ 1788 NMH_Ladegeraet_TimeOut_Fehler 1 "Aktiver Timeout Fehlerspeichereintrag" ;
VAL_ 1788 NMH_Ladegeraet_CAN_Diag_deaktiv 1 "CAN Bus bezogene Eigendiagnose deaktiviert " ;
VAL_ 1788 NMH_Ladegeraet_KompSchutz 1 "KS aktiv" ;
VAL_ 1788 NMH_Ladegeraet_Mute_Mode 1 "Mute Mode aktiv" ;
VAL_ 1788 NMH_Ladegeraet_Transport_Mode 1 "Transportmodus aktiv" ;
VAL_ 1788 NMH_Ladegeraet_Abschaltstufe_000 1 "Funktionsabschaltung wegen Abschaltschaltstufe" ;
VAL_ 1788 NMH_Ladegeraet_Eindraht_Fehler 1 "Eindrahtbetrieb erkannt" ;
VAL_ 1788 NMH_Ladegeraet_Lokalaktiv 0 "war_nicht_lokal_aktiv" 1 "war_lokal_aktiv" ;
VAL_ 1788 NMH_Ladegeraet_Subsystemaktiv 0 "Subsystem war nicht lokalaktiv" 1 "war Lokalaktiv" ;
VAL_ 1483 PTC_Wassereinlasstemp 254 "Init" 255 "Fehler" ;
VAL_ 1483 PTC_Wasserauslasstemp 254 "Init" 255 "Fehler" ;
VAL_ 1483 PTC_HV_I_ist 254 "Init" 255 "Fehler" ;
VAL_ 1483 KL_T_Charge 0 "Taster nicht betaetigt" 1 "Taster betaetigt" ;
VAL_ 1483 KBT_Defrost_aktiv 0 "inaktiv" 1 "aktiv" ;
VAL_ 1483 KL_WunschStrom_HV 254 "Init" 255 "Fehler" ;
VAL_ 1483 KL_BattKond_WaPu_DZMax 62 "Init" 63 "Fehler" ;
VAL_ 1483 KL_Standklima_Status 0 "Standklimatisierung_aus" 1 "Standklimatisierung_ein" 2 "Nicht_moeglich_Aussenhuelle_offen" 3 "Abbruch_Aussenhuelle_geoeffnet" 4 "Nicht_moeglich_Keine_Aktivierung_HV_Bordnetz" 5 "Abbruch_HV_Bordnetz_deaktiviert" 6 "Nicht_moeglich_Batterie_Prio" 7 "On_hold_Keine_Freigabe_HV_Komponenten" ;
VAL_ 899 CHA_Ziel_FahrPr_BMS 0 "nicht_belegt" 1 "FahrPr_1" 2 "FahrPr_2" 3 "FahrPr_3" 4 "FahrPr_4" 5 "FahrPr_5" 6 "FahrPr_6" 7 "FahrPr_7" ;
VAL_ 1518 KL_T_STH 1 "Taster betätigt" 0 "Taster nicht betätigt" ;
VAL_ 1518 Klima_08_PAG_alt 0 "aktuell" 1 "veraltet" ;
VAL_ 391 MO_Tankbereitschaft_Status 0 "keine_Aktion_Init" 1 "Tankbereitschaft_wird_hergestellt" 2 "Tankbereitschaft_ist_hergestellt" 3 "Tankbereitschaft_kann_nicht_hergestellt_werden" 4 "Tanksystem_Systemfehler" 5 "Tankklappe_pruefen_schliessen" 6 "Tankvorgang_abgebrochen" ;
VAL_ 391 MO_Tankklappensteuerung 0 "Init_nicht_verbaut" 1 "Tankklappe_soll_entriegeln" 2 "Tankklappe_soll_verriegeln" 3 "keine_Aktion" ;
VAL_ 391 MO_HVEM_MaxLeistung 510 "Init" 511 "Fehler" ;
VAL_ 391 EV_Rekuperationsstufe 0 "keine_Anzeige" 1 "1" 2 "2" 3 "3" 4 "4" 5 "5" ;
VAL_ 391 MO_Waehlpos 0 "Init_nicht_unterstuetzt" 1 "reserviert" 2 "P" 3 "R" 4 "N" 5 "D" 6 "B" 7 "Fehler" ;
VAL_ 391 HV_Bordnetz_aktiv 0 "inaktiv" 1 "aktiv" ;
VAL_ 391 MO_HVEM_Eskalation 0 "keine_Eskalation_HVEM" 1 "Eskalation_HVEM" ;
VAL_ 1662 LAD_Abregelung_Temperatur 0 "keine_Begrenzung" 1 "Abregelung_Temp" ;
VAL_ 1662 LAD_Abregelung_IU_Ein_Aus 0 "keine_Abregelung" 1 "Abregelung_UI" ;
VAL_ 1662 LAD_Abregelung_BuchseTemp 0 "keine_Abregelung" 1 "Abregelung_Buchsentemp" ;
VAL_ 1662 LAD_MaxLadLeistung_HV 510 "Init" 511 "Fehler" ;
VAL_ 1662 LAD_CP_Stromlimit 126 "Init" 127 "Fehler" ;
VAL_ 1662 LAD_PRX_Stromlimit 0 "13_Ampere" 1 "20_Ampere" 2 "32_Ampere" 3 "63_Ampere" 6 "Init" 7 "Fehler" ;
VAL_ 1662 LAD_CP_Erkennung 0 "CP_nicht_erkannt" 1 "CP_erkannt" ;
VAL_ 1662 LAD_Stecker_Verriegelt 0 "nicht_verriegelt" 1 "verriegelt" ;
VAL_ 1662 LAD_Stecker_Gesteckt 0 "kein_Stecker_erkannt" 1 "Stecker_erkannt" ;
VAL_ 1662 LAD_Kuehlbedarf 0 "kein_Kuehlbedarf" 1 "geringer_Kuehlbedarf" 2 "mittlerer_Kuehlbedarf" 3 "hoher_Kuehlbedarf" ;
VAL_ 1662 LAD_Warnzustand 0 "keine_Warnung" 1 "Warnung_aktiv" ;
VAL_ 1662 LAD_Fehlerzustand 0 "kein_Fehler_aktiv" 1 "Fehler_aktiv_Laden_beendet" ;
VAL_ 1662 LAD_Fehlerstatus 0 "Komponente_IO" 1 "Eingeschr_KompFkt_DC_Lad_NIO" 2 "Eingeschr_KompFkt_AC_Lad_NIO" 3 "Eingeschr_KompFkt_Interlock" 4 "Eingeschr_KompFkt_reserve" 5 "Eingeschr_KompFkt_reserve" 6 "Keine_Komponentenfunktion" 7 "Init" ;
VAL_ 1662 LAD_Warnlampe_Anf 0 "Init" 1 "Fehlerlampe_gelb" ;
VAL_ 1380 LAD_IstModus 0 "Standby" 1 "Netzladung" 2 "ext_Steuerung" 5 "int_Fehler" 7 "Init" ;
VAL_ 1380 LAD_AC_Istspannung 510 "Init" 511 "Fehler" ;
VAL_ 1380 LAD_IstSpannung_HV 1022 "Init" 1023 "Fehler" ;
VAL_ 1380 LAD_IstStrom_HV 1022 "Init" 1023 "Fehler" ;
VAL_ 1380 LAD_Status_Spgfreiheit 0 "Init" 1 "HV_Komponente_spannungsfrei" 2 "HV_Komp_nicht_spannungsfrei" 3 "Fehler_nicht_spannungsfrei" ;
VAL_ 1380 LAD_Temperatur 254 "Init" 255 "Fehler" ;
VAL_ 1380 LAD_Verlustleistung 254 "Init" 255 "Fehler" ;
VAL_ 1385 HVEM_Abschaltstatus 0 "100" 1 "75" 2 "50" 3 "25" 7 "Init" ;
VAL_ 1385 HVEM_LeistunsAnf 0 "nicht_angefordert" 1 "angefordert" ;
VAL_ 1385 HVEM_Nachlad_Status 0 "nicht_moeglich__Fehler" 1 "moeglich__begonnen" 2 "Beendet" 3 "Init" ;
VAL_ 1385 HVEM_Anf_ReichweiteNV 0 "keine_Massnahme_notwendig" 1 "Reduktion_Stufe_1" 2 "Reduktion_Stufe_2" 3 "Fehler" ;
VAL_ 1385 HVEM_HV_Anf 0 "keine_Anforderung" 1 "HV_angefordert" ;
VAL_ 1385 HVEM_Text_1 0 "kein_Text" 1 "Text" ;
VAL_ 1385 HVEM_Nachladen_Anf 0 "keine_Anforderung" 1 "Nachladen_angefordert" ;
VAL_ 1385 HVEM_FreigabeKlimatisierung 0 "keine_Freigabe" 1 "Freigabe" 2 "Init" 3 "Fehler" ;
VAL_ 1482 BMS_Energieinhalt 2046 "Init" 2047 "Fehler" ;
VAL_ 1482 BMS_Ladevorgang_aktiv 0 "inaktiv" 1 "aktiv" ;
VAL_ 1482 BMS_MaxEnergieinhalt 2046 "Init" 2047 "Fehler" ;
VAL_ 1482 BMS_Ausgleichsladung_Anf 1 "Balancing_Request" ;
VAL_ 1482 BMS_Gesamtst_Spgfreiheit 0 "Funktion_nicht_aktiviert" 1 "HV_System_spannungsfrei" 2 "HV_System_nicht_spannungsfrei" 3 "Fehler_nicht_spannungsfrei" ;
VAL_ 1519 BMS_IstStrom 4094 "Init" 4095 "Fehler" ;
VAL_ 1519 BMS_PTC_Stufe 14 "Init" 15 "Fehler" ;
VAL_ 1519 BMS_PTC_IstStrom 254 "Init" 255 "Fehler" ;
VAL_ 1519 BMS_Status_Kuehlung 0 "Off" 1 "Umwaelzen zum Heizen" 2 "Umwaelzen zum Kuehlen" 3 "passive Kuehlung (NT-Kuehler und Chiller)" 4 "passive Kuehlung" 5 "passive Kuehlung mit Luefter" 6 "aktive Kuehlung (NT-Kuehlerund Chiller)" 7 "aktive Kuehlung (nur Chiller, Voll-Last)" 14 "Init" 15 "Fehler" ;
VAL_ 1519 BMS_Temp_Zelle_Min 254 "Init" 255 "Fehler" ;
VAL_ 1519 BMS_Temp_Zelle_Max 254 "Init" 255 "Fehler" ;
VAL_ 1519 BMS_Pumpendrehzahl 254 "Init" 255 "Fehler" ;
VAL_ 1519 BMS_Status_3_2_Ventil1 0 "Leitung NT-Kuehler und Chiller offen" 1 "Leitung NT-Kuehler offen, Chiller geschlossen" 2 "Leitung NT-Kuehler geschlossen, Chiller offen" 6 "Init" 7 "Fehler" ;
VAL_ 1519 BMS_Status_3_2_Ventil2 0 "Leitung NT-Kuehler und Chiller offen" 1 "Leitung NT-Kuehler offen, Chiller geschlossen" 2 "Leitung NT-Kuehler geschlossen, Chiller offen" 6 "Init" 7 "Fehler" ;
VAL_ 1438 BMS_Temperierung_Anf 0 "hoher_Kuehlbedarf" 1 "mittlerer_Kuehlbedarf" 2 "niedriger_Kuehlbedarf" 3 "kein_Temperierungsbedarf_Init" 4 "niedriger_Heizbedarf" 5 "mittlerer_Heizbedarf" 6 "hoher_Heizbedarf" 7 "Umwaelzungsbedarf" ;
VAL_ 1438 BMS_Soll_PWM_Pumpe 15 "Init" ;
VAL_ 1438 BMS_Temperatur 254 "Init" 255 "Fehler" ;
VAL_ 1438 BMS_IstVorlaufTemperatur 254 "Init" 255 "Fehler" ;
VAL_ 1438 BMS_SollVolumenstrom 62 "Init" 63 "Fehler" ;
VAL_ 1438 BMS_SollVorlauftemperatur 254 "Init" 255 "Fehler" ;
VAL_ 1438 BMS_IstRuecklaufTemperatur_02 254 "Init" 255 "Fehler" ;
VAL_ 1428 HVLM_HV_Anf 0 "keine_Anforderung" 1 "Laden_angefordert" 2 "Batteriekonditionierung_angefordert" 3 "Standklimatisierung_angefordert" ;
VAL_ 1428 HVLM_Stecker_Status 0 "Init" 1 "kein_Stecker_gesteckt" 2 "Stecker_erkannt_nicht_verriegelt" 3 "Stecker_erkannt_und_verriegelt" ;
VAL_ 1428 HVLM_Restladezeit_HV_Bat_02 510 "Init" 511 "Fehler" ;
VAL_ 1428 HVLM_Lademodus_HV_Bat 0 "Sofortlademodus" 1 "zeitversetztes_Laden" ;
VAL_ 1428 HVLM_Bat_laden_aktiv 0 "inaktiv" 1 "aktiv" ;
VAL_ 1428 HVLM_Ladeart 0 "keine_Anf" 1 "AC_Laden" 2 "DC_Laden" 3 "Konditionierung" ;
VAL_ 1428 HVLM_VK_Anf 0 "nicht_angefordert" 1 "angefordert" ;
VAL_ 1428 HVLM_Ladesystemhinweise 0 "kein_Hinweis" 1 "Ladesystem_defekt" 2 "Ladesaeule_inkompatibel" 3 "DC_Laden_nicht_moeglich" ;
VAL_ 1428 HVLM_Langzeit_Laden 0 "keine_Anforderung" 1 "Anforderung_Reduzierung_Batterie_SOC_auf_Stufe_1" 2 "Anforderung_Reduzierung_Batterie_SOC_auf_Stufe_2" 3 "Fehler" ;
VAL_ 1428 HVLM_Klima_Temp 29 "VW_high_30C" 30 "Init" 31 "Fehler" ;
VAL_ 1428 HVLM_VK_Modus 0 "keine Vorkonditionierung" 1 "Sofort-Konditionierung" 2 "zeitversetzte Konditionierung" 3 "Fehler" ;
VAL_ 1428 HVLM_HSH_Anf 0 "keine_Anforderung" 1 "Heckscheibenheizung_Anf" ;
VAL_ 305 MO_ePowermeter 0 "Init_keine_Anzeige" 254 "Funktion_deaktiv_Anzeige_ausgegraut" 255 "Fehler_keine_Anzeige" ;
VAL_ 305 MO_W_Reku_normiert_ueberlauf 1 "Rekuperationssignal_min_1_mal_uebergelaufen" 0 "kein_Ueberlauf" ;
VAL_ 305 Ladezustand 255 "Fehler" ;
VAL_ 305 Enrgfluss_State 1 "no_torques" 2 "pos_tor_EE" 3 "pos_tor_ICE" 4 "pos_tor_ICE_bat_charge" 5 "pos_tor_EE_ICE" 6 "neg_tor_EE_bar_charge" 7 "neg_tor_EE_bat_discharge" 8 "neg_tor_EE" 9 "ICE_charge_bat" 10 "neg_tor_EE_and_ICE" 11 "no_tor_sailing" 12 "no_tor_sailing_and_ICE" 255 "Fehler" ;
VAL_ 305 MO_Powermeter 4093 "Off" ;
VAL_ 914 ESP_OBD_Status 0 "MIL_aus" 1 "MIL_ein" ;
VAL_ 914 OBD_Fehler_Radsensor_VR 0 "kein_Fehler" 1 "KS- (Kurzschluss nach minus)" 2 "KS+ (Kurzschluss nach plus)" 3 "OC (Leitungsunterbrechung)" 4 "OOR+ (Signal zu gross)" 5 "OOR- (Signal zu klein)" 6 "RC+ (Signal unplausibel zu gross)" 7 "RC- (Signal unplausibel zu klein)" 8 "KS+/OC (Kurzschluss nach plus/Unterbrechung)" 9 "KS-/OC  (Kurzschluss nach minus/Unterbrechung)" 10 "KS-/KS+  (Kurzschluss nach minus/plus)" 11 "KS-/KS+/OC (Kurzschluss nach minus/plus/Unterbrechung)" 12 "frei" 13 "frei" 14 "frei" 15 "frei" ;
VAL_ 914 OBD_Fehler_Radsensor_VL 0 "kein_Fehler" 1 "KS- (Kurzschluss nach minus)" 2 "KS+ (Kurzschluss nach plus)" 3 "OC (Leitungsunterbrechung)" 4 "OOR+ (Signal zu gross)" 5 "OOR- (Signal zu klein)" 6 "RC+ (Signal unplausibel zu gross)" 7 "RC- (Signal unplausibel zu klein)" 8 "KS+/OC (Kurzschluss nach plus/Unterbrechung)" 9 "KS-/OC  (Kurzschluss nach minus/Unterbrechung)" 10 "KS-/KS+  (Kurzschluss nach minus/plus)" 11 "KS-/KS+/OC (Kurzschluss nach minus/plus/Unterbrechung)" 12 "frei" 13 "frei" 14 "frei" 15 "frei" ;
VAL_ 914 OBD_Fehler_Radsensor_HR 0 "kein_Fehler" 1 "KS- (Kurzschluss nach minus)" 2 "KS+ (Kurzschluss nach plus)" 3 "OC (Leitungsunterbrechung)" 4 "OOR+ (Signal zu gross)" 5 "OOR- (Signal zu klein)" 6 "RC+ (Signal unplausibel zu gross)" 7 "RC- (Signal unplausibel zu klein)" 8 "KS+/OC (Kurzschluss nach plus/Unterbrechung)" 9 "KS-/OC  (Kurzschluss nach minus/Unterbrechung)" 10 "KS-/KS+  (Kurzschluss nach minus/plus)" 11 "KS-/KS+/OC (Kurzschluss nach minus/plus/Unterbrechung)" 12 "frei" 13 "frei" 14 "frei" 15 "frei" ;
VAL_ 914 OBD_Fehler_Radsensor_HL 0 "kein_Fehler" 1 "KS- (Kurzschluss nach minus)" 2 "KS+ (Kurzschluss nach plus)" 3 "OC (Leitungsunterbrechung)" 4 "OOR+ (Signal zu gross)" 5 "OOR- (Signal zu klein)" 6 "RC+ (Signal unplausibel zu gross)" 7 "RC- (Signal unplausibel zu klein)" 8 "KS+/OC (Kurzschluss nach plus/Unterbrechung)" 9 "KS-/OC  (Kurzschluss nach minus/Unterbrechung)" 10 "KS-/KS+  (Kurzschluss nach minus/plus)" 11 "KS-/KS+/OC (Kurzschluss nach minus/plus/Unterbrechung)" 12 "frei" 13 "frei" 14 "frei" 15 "frei" ;
VAL_ 906 KL_Sportmodus 0 "Normal" 7 "Reserve" 1 "Sport 1" 3 "Reserve" 4 "Reserve" 2 "Sport 2" 6 "Reserve" 5 "Reserve" ;
VAL_ 906 KL_T_PSM_off 0 "Taste nicht betaetigt" 1 "Taste betaetigt" ;
VAL_ 906 F_Klima_08_PAG_Fwk 1 "veraltet" 0 "aktuell" ;
VAL_ 906 F_Klima_03_Ant 1 "veraltet" 0 "aktuell" ;
VAL_ 906 ESP_Rollenmodus 0 "Rollenmodus nicht aktiv" 1 "Rollenmodus aktiv" ;
VAL_ 906 KL_T_Abgasklappe 1 "Taster betätigt" 0 "Taster nicht betätigt" ;
VAL_ 906 KL_Magnetventil 1 "Wasserventil geschlossen" 0 "Wasserventil geoeffnet" ;
VAL_ 906 F_ESP_11_Ant 1 "veraltet" 0 "aktuell" ;
VAL_ 1731 NMH_ESP_Start_1 1 "Zustand Start (<--Sleep)" ;
VAL_ 1731 NMH_ESP_Start_2 1 "Zustand Start (<--Prepare to Sle" ;
VAL_ 1731 NMH_ESP_Normal_Mode_1 1 "Zustand Normal Mode (<-- Start)" ;
VAL_ 1731 NMH_ESP_Normal_Mode_2 1 "Zustand Normal Mode (<-- Ready t" ;
VAL_ 1731 NMH_ESP_Per_WakeUp 3 "Klemme 15 HW (falls vorhanden)" 0 "Wenn Funktions-Wakeup" 1 "CAN-Wakeup" 2 "Periphrie-Wakeup Ursache nicht b" ;
VAL_ 1731 NMH_ESP_Fkt_WakeUp 0 "wenn Peripheriewakeup" ;
VAL_ 1731 NMH_ESP_NM_aktiv_Klemme_15 1 "Klemme 15 EIN" ;
VAL_ 1731 NMH_ESP_NM_aktiv_Diagnose 1 "Diagnose bei Kl 15 aus" ;
VAL_ 1731 NMH_ESP_NM_aktiv_Start 1 "Zustand 'START' (NM-high)" ;
VAL_ 1731 NMH_ESP_NM_aktiv_v_groesser_Null 1 "v > 0" ;
VAL_ 1731 NMH_ESP_Mindestaktivzeit 1 "aktiv" ;
VAL_ 1731 NMH_ESP_kein_NL 1 "kein lokaler Nachlauf" ;
VAL_ 1731 NMH_ESP_NL_Daten_EEPROM 1 "EEPROM Datenspeicherung" ;
VAL_ 1731 NMH_ESP_TimeOut_Fehler 1 "Aktiver Timeout Fehlerspeicherei" ;
VAL_ 1731 NMH_ESP_CAN_Diag_deaktiv 1 "CAN-Diagnose deaktiv" ;
VAL_ 1731 NMH_ESP_KompSchutz 1 "KS aktiv" ;
VAL_ 1731 NMH_ESP_Mute_Mode 1 "MuteMode aktiv" ;
VAL_ 1731 NMH_ESP_Transport_Mode 1 "Transportmodus aktiv" ;
VAL_ 1731 NMH_ESP_Abschaltstufe_aktiv 1 "Abschaltstufe aktiv" ;
VAL_ 1731 NMH_ESP_Eindraht_Fehler 1 "Eindrahtbetrieb erkannt" ;
VAL_ 1731 NMH_ESP_Lokalaktiv 1 "war Lokalaktiv" 0 "war nicht Lokalaktiv" ;
VAL_ 1731 NMH_ESP_Subsystemaktiv 1 "war Lokalaktiv" 0 "Subsystem war nicht lokalaktiv" ;
VAL_ 946 BEM_NV_NachladAnf 0 "keine_Anforderung" 1 "Anforderung_NV_Nachladung" 2 "Init" 3 "Fehler" ;
VAL_ 946 BEM_Freigabe_HV_Ladung 0 "HV_Ladung_nicht_freigegeben" 1 "HV_Ladung_freigegeben" ;
VAL_ 1628 BMS_IstSpannung_HV 255 "Fehler" ;
VAL_ 1628 BMS_Temperatur_Ansaugluft 254 "Init" 255 "Fehler" ;
VAL_ 1628 BMS_Temperatur 254 "Init" 255 "Fehler" ;
VAL_ 1628 BMS_HYB_Spuelbetrieb_Status 0 "Umluftbetrieb" 1 "Spuelbetrieb" ;
VAL_ 1628 BMS_HYB_Temp_vor_Verd 254 "Init" 255 "Fehler" ;
VAL_ 1628 BMS_HYB_Temp_nach_Verd 254 "Init" 255 "Fehler" ;
VAL_ 1628 BMS_HYB_Kuehlung_Anf 2 "aktive_Kuehlung_Stufe_2" 3 "Kuehlung_max" 0 "keine_Kuehlanforderung" 1 "aktive_Kuehlung_Stufe_1" ;
VAL_ 1628 BMS_HYB_ASV_vorne_Status 0 "Ventil_offen" 1 "Ventil_geschlossen" ;
VAL_ 1628 BMS_HYB_ASV_hinten_Status 0 "Ventil_offen" 1 "Ventil_geschlossen" ;
VAL_ 1628 BMS_HYB_KD_Fehler 1 "mind. ein KD-Fehler vorhanden" 0 "kein KD-Fehler" ;
VAL_ 1628 BMS_HYB_BattFanSpd 14 "Init" 15 "Fehler" ;
VAL_ 1628 BMS_HYB_VentilationReq 1 "Ventilation_Request" ;
VAL_ 945 DC_TiefsetzBereit 0 "Standby" 1 "Tiefsetzbereit" ;
VAL_ 945 DC_HYB_iAktLV 1022 "Init" 1023 "Fehler" ;
VAL_ 945 DC_HYB_iAktReserveLV 1022 "Init" 1023 "Fehler" ;
VAL_ 945 DC_HYB_uAktLV 254 "Init" 255 "Fehler" ;
VAL_ 945 DC_HYB_LangsRegelung 0 "normale_Regelung" 1 "langsame_Regelung" ;
VAL_ 945 DC_HYB_Abregelung_Temperatur 0 "keine_Begrenzung" 1 "Abregelung_Temperatur" ;
VAL_ 945 DC_HYB_Fehler_RedLeistung 0 "kein_Fehler" 1 "Fehler_RedLeistung" ;
VAL_ 945 DC_HYB_Fehler_intern 0 "kein_Fehler" 1 "Fehler_intern" ;
VAL_ 945 DC_HYB_Fehler_Spannung 0 "kein_Fehler" 1 "Fehler_Spannung" ;
VAL_ 945 DC_Verbrauch_Ueberlauf 0 "kein_Ueberlauf" 1 "Ueberlauf" ;
VAL_ 945 DC_HYB_Auslastungsgrad 254 "Initwert" 255 "Fehler" ;
VAL_ 1627 EM_HYB_KD_Fehler 0 "kein_KD_Fehler" 1 "KD_Fehler" ;
VAL_ 256 ESP_v_Signal 65534 "Init" 65533 "Unterspannung" 65535 "Fehler" ;
VAL_ 256 ASR_Moment_langsam 1022 "Init" 1023 "Fehler" ;
VAL_ 256 ASR_MSR_Moment_schnell 1022 "Init" 1023 "Fehler" ;
VAL_ 256 ASR_Tastung_passiv 1 "ASR_passiv_getastet" 0 "ASR_aktiviert" ;
VAL_ 256 ESP_Tastung_passiv 1 "ESP passiv getastet" 0 "ESP aktiviert" ;
VAL_ 256 ESP_Systemstatus 0 "iO" 1 "Fehler" ;
VAL_ 256 ASR_Schalteingriff 0 "keine Anforderung" 3 "Schaltverbot" 2 "Rückschaltung" 1 "ASR_Schaltkennfeld" ;
VAL_ 256 OBD_Schlechtweg 1 "Schlechtweg erkannt" 0 "kein Schlechtweg erkannt" ;
VAL_ 256 OBD_QBit_Schlechtweg 0 "gueltiger_Wert" 1 "Ersatz_Init_oder_Fehlerwert" ;
VAL_ 256 ESP_QBit_v_Signal 0 "gueltiger_Wert" 1 "Ersatz_Init_oder_Fehlerwert" ;
VAL_ 256 ABS_Bremsung 1 "ABS_Regelung_aktiv" 0 "keine_ABS_Regelung" ;
VAL_ 256 ASR_Anf 1 "ASR_Anforderung" 0 "keine_Anforderung" ;
VAL_ 256 MSR_Anf 0 "keine Anfoderung" 1 "MSR-Anforderung" ;
VAL_ 256 EBV_Eingriff 0 "kein EBV-Eingriff" 1 "EBV-Eingriff" ;
VAL_ 256 EDS_Eingriff 1 "EDS-Eingriff" 0 "kein EDS-Eingriff" ;
VAL_ 256 ESP_Eingriff 1 "ESP_Eingriff_aktiv" 0 "kein_ESP_Eingriff" ;
VAL_ 256 ESP_ASP 1 "ASP_aktiv" 0 "ASP_inaktiv" ;
VAL_ 256 ESP_KD_Fehler 1 "KD_Fehler" 0 "kein_KD_Fehler" ;
VAL_ 257 ESP_QBit_Gierrate 0 "gueltiger_Wert" 1 "Ersatz_Init_oder_Fehlerwert" ;
VAL_ 257 ESP_QBit_Laengsbeschl 0 "gueltiger_Wert" 1 "Ersatz_Init_oder_Fehlerwert" ;
VAL_ 257 ESP_QBit_Querb 0 "gueltiger_Wert" 1 "Ersatz_Init_oder_Fehlerwert" ;
VAL_ 257 ESP_Stillstandsflag 0 "kein Stillstand erkannt" 1 "Stillstand erkannt" ;
VAL_ 257 ESP_Querbeschleunigung 255 "Fehler" ;
VAL_ 257 ESP_Laengsbeschl 1022 "Signal_nicht_vorhanden" 1023 "Fehler" ;
VAL_ 257 ESP_Verteil_Wankmom 30 "Init" 31 "Fehler" ;
VAL_ 257 ESP_QBit_Anf_Vert_Wank 0 "gueltiger_Wert" 1 "Ersatz_Init_oder_Fehlerwert" ;
VAL_ 257 ESP_Gierrate 16383 "Fehler" ;
VAL_ 257 ESP_VZ_Gierrate 1 "negativ" 0 "positiv" ;
VAL_ 257 ESP_Notbremsanzeige 0 "keine_Notbremsung_erkannt" 1 "Notbremsung_erkannt" ;
VAL_ 257 ESP_SpannungsAnf 1 "Anforderung Spannungswert 1" 0 "keine Anforderung" ;
VAL_ 259 ESP_VL_FR 0 "Vorwaerts" 1 "Rueckwaerts" ;
VAL_ 259 ESP_VR_FR 0 "Vorwaerts" 1 "Rueckwaerts" ;
VAL_ 259 ESP_HL_FR 0 "Vorwaerts" 1 "Rueckwaerts" ;
VAL_ 259 ESP_HR_FR 1 "Rueckwaerts" 0 "Vorwaerts" ;
VAL_ 259 ESP_VL_Radgeschw 4093 "Unterspannung" 4094 "Init" 4095 "Fehler" ;
VAL_ 259 ESP_VR_Radgeschw 4094 "Init" 4093 "Unterspannung" 4095 "Fehler" ;
VAL_ 259 ESP_HL_Radgeschw 4094 "Init" 4093 "Unterspannung" 4095 "Fehler" ;
VAL_ 259 ESP_HR_Radgeschw 4094 "Init" 4093 "Unterspannung" 4095 "Fehler" ;
VAL_ 776 ESP_HDC_FktLampe 0 "Aus" 1 "Ein" ;
VAL_ 776 ESP_ASR_Lampe 0 "ESP_ASR_Lampe_aus" 1 "ESP_ASR_Lampe_an" ;
VAL_ 776 ESP_Meldungen 0 "keine_Anzeige_kein_Gong" 3 "Stoerung_Hillholder_und_1x_Gong" 1 "Autohold_Hinweis_1_und_kein_Gong" 2 "Stoerung_Autohold_und_1x_Gong" 4 "Uebernehmen_und_1x_Gong" ;
VAL_ 776 ESP_Lampe 0 "Aus" 1 "Ein" ;
VAL_ 776 ABS_Lampe 0 "Aus" 1 "Ein" ;
VAL_ 776 BK_Lampe 0 "Aus" 1 "Ein" ;
VAL_ 776 ESP_Akustik 0 "keine_Akustik" 1 "1x_Beep" ;
VAL_ 776 ESP_Diagnose 1 "ESP_in_Diagnose" 0 "ESP_nicht_in_Diagnose" ;
VAL_ 776 ESP_Textanzeigen_02 1 "ESP_Stoerung" 7 "ASR_off" 6 "ESP_switched_off" 10 "keine_Bremskraftverstaerkung" 3 "ESP_ABS_Stoerung" 0 "kein_Text" 8 "ESP_ASR_on" 5 "ASR_Stoerung" 9 "Stoerung_Hillholder" 2 "ABS_Stoerung" 15 "ESP_offroad" 16 "Autohold_Hinweis_1" 12 "ABS_ASR_Stoerung" 14 "Stoerung_Autohold" 11 "ASR_aktiviert" 13 "bitte_Reifen_pruefen" 4 "nicht_definiert" 17 "ESP_sport" ;
VAL_ 776 ESP_Off_Lampe 1 "Lampe_ein" 0 "Lampe_aus" ;
VAL_ 776 ESP_m_Raddrehz 32766 "Init" 32765 "Unterspannung" 32767 "Fehler" ;
VAL_ 776 ESP_Fehlerstatus_Wegimp 1 "Fehler" 0 "Wegimpulse_iO" ;
VAL_ 776 ESP_Wegimp_Ueberlauf 0 "Reset und kein Überlauf" 1 "mindestens 1x Überlauf" ;
VAL_ 776 ESP_QBit_Wegimp_VA 0 "gueltiger_Wert" 1 "Ersatz_Init_oder_Fehlerwert" ;
VAL_ 776 ESP_Displaywarnungen 1 "BKL_Display_Warnung" 0 "keine_Warnung" ;
VAL_ 776 ESP_HDC_Regelgeschw 0 "nicht_verbaut" 125 "HDC_Standby" 127 "Fehler" ;
VAL_ 776 ESP_BKV_Warnung 1 "keine_Bremskraftverstaerkung_plu" 0 "keine_Anzeige_kein_Gong" ;
